VERSION "WangHu V1.0"

NS_ :

BS_:

BU_: SBCU MBCU Tester Monitor01

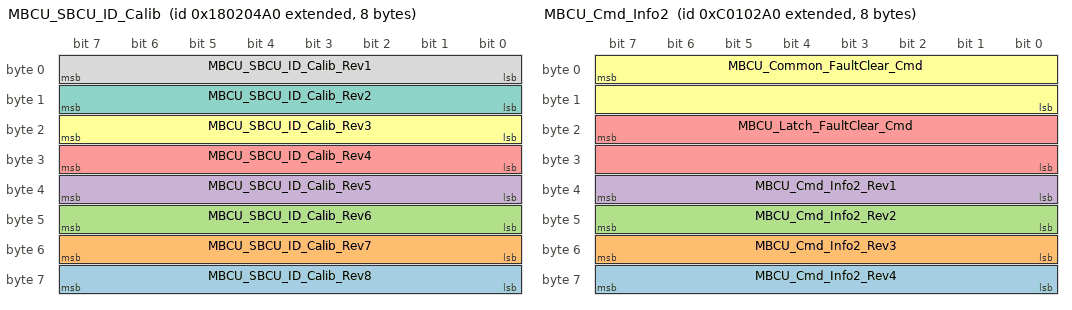
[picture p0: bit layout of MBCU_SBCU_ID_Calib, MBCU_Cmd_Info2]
BO_ 2550269088 MBCU_SBCU_ID_Calib: 8 MBCU
 SG_ MBCU_SBCU_ID_Calib_Rev8 : 63|8@0+ (1,0) [0|0] ""  SBCU
 SG_ MBCU_SBCU_ID_Calib_Rev7 : 55|8@0+ (1,0) [0|0] ""  SBCU
 SG_ MBCU_SBCU_ID_Calib_Rev6 : 47|8@0+ (1,0) [0|0] ""  SBCU
 SG_ MBCU_SBCU_ID_Calib_Rev5 : 39|8@0+ (1,0) [0|0] ""  SBCU
 SG_ MBCU_SBCU_ID_Calib_Rev4 : 31|8@0+ (1,0) [0|0] ""  SBCU
 SG_ MBCU_SBCU_ID_Calib_Rev3 : 23|8@0+ (1,0) [0|0] ""  SBCU
 SG_ MBCU_SBCU_ID_Calib_Rev2 : 15|8@0+ (1,0) [0|0] ""  SBCU
 SG_ MBCU_SBCU_ID_Calib_Rev1 : 7|8@0+ (1,0) [0|0] ""  SBCU

BO_ 2348876448 MBCU_Cmd_Info2: 8 MBCU
 SG_ MBCU_Cmd_Info2_Rev4 : 63|8@0+ (1,0) [0|255] ""  SBCU
 SG_ MBCU_Cmd_Info2_Rev3 : 55|8@0+ (1,0) [0|255] ""  SBCU
 SG_ MBCU_Cmd_Info2_Rev2 : 47|8@0+ (1,0) [0|255] ""  SBCU
 SG_ MBCU_Cmd_Info2_Rev1 : 39|8@0+ (1,0) [0|255] ""  SBCU
 SG_ MBCU_Latch_FaultClear_Cmd : 23|16@0+ (1,0) [0|65535] ""  SBCU
 SG_ MBCU_Common_FaultClear_Cmd : 7|16@0+ (1,0) [0|65535] ""  SBCU

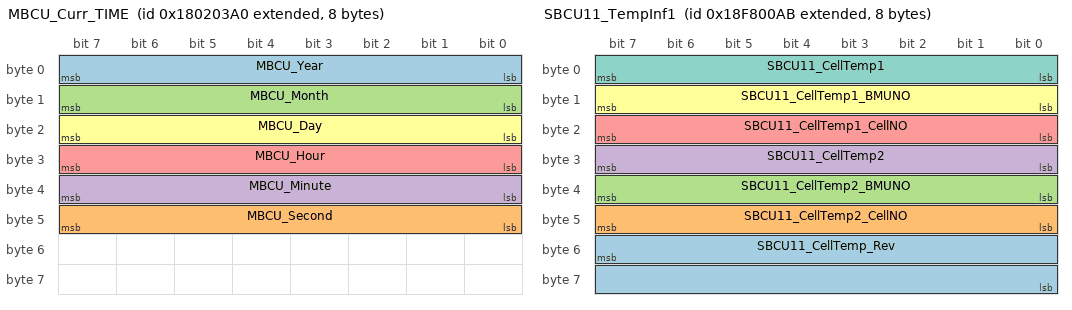
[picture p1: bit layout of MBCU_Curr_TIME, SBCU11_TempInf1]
BO_ 2550268832 MBCU_Curr_TIME: 8 MBCU
 SG_ MBCU_Year : 7|8@0+ (1,1900) [1900|2155] ""  SBCU
 SG_ MBCU_Second : 47|8@0+ (1,0) [0|59] ""  SBCU
 SG_ MBCU_Month : 15|8@0+ (1,0) [0|12] ""  SBCU
 SG_ MBCU_Minute : 39|8@0+ (1,0) [0|59] ""  SBCU
 SG_ MBCU_Hour : 31|8@0+ (1,0) [0|23] ""  SBCU
 SG_ MBCU_Day : 23|8@0+ (1,0) [0|31] ""  SBCU

BO_ 2566389931 SBCU11_TempInf1: 8 SBCU
 SG_ SBCU11_CellTemp_Rev : 55|16@0+ (1,0) [0|65535] ""  MBCU
 SG_ SBCU11_CellTemp2_CellNO : 47|8@0+ (1,0) [0|0] ""  MBCU
 SG_ SBCU11_CellTemp2_BMUNO : 39|8@0+ (1,0) [0|0] ""  MBCU
 SG_ SBCU11_CellTemp2 : 31|8@0+ (1,-40) [0|0] "��"  MBCU
 SG_ SBCU11_CellTemp1_CellNO : 23|8@0+ (1,0) [0|0] ""  MBCU
 SG_ SBCU11_CellTemp1_BMUNO : 15|8@0+ (1,0) [0|0] ""  MBCU
 SG_ SBCU11_CellTemp1 : 7|8@0+ (1,-40) [0|0] "��"  MBCU

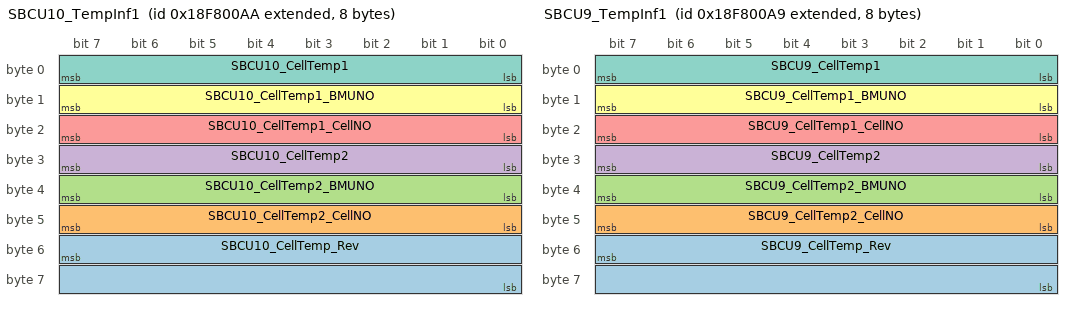
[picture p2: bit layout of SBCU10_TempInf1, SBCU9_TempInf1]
BO_ 2566389930 SBCU10_TempInf1: 8 SBCU
 SG_ SBCU10_CellTemp_Rev : 55|16@0+ (1,0) [0|65535] ""  MBCU
 SG_ SBCU10_CellTemp2_CellNO : 47|8@0+ (1,0) [0|0] ""  MBCU
 SG_ SBCU10_CellTemp2_BMUNO : 39|8@0+ (1,0) [0|0] ""  MBCU
 SG_ SBCU10_CellTemp2 : 31|8@0+ (1,-40) [0|0] "��"  MBCU
 SG_ SBCU10_CellTemp1_CellNO : 23|8@0+ (1,0) [0|0] ""  MBCU
 SG_ SBCU10_CellTemp1_BMUNO : 15|8@0+ (1,0) [0|0] ""  MBCU
 SG_ SBCU10_CellTemp1 : 7|8@0+ (1,-40) [0|0] "��"  MBCU

BO_ 2566389929 SBCU9_TempInf1: 8 SBCU
 SG_ SBCU9_CellTemp_Rev : 55|16@0+ (1,0) [0|65535] ""  MBCU
 SG_ SBCU9_CellTemp2_CellNO : 47|8@0+ (1,0) [0|0] ""  MBCU
 SG_ SBCU9_CellTemp2_BMUNO : 39|8@0+ (1,0) [0|0] ""  MBCU
 SG_ SBCU9_CellTemp2 : 31|8@0+ (1,-40) [0|0] "��"  MBCU
 SG_ SBCU9_CellTemp1_CellNO : 23|8@0+ (1,0) [0|0] ""  MBCU
 SG_ SBCU9_CellTemp1_BMUNO : 15|8@0+ (1,0) [0|0] ""  MBCU
 SG_ SBCU9_CellTemp1 : 7|8@0+ (1,-40) [0|0] "��"  MBCU

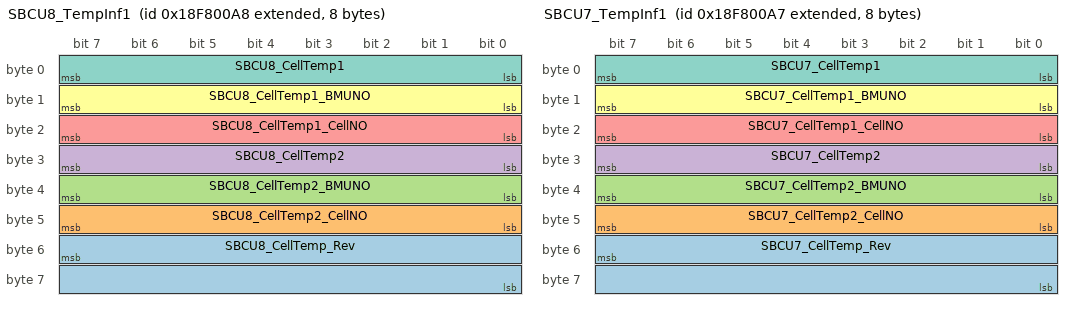
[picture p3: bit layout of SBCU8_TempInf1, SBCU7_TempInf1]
BO_ 2566389928 SBCU8_TempInf1: 8 SBCU
 SG_ SBCU8_CellTemp_Rev : 55|16@0+ (1,0) [0|65535] ""  MBCU
 SG_ SBCU8_CellTemp2_CellNO : 47|8@0+ (1,0) [0|0] ""  MBCU
 SG_ SBCU8_CellTemp2_BMUNO : 39|8@0+ (1,0) [0|0] ""  MBCU
 SG_ SBCU8_CellTemp2 : 31|8@0+ (1,-40) [0|0] "��"  MBCU
 SG_ SBCU8_CellTemp1_CellNO : 23|8@0+ (1,0) [0|0] ""  MBCU
 SG_ SBCU8_CellTemp1_BMUNO : 15|8@0+ (1,0) [0|0] ""  MBCU
 SG_ SBCU8_CellTemp1 : 7|8@0+ (1,-40) [0|0] "��"  MBCU

BO_ 2566389927 SBCU7_TempInf1: 8 SBCU
 SG_ SBCU7_CellTemp_Rev : 55|16@0+ (1,0) [0|65535] ""  MBCU
 SG_ SBCU7_CellTemp2_CellNO : 47|8@0+ (1,0) [0|0] ""  MBCU
 SG_ SBCU7_CellTemp2_BMUNO : 39|8@0+ (1,0) [0|0] ""  MBCU
 SG_ SBCU7_CellTemp2 : 31|8@0+ (1,-40) [0|0] "��"  MBCU
 SG_ SBCU7_CellTemp1_CellNO : 23|8@0+ (1,0) [0|0] ""  MBCU
 SG_ SBCU7_CellTemp1_BMUNO : 15|8@0+ (1,0) [0|0] ""  MBCU
 SG_ SBCU7_CellTemp1 : 7|8@0+ (1,-40) [0|0] "��"  MBCU

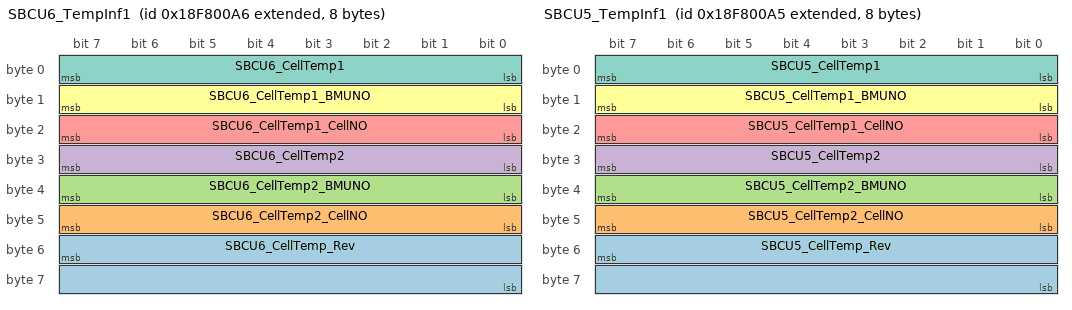
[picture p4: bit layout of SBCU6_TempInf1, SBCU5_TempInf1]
BO_ 2566389926 SBCU6_TempInf1: 8 SBCU
 SG_ SBCU6_CellTemp_Rev : 55|16@0+ (1,0) [0|65535] ""  MBCU
 SG_ SBCU6_CellTemp2_CellNO : 47|8@0+ (1,0) [0|0] ""  MBCU
 SG_ SBCU6_CellTemp2_BMUNO : 39|8@0+ (1,0) [0|0] ""  MBCU
 SG_ SBCU6_CellTemp2 : 31|8@0+ (1,-40) [0|0] "��"  MBCU
 SG_ SBCU6_CellTemp1_CellNO : 23|8@0+ (1,0) [0|0] ""  MBCU
 SG_ SBCU6_CellTemp1_BMUNO : 15|8@0+ (1,0) [0|0] ""  MBCU
 SG_ SBCU6_CellTemp1 : 7|8@0+ (1,-40) [0|0] "��"  MBCU

BO_ 2566389925 SBCU5_TempInf1: 8 SBCU
 SG_ SBCU5_CellTemp_Rev : 55|16@0+ (1,0) [0|65535] ""  MBCU
 SG_ SBCU5_CellTemp2_CellNO : 47|8@0+ (1,0) [0|0] ""  MBCU
 SG_ SBCU5_CellTemp2_BMUNO : 39|8@0+ (1,0) [0|0] ""  MBCU
 SG_ SBCU5_CellTemp2 : 31|8@0+ (1,-40) [0|0] "��"  MBCU
 SG_ SBCU5_CellTemp1_CellNO : 23|8@0+ (1,0) [0|0] ""  MBCU
 SG_ SBCU5_CellTemp1_BMUNO : 15|8@0+ (1,0) [0|0] ""  MBCU
 SG_ SBCU5_CellTemp1 : 7|8@0+ (1,-40) [0|0] "��"  MBCU

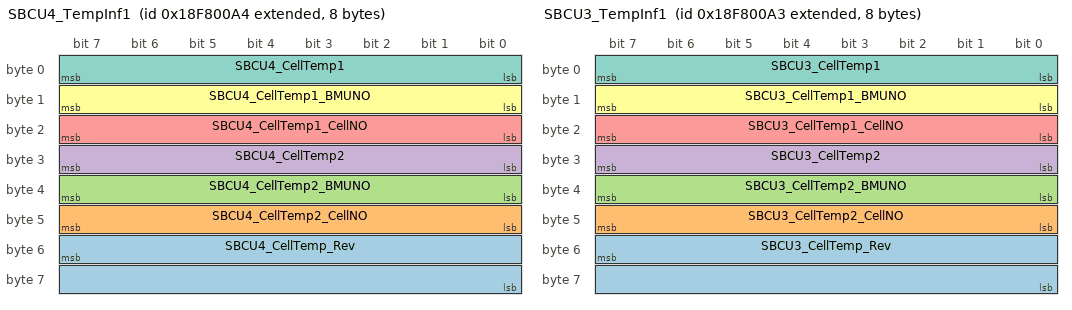
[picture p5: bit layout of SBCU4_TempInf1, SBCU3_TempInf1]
BO_ 2566389924 SBCU4_TempInf1: 8 SBCU
 SG_ SBCU4_CellTemp_Rev : 55|16@0+ (1,0) [0|65535] ""  MBCU
 SG_ SBCU4_CellTemp2_CellNO : 47|8@0+ (1,0) [0|0] ""  MBCU
 SG_ SBCU4_CellTemp2_BMUNO : 39|8@0+ (1,0) [0|0] ""  MBCU
 SG_ SBCU4_CellTemp2 : 31|8@0+ (1,-40) [0|0] "��"  MBCU
 SG_ SBCU4_CellTemp1_CellNO : 23|8@0+ (1,0) [0|0] ""  MBCU
 SG_ SBCU4_CellTemp1_BMUNO : 15|8@0+ (1,0) [0|0] ""  MBCU
 SG_ SBCU4_CellTemp1 : 7|8@0+ (1,-40) [0|0] "��"  MBCU

BO_ 2566389923 SBCU3_TempInf1: 8 SBCU
 SG_ SBCU3_CellTemp_Rev : 55|16@0+ (1,0) [0|65535] ""  MBCU
 SG_ SBCU3_CellTemp2_CellNO : 47|8@0+ (1,0) [0|0] ""  MBCU
 SG_ SBCU3_CellTemp2_BMUNO : 39|8@0+ (1,0) [0|0] ""  MBCU
 SG_ SBCU3_CellTemp2 : 31|8@0+ (1,-40) [0|0] "��"  MBCU
 SG_ SBCU3_CellTemp1_CellNO : 23|8@0+ (1,0) [0|0] ""  MBCU
 SG_ SBCU3_CellTemp1_BMUNO : 15|8@0+ (1,0) [0|0] ""  MBCU
 SG_ SBCU3_CellTemp1 : 7|8@0+ (1,-40) [0|0] "��"  MBCU

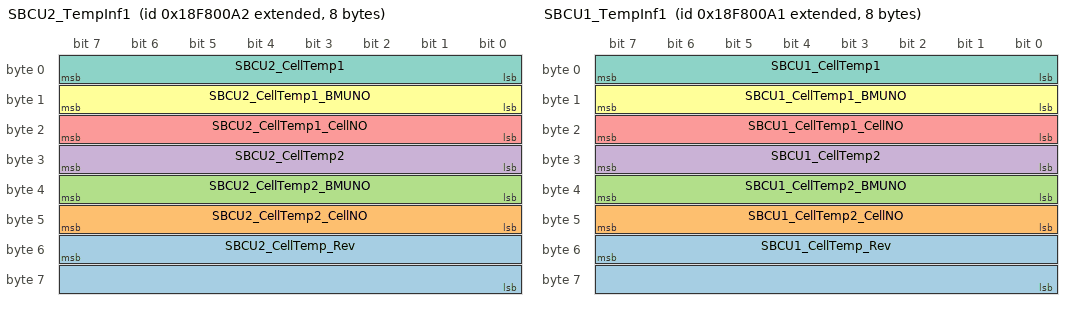
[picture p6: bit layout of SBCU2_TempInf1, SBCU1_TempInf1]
BO_ 2566389922 SBCU2_TempInf1: 8 SBCU
 SG_ SBCU2_CellTemp_Rev : 55|16@0+ (1,0) [0|65535] ""  MBCU
 SG_ SBCU2_CellTemp2_CellNO : 47|8@0+ (1,0) [0|0] ""  MBCU
 SG_ SBCU2_CellTemp2_BMUNO : 39|8@0+ (1,0) [0|0] ""  MBCU
 SG_ SBCU2_CellTemp2 : 31|8@0+ (1,-40) [0|0] "��"  MBCU
 SG_ SBCU2_CellTemp1_CellNO : 23|8@0+ (1,0) [0|0] ""  MBCU
 SG_ SBCU2_CellTemp1_BMUNO : 15|8@0+ (1,0) [0|0] ""  MBCU
 SG_ SBCU2_CellTemp1 : 7|8@0+ (1,-40) [0|0] "��"  MBCU

BO_ 2566389921 SBCU1_TempInf1: 8 SBCU
 SG_ SBCU1_CellTemp_Rev : 55|16@0+ (1,0) [0|65535] ""  MBCU
 SG_ SBCU1_CellTemp2_CellNO : 47|8@0+ (1,0) [0|0] ""  MBCU
 SG_ SBCU1_CellTemp2_BMUNO : 39|8@0+ (1,0) [0|0] ""  MBCU
 SG_ SBCU1_CellTemp2 : 31|8@0+ (1,-40) [0|0] "��"  MBCU
 SG_ SBCU1_CellTemp1_CellNO : 23|8@0+ (1,0) [0|0] ""  MBCU
 SG_ SBCU1_CellTemp1_BMUNO : 15|8@0+ (1,0) [0|0] ""  MBCU
 SG_ SBCU1_CellTemp1 : 7|8@0+ (1,-40) [0|0] "��"  MBCU

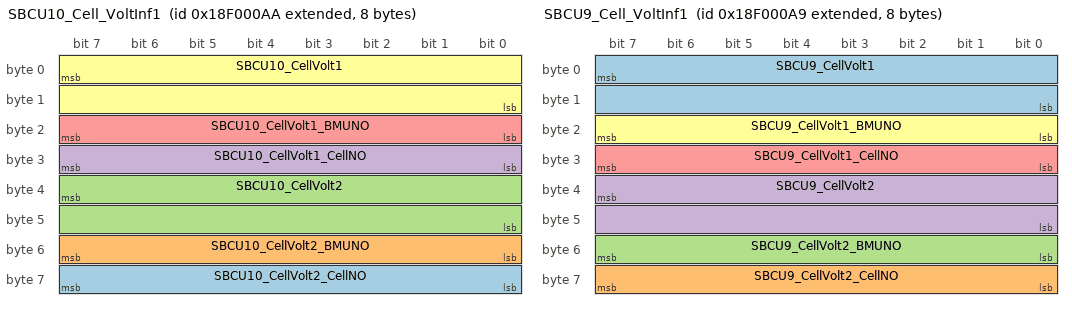
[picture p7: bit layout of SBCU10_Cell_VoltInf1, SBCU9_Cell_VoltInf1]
BO_ 2565865642 SBCU10_Cell_VoltInf1: 8 SBCU
 SG_ SBCU10_CellVolt2_CellNO : 63|8@0+ (1,0) [0|0] ""  MBCU
 SG_ SBCU10_CellVolt2_BMUNO : 55|8@0+ (1,0) [0|0] ""  MBCU
 SG_ SBCU10_CellVolt2 : 39|16@0+ (0.001,0) [0|0] "V"  MBCU
 SG_ SBCU10_CellVolt1_CellNO : 31|8@0+ (1,0) [0|0] ""  MBCU
 SG_ SBCU10_CellVolt1_BMUNO : 23|8@0+ (1,0) [0|0] ""  MBCU
 SG_ SBCU10_CellVolt1 : 7|16@0+ (0.001,0) [0|0] "V"  MBCU

BO_ 2565865641 SBCU9_Cell_VoltInf1: 8 SBCU
 SG_ SBCU9_CellVolt1 : 7|16@0+ (0.001,0) [0|0] "V"  MBCU
 SG_ SBCU9_CellVolt2_CellNO : 63|8@0+ (1,0) [0|0] ""  MBCU
 SG_ SBCU9_CellVolt2_BMUNO : 55|8@0+ (1,0) [0|0] ""  MBCU
 SG_ SBCU9_CellVolt2 : 39|16@0+ (0.001,0) [0|0] "V"  MBCU
 SG_ SBCU9_CellVolt1_CellNO : 31|8@0+ (1,0) [0|0] ""  MBCU
 SG_ SBCU9_CellVolt1_BMUNO : 23|8@0+ (1,0) [0|0] ""  MBCU

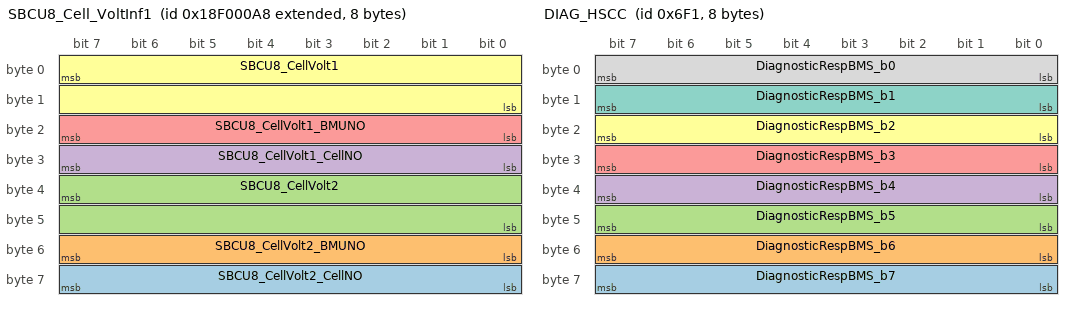
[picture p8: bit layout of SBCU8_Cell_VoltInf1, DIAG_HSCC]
BO_ 2565865640 SBCU8_Cell_VoltInf1: 8 SBCU
 SG_ SBCU8_CellVolt2_CellNO : 63|8@0+ (1,0) [0|0] ""  MBCU
 SG_ SBCU8_CellVolt2_BMUNO : 55|8@0+ (1,0) [0|0] ""  MBCU
 SG_ SBCU8_CellVolt2 : 39|16@0+ (0.001,0) [0|0] "V"  MBCU
 SG_ SBCU8_CellVolt1_CellNO : 31|8@0+ (1,0) [0|0] ""  MBCU
 SG_ SBCU8_CellVolt1_BMUNO : 23|8@0+ (1,0) [0|0] ""  MBCU
 SG_ SBCU8_CellVolt1 : 7|16@0+ (0.001,0) [0|0] "V"  MBCU

BO_ 2565865639 SBCU7_Cell_VoltInf1: 8 SBCU
 SG_ SBCU7_CellVolt2_CellNO : 63|8@0+ (1,0) [0|0] ""  MBCU
 SG_ SBCU7_CellVolt2_BMUNO : 55|8@0+ (1,0) [0|0] ""  MBCU
 SG_ SBCU7_CellVolt2 : 39|16@0+ (0.001,0) [0|0] "V"  MBCU
 SG_ SBCU7_CellVolt1_CellNO : 31|8@0+ (1,0) [0|0] ""  MBCU
 SG_ SBCU7_CellVolt1_BMUNO : 23|8@0+ (1,0) [0|0] ""  MBCU
 SG_ SBCU7_CellVolt1 : 7|16@0+ (0.001,0) [0|0] "V"  MBCU

BO_ 2565865638 SBCU6_Cell_VoltInf1: 8 SBCU
 SG_ SBCU6_CellVolt2_CellNO : 63|8@0+ (1,0) [0|0] ""  MBCU
 SG_ SBCU6_CellVolt2_BMUNO : 55|8@0+ (1,0) [0|0] ""  MBCU
 SG_ SBCU6_CellVolt2 : 39|16@0+ (0.001,0) [0|0] "V"  MBCU
 SG_ SBCU6_CellVolt1_CellNO : 31|8@0+ (1,0) [0|0] ""  MBCU
 SG_ SBCU6_CellVolt1_BMUNO : 23|8@0+ (1,0) [0|0] ""  MBCU
 SG_ SBCU6_CellVolt1 : 7|16@0+ (0.001,0) [0|0] "V"  MBCU

BO_ 2565865637 SBCU5_Cell_VoltInf1: 8 SBCU
 SG_ SBCU5_CellVolt2_CellNO : 63|8@0+ (1,0) [0|0] ""  MBCU
 SG_ SBCU5_CellVolt2_BMUNO : 55|8@0+ (1,0) [0|0] ""  MBCU
 SG_ SBCU5_CellVolt2 : 39|16@0+ (0.001,0) [0|0] "V"  MBCU
 SG_ SBCU5_CellVolt1_CellNO : 31|8@0+ (1,0) [0|0] ""  MBCU
 SG_ SBCU5_CellVolt1_BMUNO : 23|8@0+ (1,0) [0|0] ""  MBCU
 SG_ SBCU5_CellVolt1 : 7|16@0+ (0.001,0) [0|0] "V"  MBCU

BO_ 2565865636 SBCU4_Cell_VoltInf1: 8 SBCU
 SG_ SBCU4_CellVolt2_CellNO : 63|8@0+ (1,0) [0|0] ""  MBCU
 SG_ SBCU4_CellVolt2_BMUNO : 55|8@0+ (1,0) [0|0] ""  MBCU
 SG_ SBCU4_CellVolt2 : 39|16@0+ (0.001,0) [0|0] "V"  MBCU
 SG_ SBCU4_CellVolt1_CellNO : 31|8@0+ (1,0) [0|0] ""  MBCU
 SG_ SBCU4_CellVolt1_BMUNO : 23|8@0+ (1,0) [0|0] ""  MBCU
 SG_ SBCU4_CellVolt1 : 7|16@0+ (0.001,0) [0|0] "V"  MBCU

BO_ 2565865635 SBCU3_Cell_VoltInf1: 8 SBCU
 SG_ SBCU3_CellVolt2_CellNO : 63|8@0+ (1,0) [0|0] ""  MBCU
 SG_ SBCU3_CellVolt2_BMUNO : 55|8@0+ (1,0) [0|0] ""  MBCU
 SG_ SBCU3_CellVolt2 : 39|16@0+ (0.001,0) [0|0] "V"  MBCU
 SG_ SBCU3_CellVolt1_CellNO : 31|8@0+ (1,0) [0|0] ""  MBCU
 SG_ SBCU3_CellVolt1_BMUNO : 23|8@0+ (1,0) [0|0] ""  MBCU
 SG_ SBCU3_CellVolt1 : 7|16@0+ (0.001,0) [0|0] "V"  MBCU

BO_ 2565865634 SBCU2_Cell_VoltInf1: 8 SBCU
 SG_ SBCU2_CellVolt2_CellNO : 63|8@0+ (1,0) [0|0] ""  MBCU
 SG_ SBCU2_CellVolt2_BMUNO : 55|8@0+ (1,0) [0|0] ""  MBCU
 SG_ SBCU2_CellVolt2 : 39|16@0+ (0.001,0) [0|0] "V"  MBCU
 SG_ SBCU2_CellVolt1_CellNO : 31|8@0+ (1,0) [0|0] ""  MBCU
 SG_ SBCU2_CellVolt1_BMUNO : 23|8@0+ (1,0) [0|0] ""  MBCU
 SG_ SBCU2_CellVolt1 : 7|16@0+ (0.001,0) [0|0] "V"  MBCU

BO_ 2565865633 SBCU1_Cell_VoltInf1: 8 SBCU
 SG_ SBCU1_CellVolt2_CellNO : 63|8@0+ (1,0) [0|0] ""  MBCU
 SG_ SBCU1_CellVolt2_BMUNO : 55|8@0+ (1,0) [0|0] ""  MBCU
 SG_ SBCU1_CellVolt2 : 39|16@0+ (0.001,0) [0|0] "V"  MBCU
 SG_ SBCU1_CellVolt1_CellNO : 31|8@0+ (1,0) [0|0] ""  MBCU
 SG_ SBCU1_CellVolt1_BMUNO : 23|8@0+ (1,0) [0|0] ""  MBCU
 SG_ SBCU1_CellVolt1 : 7|16@0+ (0.001,0) [0|0] "V"  MBCU

BO_ 1777 DIAG_HSCC: 8 SBCU
 SG_ DiagnosticRespBMS_b7 : 63|8@0+ (1,0) [0|0] ""  Tester
 SG_ DiagnosticRespBMS_b6 : 55|8@0+ (1,0) [0|0] ""  Tester
 SG_ DiagnosticRespBMS_b5 : 47|8@0+ (1,0) [0|0] ""  Tester
 SG_ DiagnosticRespBMS_b4 : 39|8@0+ (1,0) [0|0] ""  Tester
 SG_ DiagnosticRespBMS_b3 : 31|8@0+ (1,0) [0|0] ""  Tester
 SG_ DiagnosticRespBMS_b2 : 23|8@0+ (1,0) [0|0] ""  Tester
 SG_ DiagnosticRespBMS_b1 : 15|8@0+ (1,0) [0|0] ""  Tester
 SG_ DiagnosticRespBMS_b0 : 7|8@0+ (1,0) [0|0] ""  Tester

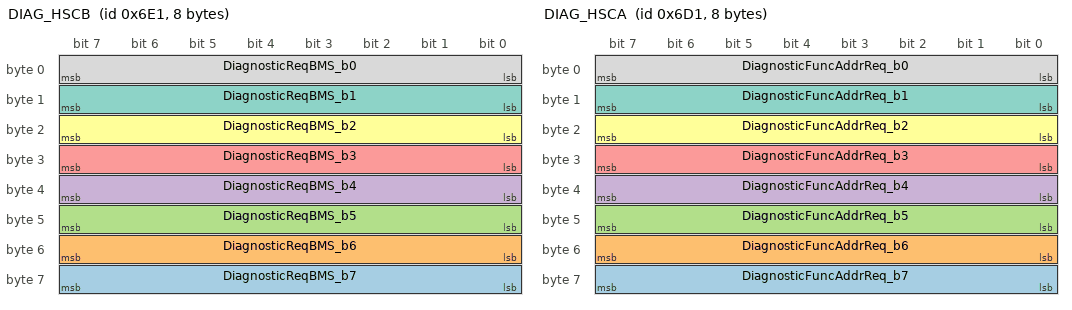
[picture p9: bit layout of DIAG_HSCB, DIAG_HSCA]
BO_ 1761 DIAG_HSCB: 8 Tester
 SG_ DiagnosticReqBMS_b7 : 63|8@0+ (1,0) [0|0] ""  SBCU
 SG_ DiagnosticReqBMS_b6 : 55|8@0+ (1,0) [0|0] ""  SBCU
 SG_ DiagnosticReqBMS_b5 : 47|8@0+ (1,0) [0|0] ""  SBCU
 SG_ DiagnosticReqBMS_b4 : 39|8@0+ (1,0) [0|0] ""  SBCU
 SG_ DiagnosticReqBMS_b3 : 31|8@0+ (1,0) [0|0] ""  SBCU
 SG_ DiagnosticReqBMS_b2 : 23|8@0+ (1,0) [0|0] ""  SBCU
 SG_ DiagnosticReqBMS_b1 : 15|8@0+ (1,0) [0|0] ""  SBCU
 SG_ DiagnosticReqBMS_b0 : 7|8@0+ (1,0) [0|0] ""  SBCU

BO_ 1745 DIAG_HSCA: 8 Tester
 SG_ DiagnosticFuncAddrReq_b7 : 63|8@0+ (1,0) [0|0] ""  SBCU
 SG_ DiagnosticFuncAddrReq_b6 : 55|8@0+ (1,0) [0|0] ""  SBCU
 SG_ DiagnosticFuncAddrReq_b5 : 47|8@0+ (1,0) [0|0] ""  SBCU
 SG_ DiagnosticFuncAddrReq_b4 : 39|8@0+ (1,0) [0|0] ""  SBCU
 SG_ DiagnosticFuncAddrReq_b3 : 31|8@0+ (1,0) [0|0] ""  SBCU
 SG_ DiagnosticFuncAddrReq_b2 : 23|8@0+ (1,0) [0|0] ""  SBCU
 SG_ DiagnosticFuncAddrReq_b1 : 15|8@0+ (1,0) [0|0] ""  SBCU
 SG_ DiagnosticFuncAddrReq_b0 : 7|8@0+ (1,0) [0|0] ""  SBCU

BO_ 2550898858 SBCU10_Statis_AccumEng: 8 SBCU
 SG_ SBCU10_Accum_DchEng : 7|32@0+ (0.1,0) [0|4000000000] "kWh"  MBCU
 SG_ SBCU10_Accum_ChgEng : 39|32@0+ (0.1,0) [0|4000000000] "kWh"  MBCU

BO_ 2550833322 SBCU10_Statis_AccumCap: 8 SBCU
 SG_ SBCU10_Accum_DchCap : 7|32@0+ (0.1,0) [0|4000000000] "Ah"  MBCU
 SG_ SBCU10_Accum_ChgCap : 39|32@0+ (0.1,0) [0|4000000000] "Ah"  MBCU

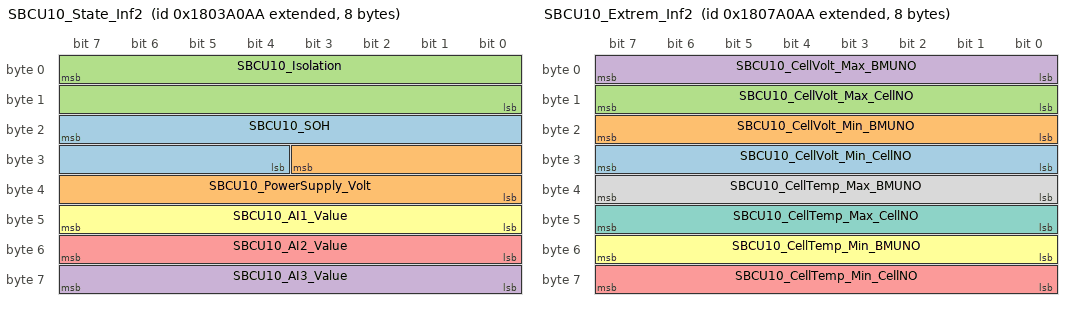
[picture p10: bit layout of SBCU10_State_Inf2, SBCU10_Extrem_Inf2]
BO_ 2550374570 SBCU10_State_Inf2: 8 SBCU
 SG_ SBCU10_SOH : 23|12@0+ (0.1,0) [0|0] "%"  MBCU
 SG_ SBCU10_PowerSupply_Volt : 27|12@0+ (0.1,0) [0|0] "V"  MBCU
 SG_ SBCU10_Isolation : 7|16@0+ (1,0) [0|65535] "kOhm"  MBCU
 SG_ SBCU10_AI3_Value : 63|8@0+ (1,0) [0|255] ""  MBCU
 SG_ SBCU10_AI2_Value : 55|8@0+ (1,0) [0|255] ""  MBCU
 SG_ SBCU10_AI1_Value : 47|8@0+ (1,0) [0|255] ""  MBCU

BO_ 2348982442 SBCU10_State_Inf1: 8 SBCU
 SG_ SBCU10_WorkMode : 11|4@0+ (1,0) [0|0] ""  MBCU
 SG_ SBCU10_Ready : 1|2@0+ (1,0) [0|0] ""  MBCU
 SG_ SBCU10_PreChgRelay_Status : 29|2@0+ (1,0) [0|0] ""  MBCU
 SG_ SBCU10_PosRelay_Status : 25|2@0+ (1,0) [0|0] ""  MBCU
 SG_ SBCU10_PosIso_Optical : 56|1@0+ (1,0) [0|0] ""  MBCU
 SG_ SBCU10_NegRelay_Status : 27|2@0+ (1,0) [0|0] ""  MBCU
 SG_ SBCU10_NegIso_Optical : 57|1@0+ (1,0) [0|0] ""  MBCU
 SG_ SBCU10_Life : 63|4@0+ (1,0) [0|0] ""  MBCU
 SG_ SBCU10_ISO_Status : 7|2@0+ (1,0) [0|3] ""  MBCU
 SG_ SBCU10_ISO_Allow : 5|2@0+ (1,0) [0|3] ""  MBCU
 SG_ SBCU10_HVOff_Req : 3|2@0+ (1,0) [0|0] ""  MBCU
 SG_ SBCU10_HV_Step : 15|4@0+ (1,0) [0|0] ""  MBCU
 SG_ SBCU10_HeatRelay_Status : 23|2@0+ (1,0) [0|0] ""  MBCU
 SG_ SBCU10_FcgRelay_Status : 31|2@0+ (1,0) [0|0] ""  MBCU
 SG_ SBCU10_FaultLevel : 59|2@0+ (1,0) [0|3] ""  MBCU
 SG_ SBCU10_FaultCode : 47|16@0+ (1,0) [0|65535] ""  MBCU
 SG_ SBCU10_FanRelay_Status : 21|2@0+ (1,0) [0|0] ""  MBCU
 SG_ SBCU10_DO3_Ctrl : 39|1@0+ (1,0) [0|0] ""  MBCU
 SG_ SBCU10_DO2_Ctrl : 38|1@0+ (1,0) [0|0] ""  MBCU
 SG_ SBCU10_DO1_Ctrl : 37|1@0+ (1,0) [0|0] ""  MBCU
 SG_ SBCU10_DI5_Status : 36|1@0+ (1,0) [0|0] ""  MBCU
 SG_ SBCU10_DI4_Status : 35|1@0+ (1,0) [0|0] ""  MBCU
 SG_ SBCU10_DI3_Status : 34|1@0+ (1,0) [0|0] ""  MBCU
 SG_ SBCU10_DI2_Status : 33|1@0+ (1,0) [0|0] ""  MBCU
 SG_ SBCU10_DI1_Status : 32|1@0+ (1,0) [0|0] ""  MBCU
 SG_ SBCU10_BMS_RunStatus : 19|4@0+ (1,0) [0|0] ""  MBCU

BO_ 2550505642 SBCU10_SOP_Inf2: 8 SBCU
 SG_ SBCU10_DchPeakPower_Limit : 7|16@0+ (0.1,0) [0|1000] "kW"  MBCU
 SG_ SBCU10_DchContinuousPower_Limit : 23|16@0+ (0.1,0) [0|1000] "kW"  MBCU
 SG_ SBCU10_ChgPeakPower_Limit : 39|16@0+ (0.1,0) [0|1000] "kW"  MBCU
 SG_ SBCU10_ChgContinuousPower_Limit : 55|16@0+ (0.1,0) [0|1000] "kW"  MBCU

BO_ 2550440106 SBCU10_SOP_Inf1: 8 SBCU
 SG_ SBCU10_DchPeakCurr_Limit : 7|16@0+ (0.1,0) [0|3200] "A"  MBCU
 SG_ SBCU10_DchContinuousCurr_Limit : 23|16@0+ (0.1,0) [0|3200] "A"  MBCU
 SG_ SBCU10_ChgPeakCurr_Limit : 39|16@0+ (0.1,0) [0|3200] "A"  MBCU
 SG_ SBCU10_ChgContinuousCurr_Limit : 55|16@0+ (0.1,0) [0|3200] "A"  MBCU

BO_ 2550636714 SBCU10_Extrem_Inf2: 8 SBCU
 SG_ SBCU10_CellVolt_Min_CellNO : 31|8@0+ (1,0) [0|255] ""  MBCU
 SG_ SBCU10_CellVolt_Min_BMUNO : 23|8@0+ (1,0) [0|16] ""  MBCU
 SG_ SBCU10_CellVolt_Max_CellNO : 15|8@0+ (1,0) [0|255] ""  MBCU
 SG_ SBCU10_CellVolt_Max_BMUNO : 7|8@0+ (1,0) [0|16] ""  MBCU
 SG_ SBCU10_CellTemp_Min_CellNO : 63|8@0+ (1,0) [0|255] ""  MBCU
 SG_ SBCU10_CellTemp_Min_BMUNO : 55|8@0+ (1,0) [0|16] ""  MBCU
 SG_ SBCU10_CellTemp_Max_CellNO : 47|8@0+ (1,0) [0|255] ""  MBCU
 SG_ SBCU10_CellTemp_Max_BMUNO : 39|8@0+ (1,0) [0|16] ""  MBCU

BO_ 2550571178 SBCU10_Extrem_Inf1: 8 SBCU
 SG_ SBCU10_CellVolt_Min : 23|16@0+ (0.001,0) [0|15] "V"  MBCU
 SG_ SBCU10_CellVolt_Mean : 39|16@0+ (0.001,0) [0|15] "V"  MBCU
 SG_ SBCU10_CellVolt_Max : 7|16@0+ (0.001,0) [0|15] "V"  MBCU
 SG_ SBCU10_CellTemp_Min : 63|8@0+ (1,-40) [0|0] "��"  MBCU
 SG_ SBCU10_CellTemp_Max : 55|8@0+ (1,-40) [0|0] "��"  MBCU

BO_ 2550702250 SBCU10_Debug_Inf: 8 SBCU
 SG_ SBCU10_NTC2 : 63|8@0+ (1,-40) [0|0] "��"  MBCU
 SG_ SBCU10_NTC1 : 55|8@0+ (1,-40) [0|0] "��"  MBCU
 SG_ SBCU10_ISO_PosVolt : 7|16@0+ (1,0) [0|65535] "mV"  MBCU
 SG_ SBCU10_ISO_NegVolt : 23|16@0+ (1,0) [0|65535] "mV"  MBCU
 SG_ SBCU10_CellVolt_Sum : 39|16@0+ (0.1,0) [0|0] "V"  MBCU

BO_ 2550898857 SBCU9_Statis_AccumEng: 8 SBCU
 SG_ SBCU9_Accum_DchEng : 7|32@0+ (0.1,0) [0|4000000000] "kWh"  MBCU
 SG_ SBCU9_Accum_ChgEng : 39|32@0+ (0.1,0) [0|4000000000] "kWh"  MBCU

BO_ 2550833321 SBCU9_Statis_AccumCap: 8 SBCU
 SG_ SBCU9_Accum_DchCap : 7|32@0+ (0.1,0) [0|4000000000] "Ah"  MBCU
 SG_ SBCU9_Accum_ChgCap : 39|32@0+ (0.1,0) [0|4000000000] "Ah"  MBCU

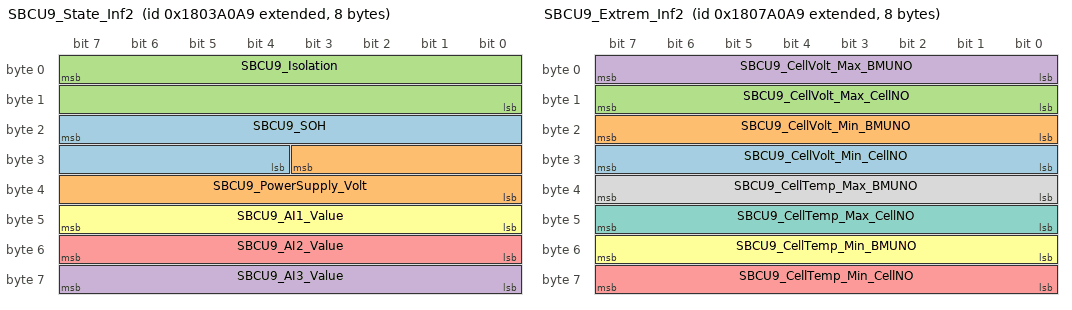
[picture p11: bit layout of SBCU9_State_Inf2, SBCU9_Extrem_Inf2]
BO_ 2550374569 SBCU9_State_Inf2: 8 SBCU
 SG_ SBCU9_SOH : 23|12@0+ (0.1,0) [0|0] "%"  MBCU
 SG_ SBCU9_PowerSupply_Volt : 27|12@0+ (0.1,0) [0|0] "V"  MBCU
 SG_ SBCU9_Isolation : 7|16@0+ (1,0) [0|65535] "kOhm"  MBCU
 SG_ SBCU9_AI3_Value : 63|8@0+ (1,0) [0|255] ""  MBCU
 SG_ SBCU9_AI2_Value : 55|8@0+ (1,0) [0|255] ""  MBCU
 SG_ SBCU9_AI1_Value : 47|8@0+ (1,0) [0|255] ""  MBCU

BO_ 2348982441 SBCU9_State_Inf1: 8 SBCU
 SG_ SBCU9_WorkMode : 11|4@0+ (1,0) [0|0] ""  MBCU
 SG_ SBCU9_Ready : 1|2@0+ (1,0) [0|0] ""  MBCU
 SG_ SBCU9_PreChgRelay_Status : 29|2@0+ (1,0) [0|0] ""  MBCU
 SG_ SBCU9_PosRelay_Status : 25|2@0+ (1,0) [0|0] ""  MBCU
 SG_ SBCU9_PosIso_Optical : 56|1@0+ (1,0) [0|0] ""  MBCU
 SG_ SBCU9_NegRelay_Status : 27|2@0+ (1,0) [0|0] ""  MBCU
 SG_ SBCU9_NegIso_Optical : 57|1@0+ (1,0) [0|0] ""  MBCU
 SG_ SBCU9_Life : 63|4@0+ (1,0) [0|0] ""  MBCU
 SG_ SBCU9_ISO_Status : 7|2@0+ (1,0) [0|3] ""  MBCU
 SG_ SBCU9_ISO_Allow : 5|2@0+ (1,0) [0|3] ""  MBCU
 SG_ SBCU9_HVOff_Req : 3|2@0+ (1,0) [0|0] ""  MBCU
 SG_ SBCU9_HV_Step : 15|4@0+ (1,0) [0|0] ""  MBCU
 SG_ SBCU9_HeatRelay_Status : 23|2@0+ (1,0) [0|0] ""  MBCU
 SG_ SBCU9_FcgRelay_Status : 31|2@0+ (1,0) [0|0] ""  MBCU
 SG_ SBCU9_FaultLevel : 59|2@0+ (1,0) [0|3] ""  MBCU
 SG_ SBCU9_FaultCode : 47|16@0+ (1,0) [0|65535] ""  MBCU
 SG_ SBCU9_FanRelay_Status : 21|2@0+ (1,0) [0|0] ""  MBCU
 SG_ SBCU9_DO3_Ctrl : 39|1@0+ (1,0) [0|0] ""  MBCU
 SG_ SBCU9_DO2_Ctrl : 38|1@0+ (1,0) [0|0] ""  MBCU
 SG_ SBCU9_DO1_Ctrl : 37|1@0+ (1,0) [0|0] ""  MBCU
 SG_ SBCU9_DI5_Status : 36|1@0+ (1,0) [0|0] ""  MBCU
 SG_ SBCU9_DI4_Status : 35|1@0+ (1,0) [0|0] ""  MBCU
 SG_ SBCU9_DI3_Status : 34|1@0+ (1,0) [0|0] ""  MBCU
 SG_ SBCU9_DI2_Status : 33|1@0+ (1,0) [0|0] ""  MBCU
 SG_ SBCU9_DI1_Status : 32|1@0+ (1,0) [0|0] ""  MBCU
 SG_ SBCU9_BMS_RunStatus : 19|4@0+ (1,0) [0|0] ""  MBCU

BO_ 2550505641 SBCU9_SOP_Inf2: 8 SBCU
 SG_ SBCU9_DchPeakPower_Limit : 7|16@0+ (0.1,0) [0|1000] "kW"  MBCU
 SG_ SBCU9_DchContinuousPower_Limit : 23|16@0+ (0.1,0) [0|1000] "kW"  MBCU
 SG_ SBCU9_ChgPeakPower_Limit : 39|16@0+ (0.1,0) [0|1000] "kW"  MBCU
 SG_ SBCU9_ChgContinuousPower_Limit : 55|16@0+ (0.1,0) [0|1000] "kW"  MBCU

BO_ 2550440105 SBCU9_SOP_Inf1: 8 SBCU
 SG_ SBCU9_DchPeakCurr_Limit : 7|16@0+ (0.1,0) [0|3200] "A"  MBCU
 SG_ SBCU9_DchContinuousCurr_Limit : 23|16@0+ (0.1,0) [0|3200] "A"  MBCU
 SG_ SBCU9_ChgPeakCurr_Limit : 39|16@0+ (0.1,0) [0|3200] "A"  MBCU
 SG_ SBCU9_ChgContinuousCurr_Limit : 55|16@0+ (0.1,0) [0|3200] "A"  MBCU

BO_ 2550636713 SBCU9_Extrem_Inf2: 8 SBCU
 SG_ SBCU9_CellVolt_Min_CellNO : 31|8@0+ (1,0) [0|255] ""  MBCU
 SG_ SBCU9_CellVolt_Min_BMUNO : 23|8@0+ (1,0) [0|16] ""  MBCU
 SG_ SBCU9_CellVolt_Max_CellNO : 15|8@0+ (1,0) [0|255] ""  MBCU
 SG_ SBCU9_CellVolt_Max_BMUNO : 7|8@0+ (1,0) [0|16] ""  MBCU
 SG_ SBCU9_CellTemp_Min_CellNO : 63|8@0+ (1,0) [0|255] ""  MBCU
 SG_ SBCU9_CellTemp_Min_BMUNO : 55|8@0+ (1,0) [0|16] ""  MBCU
 SG_ SBCU9_CellTemp_Max_CellNO : 47|8@0+ (1,0) [0|255] ""  MBCU
 SG_ SBCU9_CellTemp_Max_BMUNO : 39|8@0+ (1,0) [0|16] ""  MBCU

BO_ 2550571177 SBCU9_Extrem_Inf1: 8 SBCU
 SG_ SBCU9_CellVolt_Min : 23|16@0+ (0.001,0) [0|15] "V"  MBCU
 SG_ SBCU9_CellVolt_Mean : 39|16@0+ (0.001,0) [0|15] "V"  MBCU
 SG_ SBCU9_CellVolt_Max : 7|16@0+ (0.001,0) [0|15] "V"  MBCU
 SG_ SBCU9_CellTemp_Min : 63|8@0+ (1,-40) [0|0] "��"  MBCU
 SG_ SBCU9_CellTemp_Max : 55|8@0+ (1,-40) [0|0] "��"  MBCU

BO_ 2550702249 SBCU9_Debug_Inf: 8 SBCU
 SG_ SBCU9_NTC2 : 55|8@0+ (1,-40) [0|0] "��"  MBCU
 SG_ SBCU9_NTC1 : 63|8@0+ (1,-40) [0|0] "��"  MBCU
 SG_ SBCU9_ISO_PosVolt : 7|16@0+ (1,0) [0|65535] "mV"  MBCU
 SG_ SBCU9_ISO_NegVolt : 23|16@0+ (1,0) [0|65535] "mV"  MBCU
 SG_ SBCU9_CellVolt_Sum : 39|16@0+ (0.1,0) [0|0] "V"  MBCU

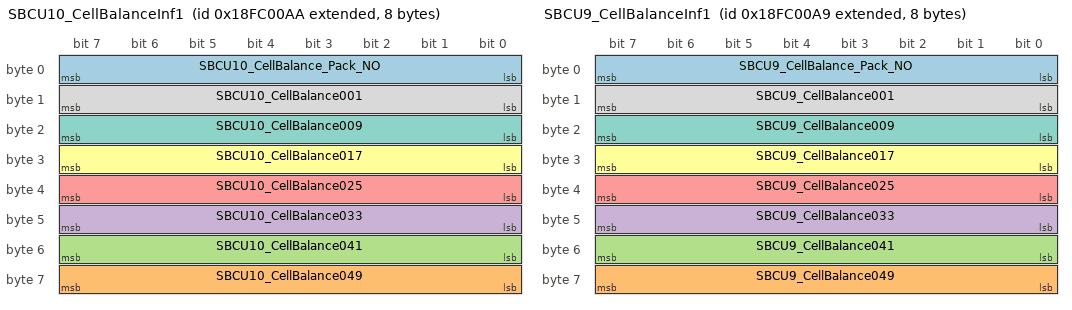
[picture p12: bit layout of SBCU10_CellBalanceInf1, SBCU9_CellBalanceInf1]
BO_ 2566652074 SBCU10_CellBalanceInf1: 8 SBCU
 SG_ SBCU10_CellBalance_Pack_NO : 7|8@0+ (1,0) [0|255] ""  MBCU
 SG_ SBCU10_CellBalance049 : 63|8@0+ (1,0) [0|255] ""  MBCU
 SG_ SBCU10_CellBalance041 : 55|8@0+ (1,0) [0|255] ""  MBCU
 SG_ SBCU10_CellBalance033 : 47|8@0+ (1,0) [0|255] ""  MBCU
 SG_ SBCU10_CellBalance025 : 39|8@0+ (1,0) [0|255] ""  MBCU
 SG_ SBCU10_CellBalance017 : 31|8@0+ (1,0) [0|255] ""  MBCU
 SG_ SBCU10_CellBalance009 : 23|8@0+ (1,0) [0|255] ""  MBCU
 SG_ SBCU10_CellBalance001 : 15|8@0+ (1,0) [0|255] ""  MBCU

BO_ 2566652073 SBCU9_CellBalanceInf1: 8 SBCU
 SG_ SBCU9_CellBalance_Pack_NO : 7|8@0+ (1,0) [0|255] ""  MBCU
 SG_ SBCU9_CellBalance049 : 63|8@0+ (1,0) [0|255] ""  MBCU
 SG_ SBCU9_CellBalance041 : 55|8@0+ (1,0) [0|255] ""  MBCU
 SG_ SBCU9_CellBalance033 : 47|8@0+ (1,0) [0|255] ""  MBCU
 SG_ SBCU9_CellBalance025 : 39|8@0+ (1,0) [0|255] ""  MBCU
 SG_ SBCU9_CellBalance017 : 31|8@0+ (1,0) [0|255] ""  MBCU
 SG_ SBCU9_CellBalance009 : 23|8@0+ (1,0) [0|255] ""  MBCU
 SG_ SBCU9_CellBalance001 : 15|8@0+ (1,0) [0|255] ""  MBCU

BO_ 2550243498 SBCU10_Basic_Inf: 8 SBCU
 SG_ SBCU10_SOC : 55|16@0+ (0.1,0) [0|100] "%"  MBCU
 SG_ SBCU10_Pack_Volt : 7|16@0+ (0.1,0) [0|2000] "V"  MBCU
 SG_ SBCU10_LinkVolt : 23|16@0+ (0.1,0) [0|2000] "V"  MBCU
 SG_ SBCU10_BusCurrent : 39|16@0+ (0.1,-3200) [0|0] "A"  MBCU

BO_ 2550243497 SBCU9_Basic_Inf: 8 SBCU
 SG_ SBCU9_SOC : 55|16@0+ (0.1,0) [0|100] "%"  MBCU
 SG_ SBCU9_Pack_Volt : 7|16@0+ (0.1,0) [0|2000] "V"  MBCU
 SG_ SBCU9_LinkVolt : 23|16@0+ (0.1,0) [0|2000] "V"  MBCU
 SG_ SBCU9_BusCurrent : 39|16@0+ (0.1,-3200) [0|0] "A"  MBCU

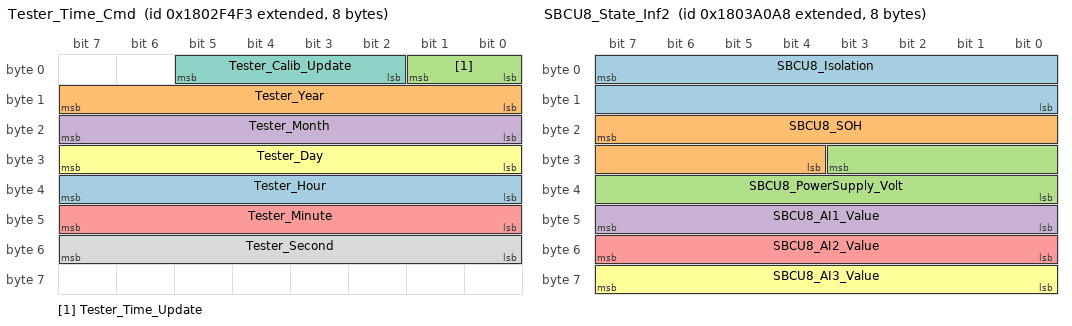
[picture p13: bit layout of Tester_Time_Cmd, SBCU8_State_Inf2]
BO_ 2550330611 Tester_Time_Cmd: 8 Tester
 SG_ Tester_Hour : 39|8@0+ (1,0) [0|1] ""  SBCU
 SG_ Tester_Year : 15|8@0+ (1,2000) [2000|2255] ""  SBCU
 SG_ Tester_Time_Update : 1|2@0+ (1,0) [0|3] ""  SBCU
 SG_ Tester_Month : 23|8@0+ (1,0) [0|1] ""  SBCU
 SG_ Tester_Minute : 47|8@0+ (1,0) [0|1] ""  SBCU
 SG_ Tester_Day : 31|8@0+ (1,0) [0|1] ""  SBCU
 SG_ Tester_Calib_Update : 5|4@0+ (1,0) [0|15] ""  SBCU
 SG_ Tester_Second : 55|8@0+ (1,0) [0|1] ""  SBCU

BO_ 2550898856 SBCU8_Statis_AccumEng: 8 SBCU
 SG_ SBCU8_Accum_DchEng : 7|32@0+ (0.1,0) [0|4000000000] "kWh"  MBCU
 SG_ SBCU8_Accum_ChgEng : 39|32@0+ (0.1,0) [0|4000000000] "kWh"  MBCU

BO_ 2550833320 SBCU8_Statis_AccumCap: 8 SBCU
 SG_ SBCU8_Accum_DchCap : 7|32@0+ (0.1,0) [0|4000000000] "Ah"  MBCU
 SG_ SBCU8_Accum_ChgCap : 39|32@0+ (0.1,0) [0|4000000000] "Ah"  MBCU

BO_ 2550374568 SBCU8_State_Inf2: 8 SBCU
 SG_ SBCU8_Isolation : 7|16@0+ (1,0) [0|65535] "kOhm"  MBCU
 SG_ SBCU8_SOH : 23|12@0+ (0.1,0) [0|0] "%"  MBCU
 SG_ SBCU8_PowerSupply_Volt : 27|12@0+ (0.1,0) [0|0] "V"  MBCU
 SG_ SBCU8_AI1_Value : 47|8@0+ (1,0) [0|255] ""  MBCU
 SG_ SBCU8_AI2_Value : 55|8@0+ (1,0) [0|255] ""  MBCU
 SG_ SBCU8_AI3_Value : 63|8@0+ (1,0) [0|255] ""  MBCU

BO_ 2348982440 SBCU8_State_Inf1: 8 SBCU
 SG_ SBCU8_ISO_Status : 7|2@0+ (1,0) [0|3] ""  MBCU
 SG_ SBCU8_DO3_Ctrl : 39|1@0+ (1,0) [0|0] ""  MBCU
 SG_ SBCU8_DI5_Status : 36|1@0+ (1,0) [0|0] ""  MBCU
 SG_ SBCU8_Ready : 1|2@0+ (1,0) [0|0] ""  MBCU
 SG_ SBCU8_HVOff_Req : 3|2@0+ (1,0) [0|0] ""  MBCU
 SG_ SBCU8_ISO_Allow : 5|2@0+ (1,0) [0|3] ""  MBCU
 SG_ SBCU8_WorkMode : 11|4@0+ (1,0) [0|0] ""  MBCU
 SG_ SBCU8_HV_Step : 15|4@0+ (1,0) [0|0] ""  MBCU
 SG_ SBCU8_BMS_RunStatus : 19|4@0+ (1,0) [0|0] ""  MBCU
 SG_ SBCU8_FanRelay_Status : 21|2@0+ (1,0) [0|0] ""  MBCU
 SG_ SBCU8_HeatRelay_Status : 23|2@0+ (1,0) [0|0] ""  MBCU
 SG_ SBCU8_PosRelay_Status : 25|2@0+ (1,0) [0|0] ""  MBCU
 SG_ SBCU8_NegRelay_Status : 27|2@0+ (1,0) [0|0] ""  MBCU
 SG_ SBCU8_PreChgRelay_Status : 29|2@0+ (1,0) [0|0] ""  MBCU
 SG_ SBCU8_FcgRelay_Status : 31|2@0+ (1,0) [0|0] ""  MBCU
 SG_ SBCU8_DI1_Status : 32|1@0+ (1,0) [0|0] ""  MBCU
 SG_ SBCU8_DI2_Status : 33|1@0+ (1,0) [0|0] ""  MBCU
 SG_ SBCU8_DI3_Status : 34|1@0+ (1,0) [0|0] ""  MBCU
 SG_ SBCU8_DI4_Status : 35|1@0+ (1,0) [0|0] ""  MBCU
 SG_ SBCU8_DO1_Ctrl : 37|1@0+ (1,0) [0|0] ""  MBCU
 SG_ SBCU8_DO2_Ctrl : 38|1@0+ (1,0) [0|0] ""  MBCU
 SG_ SBCU8_PosIso_Optical : 56|1@0+ (1,0) [0|0] ""  MBCU
 SG_ SBCU8_NegIso_Optical : 57|1@0+ (1,0) [0|0] ""  MBCU
 SG_ SBCU8_FaultCode : 47|16@0+ (1,0) [0|65535] ""  MBCU
 SG_ SBCU8_FaultLevel : 59|2@0+ (1,0) [0|3] ""  MBCU
 SG_ SBCU8_Life : 63|4@0+ (1,0) [0|0] ""  MBCU

BO_ 2550505640 SBCU8_SOP_Inf2: 8 SBCU
 SG_ SBCU8_DchPeakPower_Limit : 7|16@0+ (0.1,0) [0|1000] "kW"  MBCU
 SG_ SBCU8_DchContinuousPower_Limit : 23|16@0+ (0.1,0) [0|1000] "kW"  MBCU
 SG_ SBCU8_ChgPeakPower_Limit : 39|16@0+ (0.1,0) [0|1000] "kW"  MBCU
 SG_ SBCU8_ChgContinuousPower_Limit : 55|16@0+ (0.1,0) [0|1000] "kW"  MBCU

BO_ 2550440104 SBCU8_SOP_Inf1: 8 SBCU
 SG_ SBCU8_DchPeakCurr_Limit : 7|16@0+ (0.1,0) [0|3200] "A"  MBCU
 SG_ SBCU8_DchContinuousCurr_Limit : 23|16@0+ (0.1,0) [0|3200] "A"  MBCU
 SG_ SBCU8_ChgPeakCurr_Limit : 39|16@0+ (0.1,0) [0|3200] "A"  MBCU
 SG_ SBCU8_ChgContinuousCurr_Limit : 55|16@0+ (0.1,0) [0|3200] "A"  MBCU

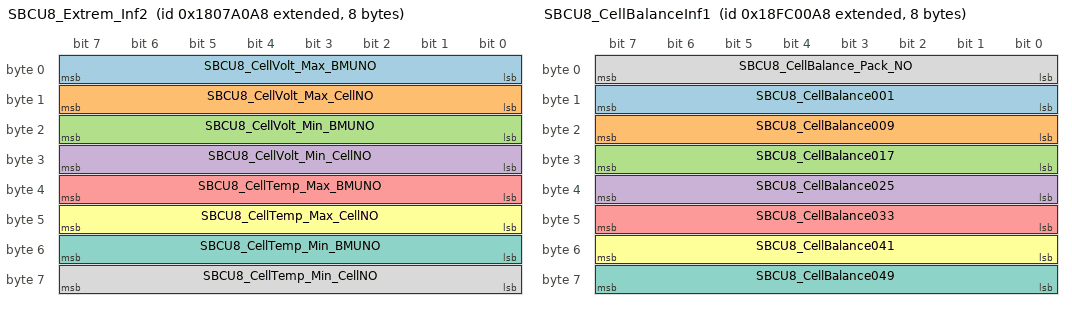
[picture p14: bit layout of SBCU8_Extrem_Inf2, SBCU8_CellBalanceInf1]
BO_ 2550636712 SBCU8_Extrem_Inf2: 8 SBCU
 SG_ SBCU8_CellVolt_Max_BMUNO : 7|8@0+ (1,0) [0|16] ""  MBCU
 SG_ SBCU8_CellVolt_Max_CellNO : 15|8@0+ (1,0) [0|255] ""  MBCU
 SG_ SBCU8_CellVolt_Min_BMUNO : 23|8@0+ (1,0) [0|16] ""  MBCU
 SG_ SBCU8_CellVolt_Min_CellNO : 31|8@0+ (1,0) [0|255] ""  MBCU
 SG_ SBCU8_CellTemp_Max_BMUNO : 39|8@0+ (1,0) [0|16] ""  MBCU
 SG_ SBCU8_CellTemp_Max_CellNO : 47|8@0+ (1,0) [0|255] ""  MBCU
 SG_ SBCU8_CellTemp_Min_BMUNO : 55|8@0+ (1,0) [0|16] ""  MBCU
 SG_ SBCU8_CellTemp_Min_CellNO : 63|8@0+ (1,0) [0|255] ""  MBCU

BO_ 2550571176 SBCU8_Extrem_Inf1: 8 SBCU
 SG_ SBCU8_CellVolt_Max : 7|16@0+ (0.001,0) [0|15] "V"  MBCU
 SG_ SBCU8_CellVolt_Min : 23|16@0+ (0.001,0) [0|15] "V"  MBCU
 SG_ SBCU8_CellVolt_Mean : 39|16@0+ (0.001,0) [0|15] "V"  MBCU
 SG_ SBCU8_CellTemp_Max : 55|8@0+ (1,-40) [0|0] "��"  MBCU
 SG_ SBCU8_CellTemp_Min : 63|8@0+ (1,-40) [0|0] "��"  MBCU

BO_ 2550702248 SBCU8_Debug_Inf: 8 SBCU
 SG_ SBCU8_NTC1 : 55|8@0+ (1,-40) [0|0] "��"  MBCU
 SG_ SBCU8_NTC2 : 63|8@0+ (1,-40) [0|0] "��"  MBCU
 SG_ SBCU8_ISO_PosVolt : 7|16@0+ (1,0) [0|65535] "mV"  MBCU
 SG_ SBCU8_ISO_NegVolt : 23|16@0+ (1,0) [0|65535] "mV"  MBCU
 SG_ SBCU8_CellVolt_Sum : 39|16@0+ (0.1,0) [0|0] "V"  MBCU

BO_ 2566652072 SBCU8_CellBalanceInf1: 8 SBCU
 SG_ SBCU8_CellBalance001 : 15|8@0+ (1,0) [0|255] ""  MBCU
 SG_ SBCU8_CellBalance009 : 23|8@0+ (1,0) [0|255] ""  MBCU
 SG_ SBCU8_CellBalance017 : 31|8@0+ (1,0) [0|255] ""  MBCU
 SG_ SBCU8_CellBalance025 : 39|8@0+ (1,0) [0|255] ""  MBCU
 SG_ SBCU8_CellBalance033 : 47|8@0+ (1,0) [0|255] ""  MBCU
 SG_ SBCU8_CellBalance041 : 55|8@0+ (1,0) [0|255] ""  MBCU
 SG_ SBCU8_CellBalance049 : 63|8@0+ (1,0) [0|255] ""  MBCU
 SG_ SBCU8_CellBalance_Pack_NO : 7|8@0+ (1,0) [0|255] ""  MBCU

BO_ 2550243496 SBCU8_Basic_Inf: 8 SBCU
 SG_ SBCU8_Pack_Volt : 7|16@0+ (0.1,0) [0|2000] "V"  MBCU
 SG_ SBCU8_LinkVolt : 23|16@0+ (0.1,0) [0|2000] "V"  MBCU
 SG_ SBCU8_BusCurrent : 39|16@0+ (0.1,-3200) [0|0] "A"  MBCU
 SG_ SBCU8_SOC : 55|16@0+ (0.1,0) [0|100] "%"  MBCU

BO_ 2550898855 SBCU7_Statis_AccumEng: 8 SBCU
 SG_ SBCU7_Accum_DchEng : 7|32@0+ (0.1,0) [0|4000000000] "kWh"  MBCU
 SG_ SBCU7_Accum_ChgEng : 39|32@0+ (0.1,0) [0|4000000000] "kWh"  MBCU

BO_ 2550833319 SBCU7_Statis_AccumCap: 8 SBCU
 SG_ SBCU7_Accum_DchCap : 7|32@0+ (0.1,0) [0|4000000000] "Ah"  MBCU
 SG_ SBCU7_Accum_ChgCap : 39|32@0+ (0.1,0) [0|4000000000] "Ah"  MBCU

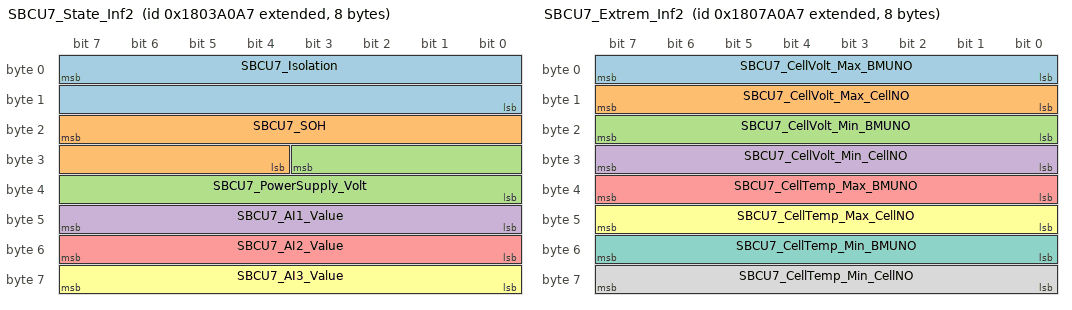
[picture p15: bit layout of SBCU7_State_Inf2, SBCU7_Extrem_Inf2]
BO_ 2550374567 SBCU7_State_Inf2: 8 SBCU
 SG_ SBCU7_Isolation : 7|16@0+ (1,0) [0|65535] "kOhm"  MBCU
 SG_ SBCU7_SOH : 23|12@0+ (0.1,0) [0|0] "%"  MBCU
 SG_ SBCU7_PowerSupply_Volt : 27|12@0+ (0.1,0) [0|0] "V"  MBCU
 SG_ SBCU7_AI1_Value : 47|8@0+ (1,0) [0|255] ""  MBCU
 SG_ SBCU7_AI2_Value : 55|8@0+ (1,0) [0|255] ""  MBCU
 SG_ SBCU7_AI3_Value : 63|8@0+ (1,0) [0|255] ""  MBCU

BO_ 2348982439 SBCU7_State_Inf1: 8 SBCU
 SG_ SBCU7_ISO_Status : 7|2@0+ (1,0) [0|3] ""  MBCU
 SG_ SBCU7_DO3_Ctrl : 39|1@0+ (1,0) [0|0] ""  MBCU
 SG_ SBCU7_DI5_Status : 36|1@0+ (1,0) [0|0] ""  MBCU
 SG_ SBCU7_Ready : 1|2@0+ (1,0) [0|0] ""  MBCU
 SG_ SBCU7_HVOff_Req : 3|2@0+ (1,0) [0|0] ""  MBCU
 SG_ SBCU7_ISO_Allow : 5|2@0+ (1,0) [0|3] ""  MBCU
 SG_ SBCU7_WorkMode : 11|4@0+ (1,0) [0|0] ""  MBCU
 SG_ SBCU7_HV_Step : 15|4@0+ (1,0) [0|0] ""  MBCU
 SG_ SBCU7_BMS_RunStatus : 19|4@0+ (1,0) [0|0] ""  MBCU
 SG_ SBCU7_FanRelay_Status : 21|2@0+ (1,0) [0|0] ""  MBCU
 SG_ SBCU7_HeatRelay_Status : 23|2@0+ (1,0) [0|0] ""  MBCU
 SG_ SBCU7_PosRelay_Status : 25|2@0+ (1,0) [0|0] ""  MBCU
 SG_ SBCU7_NegRelay_Status : 27|2@0+ (1,0) [0|0] ""  MBCU
 SG_ SBCU7_PreChgRelay_Status : 29|2@0+ (1,0) [0|0] ""  MBCU
 SG_ SBCU7_FcgRelay_Status : 31|2@0+ (1,0) [0|0] ""  MBCU
 SG_ SBCU7_DI1_Status : 32|1@0+ (1,0) [0|0] ""  MBCU
 SG_ SBCU7_DI2_Status : 33|1@0+ (1,0) [0|0] ""  MBCU
 SG_ SBCU7_DI3_Status : 34|1@0+ (1,0) [0|0] ""  MBCU
 SG_ SBCU7_DI4_Status : 35|1@0+ (1,0) [0|0] ""  MBCU
 SG_ SBCU7_DO1_Ctrl : 37|1@0+ (1,0) [0|0] ""  MBCU
 SG_ SBCU7_DO2_Ctrl : 38|1@0+ (1,0) [0|0] ""  MBCU
 SG_ SBCU7_PosIso_Optical : 56|1@0+ (1,0) [0|0] ""  MBCU
 SG_ SBCU7_NegIso_Optical : 57|1@0+ (1,0) [0|0] ""  MBCU
 SG_ SBCU7_FaultCode : 47|16@0+ (1,0) [0|65535] ""  MBCU
 SG_ SBCU7_FaultLevel : 59|2@0+ (1,0) [0|3] ""  MBCU
 SG_ SBCU7_Life : 63|4@0+ (1,0) [0|0] ""  MBCU

BO_ 2550505639 SBCU7_SOP_Inf2: 8 SBCU
 SG_ SBCU7_DchPeakPower_Limit : 7|16@0+ (0.1,0) [0|1000] "kW"  MBCU
 SG_ SBCU7_DchContinuousPower_Limit : 23|16@0+ (0.1,0) [0|1000] "kW"  MBCU
 SG_ SBCU7_ChgPeakPower_Limit : 39|16@0+ (0.1,0) [0|1000] "kW"  MBCU
 SG_ SBCU7_ChgContinuousPower_Limit : 55|16@0+ (0.1,0) [0|1000] "kW"  MBCU

BO_ 2550440103 SBCU7_SOP_Inf1: 8 SBCU
 SG_ SBCU7_DchPeakCurr_Limit : 7|16@0+ (0.1,0) [0|3200] "A"  MBCU
 SG_ SBCU7_DchContinuousCurr_Limit : 23|16@0+ (0.1,0) [0|3200] "A"  MBCU
 SG_ SBCU7_ChgPeakCurr_Limit : 39|16@0+ (0.1,0) [0|3200] "A"  MBCU
 SG_ SBCU7_ChgContinuousCurr_Limit : 55|16@0+ (0.1,0) [0|3200] "A"  MBCU

BO_ 2550636711 SBCU7_Extrem_Inf2: 8 SBCU
 SG_ SBCU7_CellVolt_Max_BMUNO : 7|8@0+ (1,0) [0|16] ""  MBCU
 SG_ SBCU7_CellVolt_Max_CellNO : 15|8@0+ (1,0) [0|255] ""  MBCU
 SG_ SBCU7_CellVolt_Min_BMUNO : 23|8@0+ (1,0) [0|16] ""  MBCU
 SG_ SBCU7_CellVolt_Min_CellNO : 31|8@0+ (1,0) [0|255] ""  MBCU
 SG_ SBCU7_CellTemp_Max_BMUNO : 39|8@0+ (1,0) [0|16] ""  MBCU
 SG_ SBCU7_CellTemp_Max_CellNO : 47|8@0+ (1,0) [0|255] ""  MBCU
 SG_ SBCU7_CellTemp_Min_BMUNO : 55|8@0+ (1,0) [0|16] ""  MBCU
 SG_ SBCU7_CellTemp_Min_CellNO : 63|8@0+ (1,0) [0|255] ""  MBCU

BO_ 2550571175 SBCU7_Extrem_Inf1: 8 SBCU
 SG_ SBCU7_CellVolt_Max : 7|16@0+ (0.001,0) [0|15] "V"  MBCU
 SG_ SBCU7_CellVolt_Min : 23|16@0+ (0.001,0) [0|15] "V"  MBCU
 SG_ SBCU7_CellVolt_Mean : 39|16@0+ (0.001,0) [0|15] "V"  MBCU
 SG_ SBCU7_CellTemp_Max : 55|8@0+ (1,-40) [0|0] "��"  MBCU
 SG_ SBCU7_CellTemp_Min : 63|8@0+ (1,-40) [0|0] "��"  MBCU

BO_ 2550702247 SBCU7_Debug_Inf: 8 SBCU
 SG_ SBCU7_NTC1 : 55|8@0+ (1,-40) [0|0] "��"  MBCU
 SG_ SBCU7_NTC2 : 63|8@0+ (1,-40) [0|0] "��"  MBCU
 SG_ SBCU7_ISO_PosVolt : 7|16@0+ (1,0) [0|65535] "mV"  MBCU
 SG_ SBCU7_ISO_NegVolt : 23|16@0+ (1,0) [0|65535] "mV"  MBCU
 SG_ SBCU7_CellVolt_Sum : 39|16@0+ (0.1,0) [0|0] "V"  MBCU

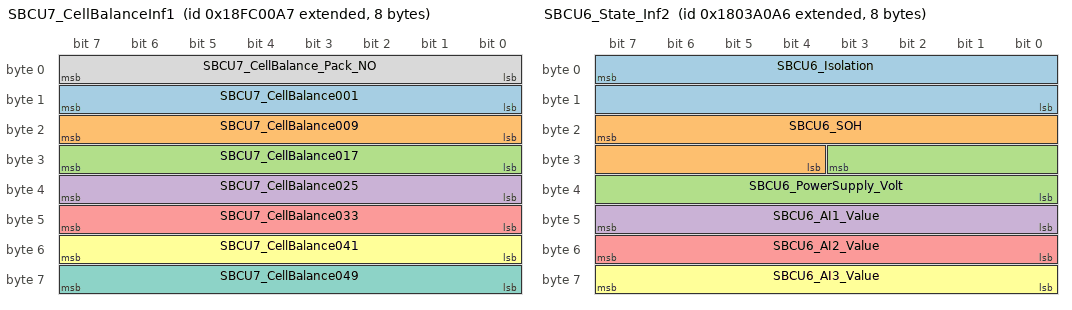
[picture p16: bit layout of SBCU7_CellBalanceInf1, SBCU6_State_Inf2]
BO_ 2566652071 SBCU7_CellBalanceInf1: 8 SBCU
 SG_ SBCU7_CellBalance001 : 15|8@0+ (1,0) [0|255] ""  MBCU
 SG_ SBCU7_CellBalance009 : 23|8@0+ (1,0) [0|255] ""  MBCU
 SG_ SBCU7_CellBalance017 : 31|8@0+ (1,0) [0|255] ""  MBCU
 SG_ SBCU7_CellBalance025 : 39|8@0+ (1,0) [0|255] ""  MBCU
 SG_ SBCU7_CellBalance033 : 47|8@0+ (1,0) [0|255] ""  MBCU
 SG_ SBCU7_CellBalance041 : 55|8@0+ (1,0) [0|255] ""  MBCU
 SG_ SBCU7_CellBalance049 : 63|8@0+ (1,0) [0|255] ""  MBCU
 SG_ SBCU7_CellBalance_Pack_NO : 7|8@0+ (1,0) [0|255] ""  MBCU

BO_ 2550243495 SBCU7_Basic_Inf: 8 SBCU
 SG_ SBCU7_Pack_Volt : 7|16@0+ (0.1,0) [0|2000] "V"  MBCU
 SG_ SBCU7_LinkVolt : 23|16@0+ (0.1,0) [0|2000] "V"  MBCU
 SG_ SBCU7_BusCurrent : 39|16@0+ (0.1,-3200) [0|0] "A"  MBCU
 SG_ SBCU7_SOC : 55|16@0+ (0.1,0) [0|100] "%"  MBCU

BO_ 2550898854 SBCU6_Statis_AccumEng: 8 SBCU
 SG_ SBCU6_Accum_DchEng : 7|32@0+ (0.1,0) [0|4000000000] "kWh"  MBCU
 SG_ SBCU6_Accum_ChgEng : 39|32@0+ (0.1,0) [0|4000000000] "kWh"  MBCU

BO_ 2550833318 SBCU6_Statis_AccumCap: 8 SBCU
 SG_ SBCU6_Accum_DchCap : 7|32@0+ (0.1,0) [0|4000000000] "Ah"  MBCU
 SG_ SBCU6_Accum_ChgCap : 39|32@0+ (0.1,0) [0|4000000000] "Ah"  MBCU

BO_ 2550374566 SBCU6_State_Inf2: 8 SBCU
 SG_ SBCU6_Isolation : 7|16@0+ (1,0) [0|65535] "kOhm"  MBCU
 SG_ SBCU6_SOH : 23|12@0+ (0.1,0) [0|0] "%"  MBCU
 SG_ SBCU6_PowerSupply_Volt : 27|12@0+ (0.1,0) [0|0] "V"  MBCU
 SG_ SBCU6_AI1_Value : 47|8@0+ (1,0) [0|255] ""  MBCU
 SG_ SBCU6_AI2_Value : 55|8@0+ (1,0) [0|255] ""  MBCU
 SG_ SBCU6_AI3_Value : 63|8@0+ (1,0) [0|255] ""  MBCU

BO_ 2348982438 SBCU6_State_Inf1: 8 SBCU
 SG_ SBCU6_ISO_Status : 7|2@0+ (1,0) [0|3] ""  MBCU
 SG_ SBCU6_DO3_Ctrl : 39|1@0+ (1,0) [0|0] ""  MBCU
 SG_ SBCU6_DI5_Status : 36|1@0+ (1,0) [0|0] ""  MBCU
 SG_ SBCU6_Ready : 1|2@0+ (1,0) [0|0] ""  MBCU
 SG_ SBCU6_HVOff_Req : 3|2@0+ (1,0) [0|0] ""  MBCU
 SG_ SBCU6_ISO_Allow : 5|2@0+ (1,0) [0|3] ""  MBCU
 SG_ SBCU6_WorkMode : 11|4@0+ (1,0) [0|0] ""  MBCU
 SG_ SBCU6_HV_Step : 15|4@0+ (1,0) [0|0] ""  MBCU
 SG_ SBCU6_BMS_RunStatus : 19|4@0+ (1,0) [0|0] ""  MBCU
 SG_ SBCU6_FanRelay_Status : 21|2@0+ (1,0) [0|0] ""  MBCU
 SG_ SBCU6_HeatRelay_Status : 23|2@0+ (1,0) [0|0] ""  MBCU
 SG_ SBCU6_PosRelay_Status : 25|2@0+ (1,0) [0|0] ""  MBCU
 SG_ SBCU6_NegRelay_Status : 27|2@0+ (1,0) [0|0] ""  MBCU
 SG_ SBCU6_PreChgRelay_Status : 29|2@0+ (1,0) [0|0] ""  MBCU
 SG_ SBCU6_FcgRelay_Status : 31|2@0+ (1,0) [0|0] ""  MBCU
 SG_ SBCU6_DI1_Status : 32|1@0+ (1,0) [0|0] ""  MBCU
 SG_ SBCU6_DI2_Status : 33|1@0+ (1,0) [0|0] ""  MBCU
 SG_ SBCU6_DI3_Status : 34|1@0+ (1,0) [0|0] ""  MBCU
 SG_ SBCU6_DI4_Status : 35|1@0+ (1,0) [0|0] ""  MBCU
 SG_ SBCU6_DO1_Ctrl : 37|1@0+ (1,0) [0|0] ""  MBCU
 SG_ SBCU6_DO2_Ctrl : 38|1@0+ (1,0) [0|0] ""  MBCU
 SG_ SBCU6_PosIso_Optical : 56|1@0+ (1,0) [0|0] ""  MBCU
 SG_ SBCU6_NegIso_Optical : 57|1@0+ (1,0) [0|0] ""  MBCU
 SG_ SBCU6_FaultCode : 47|16@0+ (1,0) [0|65535] ""  MBCU
 SG_ SBCU6_FaultLevel : 59|2@0+ (1,0) [0|3] ""  MBCU
 SG_ SBCU6_Life : 63|4@0+ (1,0) [0|0] ""  MBCU

BO_ 2550505638 SBCU6_SOP_Inf2: 8 SBCU
 SG_ SBCU6_DchPeakPower_Limit : 7|16@0+ (0.1,0) [0|1000] "kW"  MBCU
 SG_ SBCU6_DchContinuousPower_Limit : 23|16@0+ (0.1,0) [0|1000] "kW"  MBCU
 SG_ SBCU6_ChgPeakPower_Limit : 39|16@0+ (0.1,0) [0|1000] "kW"  MBCU
 SG_ SBCU6_ChgContinuousPower_Limit : 55|16@0+ (0.1,0) [0|1000] "kW"  MBCU

BO_ 2550440102 SBCU6_SOP_Inf1: 8 SBCU
 SG_ SBCU6_DchPeakCurr_Limit : 7|16@0+ (0.1,0) [0|3200] "A"  MBCU
 SG_ SBCU6_DchContinuousCurr_Limit : 23|16@0+ (0.1,0) [0|3200] "A"  MBCU
 SG_ SBCU6_ChgPeakCurr_Limit : 39|16@0+ (0.1,0) [0|3200] "A"  MBCU
 SG_ SBCU6_ChgContinuousCurr_Limit : 55|16@0+ (0.1,0) [0|3200] "A"  MBCU

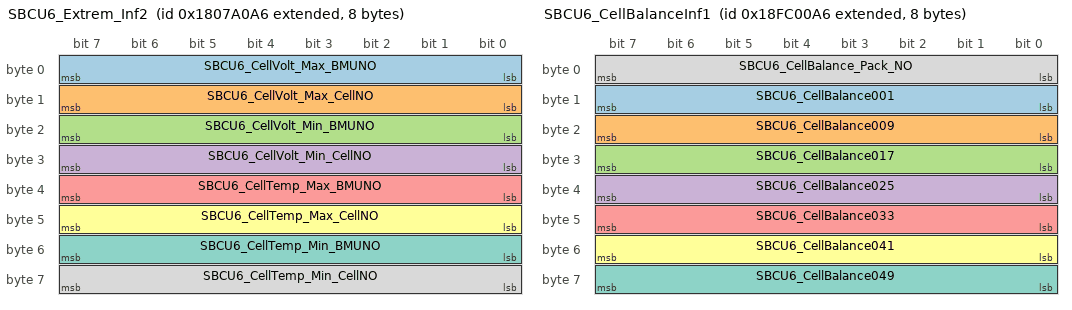
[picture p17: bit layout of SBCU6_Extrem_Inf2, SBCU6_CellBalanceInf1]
BO_ 2550636710 SBCU6_Extrem_Inf2: 8 SBCU
 SG_ SBCU6_CellVolt_Max_BMUNO : 7|8@0+ (1,0) [0|16] ""  MBCU
 SG_ SBCU6_CellVolt_Max_CellNO : 15|8@0+ (1,0) [0|255] ""  MBCU
 SG_ SBCU6_CellVolt_Min_BMUNO : 23|8@0+ (1,0) [0|16] ""  MBCU
 SG_ SBCU6_CellVolt_Min_CellNO : 31|8@0+ (1,0) [0|255] ""  MBCU
 SG_ SBCU6_CellTemp_Max_BMUNO : 39|8@0+ (1,0) [0|16] ""  MBCU
 SG_ SBCU6_CellTemp_Max_CellNO : 47|8@0+ (1,0) [0|255] ""  MBCU
 SG_ SBCU6_CellTemp_Min_BMUNO : 55|8@0+ (1,0) [0|16] ""  MBCU
 SG_ SBCU6_CellTemp_Min_CellNO : 63|8@0+ (1,0) [0|255] ""  MBCU

BO_ 2550571174 SBCU6_Extrem_Inf1: 8 SBCU
 SG_ SBCU6_CellVolt_Max : 7|16@0+ (0.001,0) [0|15] "V"  MBCU
 SG_ SBCU6_CellVolt_Min : 23|16@0+ (0.001,0) [0|15] "V"  MBCU
 SG_ SBCU6_CellVolt_Mean : 39|16@0+ (0.001,0) [0|15] "V"  MBCU
 SG_ SBCU6_CellTemp_Max : 55|8@0+ (1,-40) [0|0] "��"  MBCU
 SG_ SBCU6_CellTemp_Min : 63|8@0+ (1,-40) [0|0] "��"  MBCU

BO_ 2550702246 SBCU6_Debug_Inf: 8 SBCU
 SG_ SBCU6_NTC1 : 55|8@0+ (1,-40) [0|0] "��"  MBCU
 SG_ SBCU6_NTC2 : 63|8@0+ (1,-40) [0|0] "��"  MBCU
 SG_ SBCU6_ISO_PosVolt : 7|16@0+ (1,0) [0|65535] "mV"  MBCU
 SG_ SBCU6_ISO_NegVolt : 23|16@0+ (1,0) [0|65535] "mV"  MBCU
 SG_ SBCU6_CellVolt_Sum : 39|16@0+ (0.1,0) [0|0] "V"  MBCU

BO_ 2566652070 SBCU6_CellBalanceInf1: 8 SBCU
 SG_ SBCU6_CellBalance001 : 15|8@0+ (1,0) [0|255] ""  MBCU
 SG_ SBCU6_CellBalance009 : 23|8@0+ (1,0) [0|255] ""  MBCU
 SG_ SBCU6_CellBalance017 : 31|8@0+ (1,0) [0|255] ""  MBCU
 SG_ SBCU6_CellBalance025 : 39|8@0+ (1,0) [0|255] ""  MBCU
 SG_ SBCU6_CellBalance033 : 47|8@0+ (1,0) [0|255] ""  MBCU
 SG_ SBCU6_CellBalance041 : 55|8@0+ (1,0) [0|255] ""  MBCU
 SG_ SBCU6_CellBalance049 : 63|8@0+ (1,0) [0|255] ""  MBCU
 SG_ SBCU6_CellBalance_Pack_NO : 7|8@0+ (1,0) [0|255] ""  MBCU

BO_ 2550243494 SBCU6_Basic_Inf: 8 SBCU
 SG_ SBCU6_Pack_Volt : 7|16@0+ (0.1,0) [0|2000] "V"  MBCU
 SG_ SBCU6_LinkVolt : 23|16@0+ (0.1,0) [0|2000] "V"  MBCU
 SG_ SBCU6_BusCurrent : 39|16@0+ (0.1,-3200) [0|0] "A"  MBCU
 SG_ SBCU6_SOC : 55|16@0+ (0.1,0) [0|100] "%"  MBCU

BO_ 2550898853 SBCU5_Statis_AccumEng: 8 SBCU
 SG_ SBCU5_Accum_DchEng : 7|32@0+ (0.1,0) [0|4000000000] "kWh"  MBCU
 SG_ SBCU5_Accum_ChgEng : 39|32@0+ (0.1,0) [0|4000000000] "kWh"  MBCU

BO_ 2550833317 SBCU5_Statis_AccumCap: 8 SBCU
 SG_ SBCU5_Accum_DchCap : 7|32@0+ (0.1,0) [0|4000000000] "Ah"  MBCU
 SG_ SBCU5_Accum_ChgCap : 39|32@0+ (0.1,0) [0|4000000000] "Ah"  MBCU

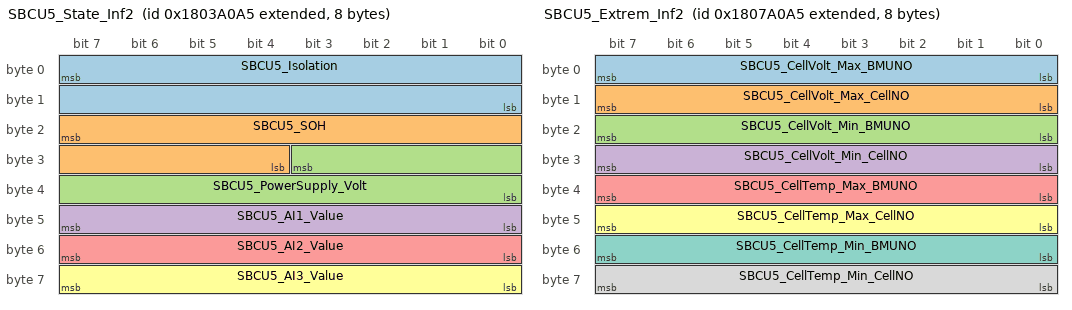
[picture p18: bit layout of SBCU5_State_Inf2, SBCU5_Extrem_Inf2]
BO_ 2550374565 SBCU5_State_Inf2: 8 SBCU
 SG_ SBCU5_Isolation : 7|16@0+ (1,0) [0|65535] "kOhm"  MBCU
 SG_ SBCU5_SOH : 23|12@0+ (0.1,0) [0|0] "%"  MBCU
 SG_ SBCU5_PowerSupply_Volt : 27|12@0+ (0.1,0) [0|0] "V"  MBCU
 SG_ SBCU5_AI1_Value : 47|8@0+ (1,0) [0|255] ""  MBCU
 SG_ SBCU5_AI2_Value : 55|8@0+ (1,0) [0|255] ""  MBCU
 SG_ SBCU5_AI3_Value : 63|8@0+ (1,0) [0|255] ""  MBCU

BO_ 2348982437 SBCU5_State_Inf1: 8 SBCU
 SG_ SBCU5_ISO_Status : 7|2@0+ (1,0) [0|3] ""  MBCU
 SG_ SBCU5_DO3_Ctrl : 39|1@0+ (1,0) [0|0] ""  MBCU
 SG_ SBCU5_DI5_Status : 36|1@0+ (1,0) [0|0] ""  MBCU
 SG_ SBCU5_Ready : 1|2@0+ (1,0) [0|0] ""  MBCU
 SG_ SBCU5_HVOff_Req : 3|2@0+ (1,0) [0|0] ""  MBCU
 SG_ SBCU5_ISO_Allow : 5|2@0+ (1,0) [0|3] ""  MBCU
 SG_ SBCU5_WorkMode : 11|4@0+ (1,0) [0|0] ""  MBCU
 SG_ SBCU5_HV_Step : 15|4@0+ (1,0) [0|0] ""  MBCU
 SG_ SBCU5_BMS_RunStatus : 19|4@0+ (1,0) [0|0] ""  MBCU
 SG_ SBCU5_FanRelay_Status : 21|2@0+ (1,0) [0|0] ""  MBCU
 SG_ SBCU5_HeatRelay_Status : 23|2@0+ (1,0) [0|0] ""  MBCU
 SG_ SBCU5_PosRelay_Status : 25|2@0+ (1,0) [0|0] ""  MBCU
 SG_ SBCU5_NegRelay_Status : 27|2@0+ (1,0) [0|0] ""  MBCU
 SG_ SBCU5_PreChgRelay_Status : 29|2@0+ (1,0) [0|0] ""  MBCU
 SG_ SBCU5_FcgRelay_Status : 31|2@0+ (1,0) [0|0] ""  MBCU
 SG_ SBCU5_DI1_Status : 32|1@0+ (1,0) [0|0] ""  MBCU
 SG_ SBCU5_DI2_Status : 33|1@0+ (1,0) [0|0] ""  MBCU
 SG_ SBCU5_DI3_Status : 34|1@0+ (1,0) [0|0] ""  MBCU
 SG_ SBCU5_DI4_Status : 35|1@0+ (1,0) [0|0] ""  MBCU
 SG_ SBCU5_DO1_Ctrl : 37|1@0+ (1,0) [0|0] ""  MBCU
 SG_ SBCU5_DO2_Ctrl : 38|1@0+ (1,0) [0|0] ""  MBCU
 SG_ SBCU5_PosIso_Optical : 56|1@0+ (1,0) [0|0] ""  MBCU
 SG_ SBCU5_NegIso_Optical : 57|1@0+ (1,0) [0|0] ""  MBCU
 SG_ SBCU5_FaultCode : 47|16@0+ (1,0) [0|65535] ""  MBCU
 SG_ SBCU5_FaultLevel : 59|2@0+ (1,0) [0|3] ""  MBCU
 SG_ SBCU5_Life : 63|4@0+ (1,0) [0|0] ""  MBCU

BO_ 2550505637 SBCU5_SOP_Inf2: 8 SBCU
 SG_ SBCU5_DchPeakPower_Limit : 7|16@0+ (0.1,0) [0|1000] "kW"  MBCU
 SG_ SBCU5_DchContinuousPower_Limit : 23|16@0+ (0.1,0) [0|1000] "kW"  MBCU
 SG_ SBCU5_ChgPeakPower_Limit : 39|16@0+ (0.1,0) [0|1000] "kW"  MBCU
 SG_ SBCU5_ChgContinuousPower_Limit : 55|16@0+ (0.1,0) [0|1000] "kW"  MBCU

BO_ 2550440101 SBCU5_SOP_Inf1: 8 SBCU
 SG_ SBCU5_DchPeakCurr_Limit : 7|16@0+ (0.1,0) [0|3200] "A"  MBCU
 SG_ SBCU5_DchContinuousCurr_Limit : 23|16@0+ (0.1,0) [0|3200] "A"  MBCU
 SG_ SBCU5_ChgPeakCurr_Limit : 39|16@0+ (0.1,0) [0|3200] "A"  MBCU
 SG_ SBCU5_ChgContinuousCurr_Limit : 55|16@0+ (0.1,0) [0|3200] "A"  MBCU

BO_ 2550636709 SBCU5_Extrem_Inf2: 8 SBCU
 SG_ SBCU5_CellVolt_Max_BMUNO : 7|8@0+ (1,0) [0|16] ""  MBCU
 SG_ SBCU5_CellVolt_Max_CellNO : 15|8@0+ (1,0) [0|255] ""  MBCU
 SG_ SBCU5_CellVolt_Min_BMUNO : 23|8@0+ (1,0) [0|16] ""  MBCU
 SG_ SBCU5_CellVolt_Min_CellNO : 31|8@0+ (1,0) [0|255] ""  MBCU
 SG_ SBCU5_CellTemp_Max_BMUNO : 39|8@0+ (1,0) [0|16] ""  MBCU
 SG_ SBCU5_CellTemp_Max_CellNO : 47|8@0+ (1,0) [0|255] ""  MBCU
 SG_ SBCU5_CellTemp_Min_BMUNO : 55|8@0+ (1,0) [0|16] ""  MBCU
 SG_ SBCU5_CellTemp_Min_CellNO : 63|8@0+ (1,0) [0|255] ""  MBCU

BO_ 2550571173 SBCU5_Extrem_Inf1: 8 SBCU
 SG_ SBCU5_CellVolt_Max : 7|16@0+ (0.001,0) [0|15] "V"  MBCU
 SG_ SBCU5_CellVolt_Min : 23|16@0+ (0.001,0) [0|15] "V"  MBCU
 SG_ SBCU5_CellVolt_Mean : 39|16@0+ (0.001,0) [0|15] "V"  MBCU
 SG_ SBCU5_CellTemp_Max : 55|8@0+ (1,-40) [0|0] "��"  MBCU
 SG_ SBCU5_CellTemp_Min : 63|8@0+ (1,-40) [0|0] "��"  MBCU

BO_ 2550702245 SBCU5_Debug_Inf: 8 SBCU
 SG_ SBCU5_NTC1 : 55|8@0+ (1,-40) [0|0] "��"  MBCU
 SG_ SBCU5_NTC2 : 63|8@0+ (1,-40) [0|0] "��"  MBCU
 SG_ SBCU5_ISO_PosVolt : 7|16@0+ (1,0) [0|65535] "mV"  MBCU
 SG_ SBCU5_ISO_NegVolt : 23|16@0+ (1,0) [0|65535] "mV"  MBCU
 SG_ SBCU5_CellVolt_Sum : 39|16@0+ (0.1,0) [0|0] "V"  MBCU

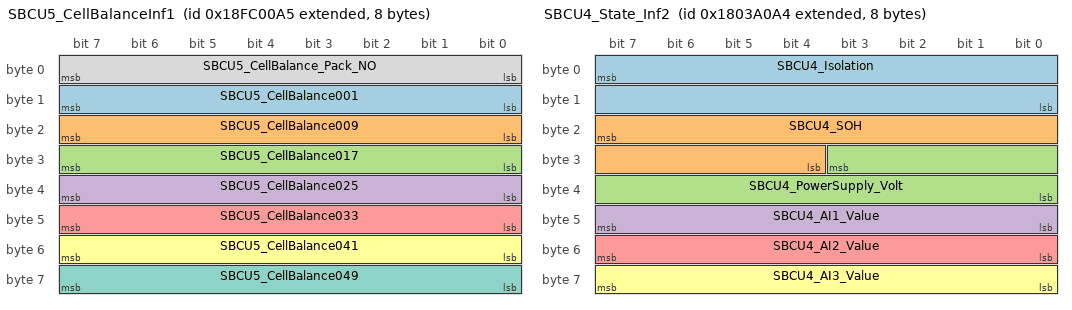
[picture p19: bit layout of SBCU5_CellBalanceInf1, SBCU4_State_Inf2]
BO_ 2566652069 SBCU5_CellBalanceInf1: 8 SBCU
 SG_ SBCU5_CellBalance001 : 15|8@0+ (1,0) [0|255] ""  MBCU
 SG_ SBCU5_CellBalance009 : 23|8@0+ (1,0) [0|255] ""  MBCU
 SG_ SBCU5_CellBalance017 : 31|8@0+ (1,0) [0|255] ""  MBCU
 SG_ SBCU5_CellBalance025 : 39|8@0+ (1,0) [0|255] ""  MBCU
 SG_ SBCU5_CellBalance033 : 47|8@0+ (1,0) [0|255] ""  MBCU
 SG_ SBCU5_CellBalance041 : 55|8@0+ (1,0) [0|255] ""  MBCU
 SG_ SBCU5_CellBalance049 : 63|8@0+ (1,0) [0|255] ""  MBCU
 SG_ SBCU5_CellBalance_Pack_NO : 7|8@0+ (1,0) [0|255] ""  MBCU

BO_ 2550243493 SBCU5_Basic_Inf: 8 SBCU
 SG_ SBCU5_Pack_Volt : 7|16@0+ (0.1,0) [0|2000] "V"  MBCU
 SG_ SBCU5_LinkVolt : 23|16@0+ (0.1,0) [0|2000] "V"  MBCU
 SG_ SBCU5_BusCurrent : 39|16@0+ (0.1,-3200) [0|0] "A"  MBCU
 SG_ SBCU5_SOC : 55|16@0+ (0.1,0) [0|100] "%"  MBCU

BO_ 2550898852 SBCU4_Statis_AccumEng: 8 SBCU
 SG_ SBCU4_Accum_DchEng : 7|32@0+ (0.1,0) [0|4000000000] "kWh"  MBCU
 SG_ SBCU4_Accum_ChgEng : 39|32@0+ (0.1,0) [0|4000000000] "kWh"  MBCU

BO_ 2550833316 SBCU4_Statis_AccumCap: 8 SBCU
 SG_ SBCU4_Accum_DchCap : 7|32@0+ (0.1,0) [0|4000000000] "Ah"  MBCU
 SG_ SBCU4_Accum_ChgCap : 39|32@0+ (0.1,0) [0|4000000000] "Ah"  MBCU

BO_ 2550374564 SBCU4_State_Inf2: 8 SBCU
 SG_ SBCU4_Isolation : 7|16@0+ (1,0) [0|65535] "kOhm"  MBCU
 SG_ SBCU4_SOH : 23|12@0+ (0.1,0) [0|0] "%"  MBCU
 SG_ SBCU4_PowerSupply_Volt : 27|12@0+ (0.1,0) [0|0] "V"  MBCU
 SG_ SBCU4_AI1_Value : 47|8@0+ (1,0) [0|255] ""  MBCU
 SG_ SBCU4_AI2_Value : 55|8@0+ (1,0) [0|255] ""  MBCU
 SG_ SBCU4_AI3_Value : 63|8@0+ (1,0) [0|255] ""  MBCU

CM_ BO_ 2550269088 "SBCU�Զ��궨ID����";
CM_ BO_ 2348876448 "MBCU������Ϣ2 ���������";
CM_ SG_ 2348876448 MBCU_Latch_FaultClear_Cmd "��������������:ÿ��λ��Ӧһ��SBCU,֧��16��SBCU ; ÿһλ����һ��SBCU�Ĺ������״̬��0���������1���������";
CM_ SG_ 2348876448 MBCU_Common_FaultClear_Cmd "һ������������:ÿ��λ��Ӧһ��SBCU,֧��16��SBCU; ÿһλ����һ��SBCU�Ĺ������״̬��0���������1���������";
BA_DEF_ SG_  "GenSigStartValue" FLOAT 0 1215752192;
BA_DEF_ SG_  "GenSigMaxValue" INT 0 2147483647;
BA_DEF_ SG_  "GenSigSendType" ENUM  "NoMsgSendType","NoSigSendType","Cyclic";
BA_DEF_ SG_  "GenSigEnvVarType" ENUM  "int","float","undef";
BA_DEF_ BO_  "GenMsgCycleTime" INT 0 65535;
BA_DEF_ BO_  "VFrameFormat" ENUM  "StandardCAN","ExtendedCAN","reserved","J1939PG","reserved","reserved","reserved","reserved","reserved","reserved","reserved","reserved","reserved","reserved","StandardCAN_FD","ExtendedCAN_FD";
BA_DEF_ BO_  "GenMsgSendType" ENUM  "NoMsgSendType","NoSigSendType","Cyclic";
BA_DEF_DEF_  "GenSigStartValue" 0;
BA_DEF_DEF_  "GenSigMaxValue" 0;
BA_DEF_DEF_  "GenSigSendType" "NoMsgSendType";
BA_DEF_DEF_  "GenSigEnvVarType" "undef";
BA_DEF_DEF_  "GenMsgCycleTime" 0;
BA_DEF_DEF_  "VFrameFormat" "StandardCAN";
BA_DEF_DEF_  "GenMsgSendType" "NoMsgSendType";
BA_ "GenMsgSendType" BO_ 2550269088 2;
BA_ "GenMsgCycleTime" BO_ 2550269088 100;
BA_ "VFrameFormat" BO_ 2550269088 1;
BA_ "GenMsgSendType" BO_ 2348876448 2;
BA_ "GenMsgCycleTime" BO_ 2348876448 500;
BA_ "VFrameFormat" BO_ 2348876448 1;
BA_ "GenMsgSendType" BO_ 2550268832 2;
BA_ "GenMsgCycleTime" BO_ 2550268832 100;
BA_ "VFrameFormat" BO_ 2550268832 1;
BA_ "GenMsgSendType" BO_ 2566389931 2;
BA_ "GenMsgCycleTime" BO_ 2566389931 50;
BA_ "VFrameFormat" BO_ 2566389931 1;
BA_ "GenMsgSendType" BO_ 2566389930 2;
BA_ "GenMsgCycleTime" BO_ 2566389930 50;
BA_ "VFrameFormat" BO_ 2566389930 1;
BA_ "GenMsgSendType" BO_ 2566389929 2;
BA_ "GenMsgCycleTime" BO_ 2566389929 50;
BA_ "VFrameFormat" BO_ 2566389929 1;
BA_ "GenMsgSendType" BO_ 2566389928 2;
BA_ "GenMsgCycleTime" BO_ 2566389928 50;
BA_ "VFrameFormat" BO_ 2566389928 1;
BA_ "GenMsgSendType" BO_ 2566389927 2;
BA_ "GenMsgCycleTime" BO_ 2566389927 50;
BA_ "VFrameFormat" BO_ 2566389927 1;
BA_ "GenMsgSendType" BO_ 2566389926 2;
BA_ "GenMsgCycleTime" BO_ 2566389926 50;
BA_ "VFrameFormat" BO_ 2566389926 1;
BA_ "GenMsgSendType" BO_ 2566389925 2;
BA_ "GenMsgCycleTime" BO_ 2566389925 50;
BA_ "VFrameFormat" BO_ 2566389925 1;
BA_ "GenMsgSendType" BO_ 2566389924 2;
BA_ "GenMsgCycleTime" BO_ 2566389924 50;
BA_ "VFrameFormat" BO_ 2566389924 1;
BA_ "GenMsgSendType" BO_ 2566389923 2;
BA_ "GenMsgCycleTime" BO_ 2566389923 50;
BA_ "VFrameFormat" BO_ 2566389923 1;
BA_ "GenMsgSendType" BO_ 2566389922 2;
BA_ "GenMsgCycleTime" BO_ 2566389922 50;
BA_ "VFrameFormat" BO_ 2566389922 1;
BA_ "GenMsgSendType" BO_ 2566389921 2;
BA_ "GenMsgCycleTime" BO_ 2566389921 50;
BA_ "VFrameFormat" BO_ 2566389921 1;
BA_ "GenMsgSendType" BO_ 2565865642 2;
BA_ "GenMsgCycleTime" BO_ 2565865642 50;
BA_ "VFrameFormat" BO_ 2565865642 1;
BA_ "GenMsgSendType" BO_ 2565865641 2;
BA_ "GenMsgCycleTime" BO_ 2565865641 50;
BA_ "VFrameFormat" BO_ 2565865641 1;
BA_ "GenMsgSendType" BO_ 2565865640 2;
BA_ "GenMsgCycleTime" BO_ 2565865640 50;
BA_ "VFrameFormat" BO_ 2565865640 1;
BA_ "GenMsgSendType" BO_ 2565865639 2;
BA_ "GenMsgCycleTime" BO_ 2565865639 50;
BA_ "VFrameFormat" BO_ 2565865639 1;
BA_ "GenMsgSendType" BO_ 2565865638 2;
BA_ "GenMsgCycleTime" BO_ 2565865638 50;
BA_ "VFrameFormat" BO_ 2565865638 1;
BA_ "GenMsgSendType" BO_ 2565865637 2;
BA_ "GenMsgCycleTime" BO_ 2565865637 50;
BA_ "VFrameFormat" BO_ 2565865637 1;
BA_ "GenMsgSendType" BO_ 2565865636 2;
BA_ "GenMsgCycleTime" BO_ 2565865636 50;
BA_ "VFrameFormat" BO_ 2565865636 1;
BA_ "GenMsgSendType" BO_ 2565865635 2;
BA_ "GenMsgCycleTime" BO_ 2565865635 50;
BA_ "VFrameFormat" BO_ 2565865635 1;
BA_ "GenMsgSendType" BO_ 2565865634 2;
BA_ "GenMsgCycleTime" BO_ 2565865634 50;
BA_ "VFrameFormat" BO_ 2565865634 1;
BA_ "GenMsgSendType" BO_ 2565865633 2;
BA_ "GenMsgCycleTime" BO_ 2565865633 50;
BA_ "VFrameFormat" BO_ 2565865633 1;
BA_ "GenMsgSendType" BO_ 2550898858 2;
BA_ "GenMsgCycleTime" BO_ 2550898858 10000;
BA_ "VFrameFormat" BO_ 2550898858 1;
BA_ "GenMsgSendType" BO_ 2550833322 2;
BA_ "GenMsgCycleTime" BO_ 2550833322 10000;
BA_ "VFrameFormat" BO_ 2550833322 1;
BA_ "GenMsgSendType" BO_ 2550374570 2;
BA_ "GenMsgCycleTime" BO_ 2550374570 200;
BA_ "VFrameFormat" BO_ 2550374570 1;
BA_ "GenMsgSendType" BO_ 2348982442 2;
BA_ "GenMsgCycleTime" BO_ 2348982442 100;
BA_ "VFrameFormat" BO_ 2348982442 1;
BA_ "GenMsgSendType" BO_ 2550505642 2;
BA_ "GenMsgCycleTime" BO_ 2550505642 100;
BA_ "VFrameFormat" BO_ 2550505642 1;
BA_ "GenMsgSendType" BO_ 2550440106 2;
BA_ "GenMsgCycleTime" BO_ 2550440106 100;
BA_ "VFrameFormat" BO_ 2550440106 1;
BA_ "GenMsgSendType" BO_ 2550636714 2;
BA_ "GenMsgCycleTime" BO_ 2550636714 200;
BA_ "VFrameFormat" BO_ 2550636714 1;
BA_ "GenMsgSendType" BO_ 2550571178 2;
BA_ "GenMsgCycleTime" BO_ 2550571178 200;
BA_ "VFrameFormat" BO_ 2550571178 1;
BA_ "GenMsgSendType" BO_ 2550702250 2;
BA_ "GenMsgCycleTime" BO_ 2550702250 1000;
BA_ "VFrameFormat" BO_ 2550702250 1;
BA_ "GenMsgSendType" BO_ 2550898857 2;
BA_ "GenMsgCycleTime" BO_ 2550898857 10000;
BA_ "VFrameFormat" BO_ 2550898857 1;
BA_ "GenMsgSendType" BO_ 2550833321 2;
BA_ "GenMsgCycleTime" BO_ 2550833321 10000;
BA_ "VFrameFormat" BO_ 2550833321 1;
BA_ "GenMsgSendType" BO_ 2550374569 2;
BA_ "GenMsgCycleTime" BO_ 2550374569 200;
BA_ "VFrameFormat" BO_ 2550374569 1;
BA_ "GenMsgSendType" BO_ 2348982441 2;
BA_ "GenMsgCycleTime" BO_ 2348982441 100;
BA_ "VFrameFormat" BO_ 2348982441 1;
BA_ "GenMsgSendType" BO_ 2550505641 2;
BA_ "GenMsgCycleTime" BO_ 2550505641 100;
BA_ "VFrameFormat" BO_ 2550505641 1;
BA_ "GenMsgSendType" BO_ 2550440105 2;
BA_ "GenMsgCycleTime" BO_ 2550440105 100;
BA_ "VFrameFormat" BO_ 2550440105 1;
BA_ "GenMsgSendType" BO_ 2550636713 2;
BA_ "GenMsgCycleTime" BO_ 2550636713 200;
BA_ "VFrameFormat" BO_ 2550636713 1;
BA_ "GenMsgSendType" BO_ 2550571177 2;
BA_ "GenMsgCycleTime" BO_ 2550571177 200;
BA_ "VFrameFormat" BO_ 2550571177 1;
BA_ "GenMsgSendType" BO_ 2550702249 2;
BA_ "GenMsgCycleTime" BO_ 2550702249 1000;
BA_ "VFrameFormat" BO_ 2550702249 1;
BA_ "GenMsgSendType" BO_ 2566652074 2;
BA_ "GenMsgCycleTime" BO_ 2566652074 1000;
BA_ "VFrameFormat" BO_ 2566652074 1;
BA_ "GenMsgSendType" BO_ 2566652073 2;
BA_ "GenMsgCycleTime" BO_ 2566652073 1000;
BA_ "VFrameFormat" BO_ 2566652073 1;
BA_ "GenMsgSendType" BO_ 2550243498 2;
BA_ "GenMsgCycleTime" BO_ 2550243498 50;
BA_ "VFrameFormat" BO_ 2550243498 1;
BA_ "GenMsgSendType" BO_ 2550243497 2;
BA_ "GenMsgCycleTime" BO_ 2550243497 50;
BA_ "VFrameFormat" BO_ 2550243497 1;
BA_ "VFrameFormat" BO_ 2550330611 1;
BA_ "GenMsgSendType" BO_ 2550898856 2;
BA_ "GenMsgCycleTime" BO_ 2550898856 10000;
BA_ "VFrameFormat" BO_ 2550898856 1;
BA_ "GenMsgSendType" BO_ 2550833320 2;
BA_ "GenMsgCycleTime" BO_ 2550833320 10000;
BA_ "VFrameFormat" BO_ 2550833320 1;
BA_ "GenMsgSendType" BO_ 2550374568 2;
BA_ "GenMsgCycleTime" BO_ 2550374568 200;
BA_ "VFrameFormat" BO_ 2550374568 1;
BA_ "GenMsgSendType" BO_ 2348982440 2;
BA_ "GenMsgCycleTime" BO_ 2348982440 100;
BA_ "VFrameFormat" BO_ 2348982440 1;
BA_ "GenMsgSendType" BO_ 2550505640 2;
BA_ "GenMsgCycleTime" BO_ 2550505640 100;
BA_ "VFrameFormat" BO_ 2550505640 1;
BA_ "GenMsgSendType" BO_ 2550440104 2;
BA_ "GenMsgCycleTime" BO_ 2550440104 100;
BA_ "VFrameFormat" BO_ 2550440104 1;
BA_ "GenMsgSendType" BO_ 2550636712 2;
BA_ "GenMsgCycleTime" BO_ 2550636712 200;
BA_ "VFrameFormat" BO_ 2550636712 1;
BA_ "GenMsgSendType" BO_ 2550571176 2;
BA_ "GenMsgCycleTime" BO_ 2550571176 200;
BA_ "VFrameFormat" BO_ 2550571176 1;
BA_ "GenMsgSendType" BO_ 2550702248 2;
BA_ "GenMsgCycleTime" BO_ 2550702248 1000;
BA_ "VFrameFormat" BO_ 2550702248 1;
BA_ "GenMsgSendType" BO_ 2566652072 2;
BA_ "GenMsgCycleTime" BO_ 2566652072 1000;
BA_ "VFrameFormat" BO_ 2566652072 1;
BA_ "GenMsgSendType" BO_ 2550243496 2;
BA_ "GenMsgCycleTime" BO_ 2550243496 50;
BA_ "VFrameFormat" BO_ 2550243496 1;
BA_ "GenMsgSendType" BO_ 2550898855 2;
BA_ "GenMsgCycleTime" BO_ 2550898855 10000;
BA_ "VFrameFormat" BO_ 2550898855 1;
BA_ "GenMsgSendType" BO_ 2550833319 2;
BA_ "GenMsgCycleTime" BO_ 2550833319 10000;
BA_ "VFrameFormat" BO_ 2550833319 1;
BA_ "GenMsgSendType" BO_ 2550374567 2;
BA_ "GenMsgCycleTime" BO_ 2550374567 200;
BA_ "VFrameFormat" BO_ 2550374567 1;
BA_ "GenMsgSendType" BO_ 2348982439 2;
BA_ "GenMsgCycleTime" BO_ 2348982439 100;
BA_ "VFrameFormat" BO_ 2348982439 1;
BA_ "GenMsgSendType" BO_ 2550505639 2;
BA_ "GenMsgCycleTime" BO_ 2550505639 100;
BA_ "VFrameFormat" BO_ 2550505639 1;
BA_ "GenMsgSendType" BO_ 2550440103 2;
BA_ "GenMsgCycleTime" BO_ 2550440103 100;
BA_ "VFrameFormat" BO_ 2550440103 1;
BA_ "GenMsgSendType" BO_ 2550636711 2;
BA_ "GenMsgCycleTime" BO_ 2550636711 200;
BA_ "VFrameFormat" BO_ 2550636711 1;
BA_ "GenMsgSendType" BO_ 2550571175 2;
BA_ "GenMsgCycleTime" BO_ 2550571175 200;
BA_ "VFrameFormat" BO_ 2550571175 1;
BA_ "GenMsgSendType" BO_ 2550702247 2;
BA_ "GenMsgCycleTime" BO_ 2550702247 1000;
BA_ "VFrameFormat" BO_ 2550702247 1;
BA_ "GenMsgSendType" BO_ 2566652071 2;
BA_ "GenMsgCycleTime" BO_ 2566652071 1000;
BA_ "VFrameFormat" BO_ 2566652071 1;
BA_ "GenMsgSendType" BO_ 2550243495 2;
BA_ "GenMsgCycleTime" BO_ 2550243495 50;
BA_ "VFrameFormat" BO_ 2550243495 1;
BA_ "GenMsgSendType" BO_ 2550898854 2;
BA_ "GenMsgCycleTime" BO_ 2550898854 10000;
BA_ "VFrameFormat" BO_ 2550898854 1;
BA_ "GenMsgSendType" BO_ 2550833318 2;
BA_ "GenMsgCycleTime" BO_ 2550833318 10000;
BA_ "VFrameFormat" BO_ 2550833318 1;
BA_ "GenMsgSendType" BO_ 2550374566 2;
BA_ "GenMsgCycleTime" BO_ 2550374566 200;
BA_ "VFrameFormat" BO_ 2550374566 1;
BA_ "GenMsgSendType" BO_ 2348982438 2;
BA_ "GenMsgCycleTime" BO_ 2348982438 100;
BA_ "VFrameFormat" BO_ 2348982438 1;
BA_ "GenMsgSendType" BO_ 2550505638 2;
BA_ "GenMsgCycleTime" BO_ 2550505638 100;
BA_ "VFrameFormat" BO_ 2550505638 1;
BA_ "GenMsgSendType" BO_ 2550440102 2;
BA_ "GenMsgCycleTime" BO_ 2550440102 100;
BA_ "VFrameFormat" BO_ 2550440102 1;
BA_ "GenMsgSendType" BO_ 2550636710 2;
BA_ "GenMsgCycleTime" BO_ 2550636710 200;
BA_ "VFrameFormat" BO_ 2550636710 1;
BA_ "GenMsgSendType" BO_ 2550571174 2;
BA_ "GenMsgCycleTime" BO_ 2550571174 200;
BA_ "VFrameFormat" BO_ 2550571174 1;
BA_ "GenMsgSendType" BO_ 2550702246 2;
BA_ "GenMsgCycleTime" BO_ 2550702246 1000;
BA_ "VFrameFormat" BO_ 2550702246 1;
BA_ "GenMsgSendType" BO_ 2566652070 2;
BA_ "GenMsgCycleTime" BO_ 2566652070 1000;
BA_ "VFrameFormat" BO_ 2566652070 1;
BA_ "GenMsgSendType" BO_ 2550243494 2;
BA_ "GenMsgCycleTime" BO_ 2550243494 50;
BA_ "VFrameFormat" BO_ 2550243494 1;
BA_ "GenMsgSendType" BO_ 2550898853 2;
BA_ "GenMsgCycleTime" BO_ 2550898853 10000;
BA_ "VFrameFormat" BO_ 2550898853 1;
BA_ "GenMsgSendType" BO_ 2550833317 2;
BA_ "GenMsgCycleTime" BO_ 2550833317 10000;
BA_ "VFrameFormat" BO_ 2550833317 1;
BA_ "GenMsgSendType" BO_ 2550374565 2;
BA_ "GenMsgCycleTime" BO_ 2550374565 200;
BA_ "VFrameFormat" BO_ 2550374565 1;
BA_ "GenMsgSendType" BO_ 2348982437 2;
BA_ "GenMsgCycleTime" BO_ 2348982437 100;
BA_ "VFrameFormat" BO_ 2348982437 1;
BA_ "GenMsgSendType" BO_ 2550505637 2;
BA_ "GenMsgCycleTime" BO_ 2550505637 100;
BA_ "VFrameFormat" BO_ 2550505637 1;
BA_ "GenMsgSendType" BO_ 2550440101 2;
BA_ "GenMsgCycleTime" BO_ 2550440101 100;
BA_ "VFrameFormat" BO_ 2550440101 1;
BA_ "GenMsgSendType" BO_ 2550636709 2;
BA_ "GenMsgCycleTime" BO_ 2550636709 200;
BA_ "VFrameFormat" BO_ 2550636709 1;
BA_ "GenMsgSendType" BO_ 2550571173 2;
BA_ "GenMsgCycleTime" BO_ 2550571173 200;
BA_ "VFrameFormat" BO_ 2550571173 1;
BA_ "GenMsgSendType" BO_ 2550702245 2;
BA_ "GenMsgCycleTime" BO_ 2550702245 1000;
BA_ "VFrameFormat" BO_ 2550702245 1;
BA_ "GenMsgSendType" BO_ 2566652069 2;
BA_ "GenMsgCycleTime" BO_ 2566652069 1000;
BA_ "VFrameFormat" BO_ 2566652069 1;
BA_ "GenMsgSendType" BO_ 2550243493 2;
BA_ "GenMsgCycleTime" BO_ 2550243493 50;
BA_ "VFrameFormat" BO_ 2550243493 1;
BA_ "GenMsgSendType" BO_ 2550898852 2;
BA_ "GenMsgCycleTime" BO_ 2550898852 10000;
BA_ "VFrameFormat" BO_ 2550898852 1;
BA_ "GenMsgSendType" BO_ 2550833316 2;
BA_ "GenMsgCycleTime" BO_ 2550833316 10000;
BA_ "VFrameFormat" BO_ 2550833316 1;
BA_ "GenMsgSendType" BO_ 2550374564 2;
BA_ "GenMsgCycleTime" BO_ 2550374564 200;
BA_ "VFrameFormat" BO_ 2550374564 1;
BA_ "GenSigSendType" SG_ 2550269088 MBCU_SBCU_ID_Calib_Rev8 1;
BA_ "GenSigMaxValue" SG_ 2550269088 MBCU_SBCU_ID_Calib_Rev8 255;
BA_ "GenSigSendType" SG_ 2550269088 MBCU_SBCU_ID_Calib_Rev7 1;
BA_ "GenSigMaxValue" SG_ 2550269088 MBCU_SBCU_ID_Calib_Rev7 255;
BA_ "GenSigSendType" SG_ 2550269088 MBCU_SBCU_ID_Calib_Rev6 1;
BA_ "GenSigMaxValue" SG_ 2550269088 MBCU_SBCU_ID_Calib_Rev6 255;
BA_ "GenSigSendType" SG_ 2550269088 MBCU_SBCU_ID_Calib_Rev5 1;
BA_ "GenSigMaxValue" SG_ 2550269088 MBCU_SBCU_ID_Calib_Rev5 255;
BA_ "GenSigSendType" SG_ 2550269088 MBCU_SBCU_ID_Calib_Rev4 1;
BA_ "GenSigMaxValue" SG_ 2550269088 MBCU_SBCU_ID_Calib_Rev4 255;
BA_ "GenSigSendType" SG_ 2550269088 MBCU_SBCU_ID_Calib_Rev3 1;
BA_ "GenSigMaxValue" SG_ 2550269088 MBCU_SBCU_ID_Calib_Rev3 255;
BA_ "GenSigSendType" SG_ 2550269088 MBCU_SBCU_ID_Calib_Rev2 1;
BA_ "GenSigMaxValue" SG_ 2550269088 MBCU_SBCU_ID_Calib_Rev2 255;
BA_ "GenSigSendType" SG_ 2550269088 MBCU_SBCU_ID_Calib_Rev1 1;
BA_ "GenSigMaxValue" SG_ 2550269088 MBCU_SBCU_ID_Calib_Rev1 255;
BA_ "GenSigSendType" SG_ 2348876448 MBCU_Cmd_Info2_Rev4 1;
BA_ "GenSigMaxValue" SG_ 2348876448 MBCU_Cmd_Info2_Rev4 255;
BA_ "GenSigSendType" SG_ 2348876448 MBCU_Cmd_Info2_Rev3 1;
BA_ "GenSigMaxValue" SG_ 2348876448 MBCU_Cmd_Info2_Rev3 255;
BA_ "GenSigSendType" SG_ 2348876448 MBCU_Cmd_Info2_Rev2 1;
BA_ "GenSigMaxValue" SG_ 2348876448 MBCU_Cmd_Info2_Rev2 255;
BA_ "GenSigSendType" SG_ 2348876448 MBCU_Cmd_Info2_Rev1 1;
BA_ "GenSigMaxValue" SG_ 2348876448 MBCU_Cmd_Info2_Rev1 255;
BA_ "GenSigSendType" SG_ 2348876448 MBCU_Latch_FaultClear_Cmd 1;
BA_ "GenSigMaxValue" SG_ 2348876448 MBCU_Latch_FaultClear_Cmd 65535;
BA_ "GenSigSendType" SG_ 2348876448 MBCU_Common_FaultClear_Cmd 1;
BA_ "GenSigMaxValue" SG_ 2348876448 MBCU_Common_FaultClear_Cmd 65535;
BA_ "GenSigSendType" SG_ 2550268832 MBCU_Year 1;
BA_ "GenSigMaxValue" SG_ 2550268832 MBCU_Year 255;
BA_ "GenSigSendType" SG_ 2550268832 MBCU_Second 1;
BA_ "GenSigMaxValue" SG_ 2550268832 MBCU_Second 255;
BA_ "GenSigSendType" SG_ 2550268832 MBCU_Month 1;
BA_ "GenSigMaxValue" SG_ 2550268832 MBCU_Month 255;
BA_ "GenSigStartValue" SG_ 2550268832 MBCU_Month 1;
BA_ "GenSigSendType" SG_ 2550268832 MBCU_Minute 1;
BA_ "GenSigMaxValue" SG_ 2550268832 MBCU_Minute 255;
BA_ "GenSigSendType" SG_ 2550268832 MBCU_Hour 1;
BA_ "GenSigMaxValue" SG_ 2550268832 MBCU_Hour 255;
BA_ "GenSigSendType" SG_ 2550268832 MBCU_Day 1;
BA_ "GenSigMaxValue" SG_ 2550268832 MBCU_Day 255;
BA_ "GenSigStartValue" SG_ 2550268832 MBCU_Day 1;
BA_ "GenSigSendType" SG_ 2566389931 SBCU11_CellTemp_Rev 1;
BA_ "GenSigMaxValue" SG_ 2566389931 SBCU11_CellTemp_Rev 65535;
BA_ "GenSigSendType" SG_ 2566389931 SBCU11_CellTemp2_CellNO 1;
BA_ "GenSigMaxValue" SG_ 2566389931 SBCU11_CellTemp2_CellNO 255;
BA_ "GenSigSendType" SG_ 2566389931 SBCU11_CellTemp2_BMUNO 1;
BA_ "GenSigMaxValue" SG_ 2566389931 SBCU11_CellTemp2_BMUNO 255;
BA_ "GenSigSendType" SG_ 2566389931 SBCU11_CellTemp2 1;
BA_ "GenSigMaxValue" SG_ 2566389931 SBCU11_CellTemp2 255;
BA_ "GenSigSendType" SG_ 2566389931 SBCU11_CellTemp1_CellNO 1;
BA_ "GenSigMaxValue" SG_ 2566389931 SBCU11_CellTemp1_CellNO 255;
BA_ "GenSigSendType" SG_ 2566389931 SBCU11_CellTemp1_BMUNO 1;
BA_ "GenSigMaxValue" SG_ 2566389931 SBCU11_CellTemp1_BMUNO 255;
BA_ "GenSigSendType" SG_ 2566389931 SBCU11_CellTemp1 1;
BA_ "GenSigMaxValue" SG_ 2566389931 SBCU11_CellTemp1 255;
BA_ "GenSigSendType" SG_ 2566389930 SBCU10_CellTemp_Rev 1;
BA_ "GenSigMaxValue" SG_ 2566389930 SBCU10_CellTemp_Rev 65535;
BA_ "GenSigSendType" SG_ 2566389930 SBCU10_CellTemp2_CellNO 1;
BA_ "GenSigMaxValue" SG_ 2566389930 SBCU10_CellTemp2_CellNO 255;
BA_ "GenSigSendType" SG_ 2566389930 SBCU10_CellTemp2_BMUNO 1;
BA_ "GenSigMaxValue" SG_ 2566389930 SBCU10_CellTemp2_BMUNO 255;
BA_ "GenSigSendType" SG_ 2566389930 SBCU10_CellTemp2 1;
BA_ "GenSigMaxValue" SG_ 2566389930 SBCU10_CellTemp2 255;
BA_ "GenSigSendType" SG_ 2566389930 SBCU10_CellTemp1_CellNO 1;
BA_ "GenSigMaxValue" SG_ 2566389930 SBCU10_CellTemp1_CellNO 255;
BA_ "GenSigSendType" SG_ 2566389930 SBCU10_CellTemp1_BMUNO 1;
BA_ "GenSigMaxValue" SG_ 2566389930 SBCU10_CellTemp1_BMUNO 255;
BA_ "GenSigSendType" SG_ 2566389930 SBCU10_CellTemp1 1;
BA_ "GenSigMaxValue" SG_ 2566389930 SBCU10_CellTemp1 255;
BA_ "GenSigSendType" SG_ 2566389929 SBCU9_CellTemp_Rev 1;
BA_ "GenSigMaxValue" SG_ 2566389929 SBCU9_CellTemp_Rev 65535;
BA_ "GenSigSendType" SG_ 2566389929 SBCU9_CellTemp2_CellNO 1;
BA_ "GenSigMaxValue" SG_ 2566389929 SBCU9_CellTemp2_CellNO 255;
BA_ "GenSigSendType" SG_ 2566389929 SBCU9_CellTemp2_BMUNO 1;
BA_ "GenSigMaxValue" SG_ 2566389929 SBCU9_CellTemp2_BMUNO 255;
BA_ "GenSigSendType" SG_ 2566389929 SBCU9_CellTemp2 1;
BA_ "GenSigMaxValue" SG_ 2566389929 SBCU9_CellTemp2 255;
BA_ "GenSigSendType" SG_ 2566389929 SBCU9_CellTemp1_CellNO 1;
BA_ "GenSigMaxValue" SG_ 2566389929 SBCU9_CellTemp1_CellNO 255;
BA_ "GenSigSendType" SG_ 2566389929 SBCU9_CellTemp1_BMUNO 1;
BA_ "GenSigMaxValue" SG_ 2566389929 SBCU9_CellTemp1_BMUNO 255;
BA_ "GenSigSendType" SG_ 2566389929 SBCU9_CellTemp1 1;
BA_ "GenSigMaxValue" SG_ 2566389929 SBCU9_CellTemp1 255;
BA_ "GenSigSendType" SG_ 2566389928 SBCU8_CellTemp_Rev 1;
BA_ "GenSigMaxValue" SG_ 2566389928 SBCU8_CellTemp_Rev 65535;
BA_ "GenSigSendType" SG_ 2566389928 SBCU8_CellTemp2_CellNO 1;
BA_ "GenSigMaxValue" SG_ 2566389928 SBCU8_CellTemp2_CellNO 255;
BA_ "GenSigSendType" SG_ 2566389928 SBCU8_CellTemp2_BMUNO 1;
BA_ "GenSigMaxValue" SG_ 2566389928 SBCU8_CellTemp2_BMUNO 255;
BA_ "GenSigSendType" SG_ 2566389928 SBCU8_CellTemp2 1;
BA_ "GenSigMaxValue" SG_ 2566389928 SBCU8_CellTemp2 255;
BA_ "GenSigSendType" SG_ 2566389928 SBCU8_CellTemp1_CellNO 1;
BA_ "GenSigMaxValue" SG_ 2566389928 SBCU8_CellTemp1_CellNO 255;
BA_ "GenSigSendType" SG_ 2566389928 SBCU8_CellTemp1_BMUNO 1;
BA_ "GenSigMaxValue" SG_ 2566389928 SBCU8_CellTemp1_BMUNO 255;
BA_ "GenSigSendType" SG_ 2566389928 SBCU8_CellTemp1 1;
BA_ "GenSigMaxValue" SG_ 2566389928 SBCU8_CellTemp1 255;
BA_ "GenSigSendType" SG_ 2566389927 SBCU7_CellTemp_Rev 1;
BA_ "GenSigMaxValue" SG_ 2566389927 SBCU7_CellTemp_Rev 65535;
BA_ "GenSigSendType" SG_ 2566389927 SBCU7_CellTemp2_CellNO 1;
BA_ "GenSigMaxValue" SG_ 2566389927 SBCU7_CellTemp2_CellNO 255;
BA_ "GenSigSendType" SG_ 2566389927 SBCU7_CellTemp2_BMUNO 1;
BA_ "GenSigMaxValue" SG_ 2566389927 SBCU7_CellTemp2_BMUNO 255;
BA_ "GenSigSendType" SG_ 2566389927 SBCU7_CellTemp2 1;
BA_ "GenSigMaxValue" SG_ 2566389927 SBCU7_CellTemp2 255;
BA_ "GenSigSendType" SG_ 2566389927 SBCU7_CellTemp1_CellNO 1;
BA_ "GenSigMaxValue" SG_ 2566389927 SBCU7_CellTemp1_CellNO 255;
BA_ "GenSigSendType" SG_ 2566389927 SBCU7_CellTemp1_BMUNO 1;
BA_ "GenSigMaxValue" SG_ 2566389927 SBCU7_CellTemp1_BMUNO 255;
BA_ "GenSigSendType" SG_ 2566389927 SBCU7_CellTemp1 1;
BA_ "GenSigMaxValue" SG_ 2566389927 SBCU7_CellTemp1 255;
BA_ "GenSigSendType" SG_ 2566389926 SBCU6_CellTemp_Rev 1;
BA_ "GenSigMaxValue" SG_ 2566389926 SBCU6_CellTemp_Rev 65535;
BA_ "GenSigSendType" SG_ 2566389926 SBCU6_CellTemp2_CellNO 1;
BA_ "GenSigMaxValue" SG_ 2566389926 SBCU6_CellTemp2_CellNO 255;
BA_ "GenSigSendType" SG_ 2566389926 SBCU6_CellTemp2_BMUNO 1;
BA_ "GenSigMaxValue" SG_ 2566389926 SBCU6_CellTemp2_BMUNO 255;
BA_ "GenSigSendType" SG_ 2566389926 SBCU6_CellTemp2 1;
BA_ "GenSigMaxValue" SG_ 2566389926 SBCU6_CellTemp2 255;
BA_ "GenSigSendType" SG_ 2566389926 SBCU6_CellTemp1_CellNO 1;
BA_ "GenSigMaxValue" SG_ 2566389926 SBCU6_CellTemp1_CellNO 255;
BA_ "GenSigSendType" SG_ 2566389926 SBCU6_CellTemp1_BMUNO 1;
BA_ "GenSigMaxValue" SG_ 2566389926 SBCU6_CellTemp1_BMUNO 255;
BA_ "GenSigSendType" SG_ 2566389926 SBCU6_CellTemp1 1;
BA_ "GenSigMaxValue" SG_ 2566389926 SBCU6_CellTemp1 255;
BA_ "GenSigSendType" SG_ 2566389925 SBCU5_CellTemp_Rev 1;
BA_ "GenSigMaxValue" SG_ 2566389925 SBCU5_CellTemp_Rev 65535;
BA_ "GenSigSendType" SG_ 2566389925 SBCU5_CellTemp2_CellNO 1;
BA_ "GenSigMaxValue" SG_ 2566389925 SBCU5_CellTemp2_CellNO 255;
BA_ "GenSigSendType" SG_ 2566389925 SBCU5_CellTemp2_BMUNO 1;
BA_ "GenSigMaxValue" SG_ 2566389925 SBCU5_CellTemp2_BMUNO 255;
BA_ "GenSigSendType" SG_ 2566389925 SBCU5_CellTemp2 1;
BA_ "GenSigMaxValue" SG_ 2566389925 SBCU5_CellTemp2 255;
BA_ "GenSigSendType" SG_ 2566389925 SBCU5_CellTemp1_CellNO 1;
BA_ "GenSigMaxValue" SG_ 2566389925 SBCU5_CellTemp1_CellNO 255;
BA_ "GenSigSendType" SG_ 2566389925 SBCU5_CellTemp1_BMUNO 1;
BA_ "GenSigMaxValue" SG_ 2566389925 SBCU5_CellTemp1_BMUNO 255;
BA_ "GenSigSendType" SG_ 2566389925 SBCU5_CellTemp1 1;
BA_ "GenSigMaxValue" SG_ 2566389925 SBCU5_CellTemp1 255;
BA_ "GenSigSendType" SG_ 2566389924 SBCU4_CellTemp_Rev 1;
BA_ "GenSigMaxValue" SG_ 2566389924 SBCU4_CellTemp_Rev 65535;
BA_ "GenSigSendType" SG_ 2566389924 SBCU4_CellTemp2_CellNO 1;
BA_ "GenSigMaxValue" SG_ 2566389924 SBCU4_CellTemp2_CellNO 255;
BA_ "GenSigSendType" SG_ 2566389924 SBCU4_CellTemp2_BMUNO 1;
BA_ "GenSigMaxValue" SG_ 2566389924 SBCU4_CellTemp2_BMUNO 255;
BA_ "GenSigSendType" SG_ 2566389924 SBCU4_CellTemp2 1;
BA_ "GenSigMaxValue" SG_ 2566389924 SBCU4_CellTemp2 255;
BA_ "GenSigSendType" SG_ 2566389924 SBCU4_CellTemp1_CellNO 1;
BA_ "GenSigMaxValue" SG_ 2566389924 SBCU4_CellTemp1_CellNO 255;
BA_ "GenSigSendType" SG_ 2566389924 SBCU4_CellTemp1_BMUNO 1;
BA_ "GenSigMaxValue" SG_ 2566389924 SBCU4_CellTemp1_BMUNO 255;
BA_ "GenSigSendType" SG_ 2566389924 SBCU4_CellTemp1 1;
BA_ "GenSigMaxValue" SG_ 2566389924 SBCU4_CellTemp1 255;
BA_ "GenSigSendType" SG_ 2566389923 SBCU3_CellTemp_Rev 1;
BA_ "GenSigMaxValue" SG_ 2566389923 SBCU3_CellTemp_Rev 65535;
BA_ "GenSigSendType" SG_ 2566389923 SBCU3_CellTemp2_CellNO 1;
BA_ "GenSigMaxValue" SG_ 2566389923 SBCU3_CellTemp2_CellNO 255;
BA_ "GenSigSendType" SG_ 2566389923 SBCU3_CellTemp2_BMUNO 1;
BA_ "GenSigMaxValue" SG_ 2566389923 SBCU3_CellTemp2_BMUNO 255;
BA_ "GenSigSendType" SG_ 2566389923 SBCU3_CellTemp2 1;
BA_ "GenSigMaxValue" SG_ 2566389923 SBCU3_CellTemp2 255;
BA_ "GenSigSendType" SG_ 2566389923 SBCU3_CellTemp1_CellNO 1;
BA_ "GenSigMaxValue" SG_ 2566389923 SBCU3_CellTemp1_CellNO 255;
BA_ "GenSigSendType" SG_ 2566389923 SBCU3_CellTemp1_BMUNO 1;
BA_ "GenSigMaxValue" SG_ 2566389923 SBCU3_CellTemp1_BMUNO 255;
BA_ "GenSigSendType" SG_ 2566389923 SBCU3_CellTemp1 1;
BA_ "GenSigMaxValue" SG_ 2566389923 SBCU3_CellTemp1 255;
BA_ "GenSigSendType" SG_ 2566389922 SBCU2_CellTemp_Rev 1;
BA_ "GenSigMaxValue" SG_ 2566389922 SBCU2_CellTemp_Rev 65535;
BA_ "GenSigSendType" SG_ 2566389922 SBCU2_CellTemp2_CellNO 1;
BA_ "GenSigMaxValue" SG_ 2566389922 SBCU2_CellTemp2_CellNO 255;
BA_ "GenSigSendType" SG_ 2566389922 SBCU2_CellTemp2_BMUNO 1;
BA_ "GenSigMaxValue" SG_ 2566389922 SBCU2_CellTemp2_BMUNO 255;
BA_ "GenSigSendType" SG_ 2566389922 SBCU2_CellTemp2 1;
BA_ "GenSigMaxValue" SG_ 2566389922 SBCU2_CellTemp2 255;
BA_ "GenSigSendType" SG_ 2566389922 SBCU2_CellTemp1_CellNO 1;
BA_ "GenSigMaxValue" SG_ 2566389922 SBCU2_CellTemp1_CellNO 255;
BA_ "GenSigSendType" SG_ 2566389922 SBCU2_CellTemp1_BMUNO 1;
BA_ "GenSigMaxValue" SG_ 2566389922 SBCU2_CellTemp1_BMUNO 255;
BA_ "GenSigSendType" SG_ 2566389922 SBCU2_CellTemp1 1;
BA_ "GenSigMaxValue" SG_ 2566389922 SBCU2_CellTemp1 255;
BA_ "GenSigSendType" SG_ 2566389921 SBCU1_CellTemp_Rev 1;
BA_ "GenSigMaxValue" SG_ 2566389921 SBCU1_CellTemp_Rev 65535;
BA_ "GenSigSendType" SG_ 2566389921 SBCU1_CellTemp2_CellNO 1;
BA_ "GenSigMaxValue" SG_ 2566389921 SBCU1_CellTemp2_CellNO 255;
BA_ "GenSigSendType" SG_ 2566389921 SBCU1_CellTemp2_BMUNO 1;
BA_ "GenSigMaxValue" SG_ 2566389921 SBCU1_CellTemp2_BMUNO 255;
BA_ "GenSigSendType" SG_ 2566389921 SBCU1_CellTemp2 1;
BA_ "GenSigMaxValue" SG_ 2566389921 SBCU1_CellTemp2 255;
BA_ "GenSigSendType" SG_ 2566389921 SBCU1_CellTemp1_CellNO 1;
BA_ "GenSigMaxValue" SG_ 2566389921 SBCU1_CellTemp1_CellNO 255;
BA_ "GenSigSendType" SG_ 2566389921 SBCU1_CellTemp1_BMUNO 1;
BA_ "GenSigMaxValue" SG_ 2566389921 SBCU1_CellTemp1_BMUNO 255;
BA_ "GenSigSendType" SG_ 2566389921 SBCU1_CellTemp1 1;
BA_ "GenSigMaxValue" SG_ 2566389921 SBCU1_CellTemp1 255;
BA_ "GenSigSendType" SG_ 2565865642 SBCU10_CellVolt2_CellNO 1;
BA_ "GenSigMaxValue" SG_ 2565865642 SBCU10_CellVolt2_CellNO 255;
BA_ "GenSigSendType" SG_ 2565865642 SBCU10_CellVolt2_BMUNO 1;
BA_ "GenSigMaxValue" SG_ 2565865642 SBCU10_CellVolt2_BMUNO 255;
BA_ "GenSigSendType" SG_ 2565865642 SBCU10_CellVolt2 1;
BA_ "GenSigMaxValue" SG_ 2565865642 SBCU10_CellVolt2 65535;
BA_ "GenSigSendType" SG_ 2565865642 SBCU10_CellVolt1_CellNO 1;
BA_ "GenSigMaxValue" SG_ 2565865642 SBCU10_CellVolt1_CellNO 255;
BA_ "GenSigSendType" SG_ 2565865642 SBCU10_CellVolt1_BMUNO 1;
BA_ "GenSigMaxValue" SG_ 2565865642 SBCU10_CellVolt1_BMUNO 255;
BA_ "GenSigSendType" SG_ 2565865642 SBCU10_CellVolt1 1;
BA_ "GenSigMaxValue" SG_ 2565865642 SBCU10_CellVolt1 65535;
BA_ "GenSigSendType" SG_ 2565865641 SBCU9_CellVolt1 1;
BA_ "GenSigMaxValue" SG_ 2565865641 SBCU9_CellVolt1 65535;
BA_ "GenSigSendType" SG_ 2565865641 SBCU9_CellVolt2_CellNO 1;
BA_ "GenSigMaxValue" SG_ 2565865641 SBCU9_CellVolt2_CellNO 255;
BA_ "GenSigSendType" SG_ 2565865641 SBCU9_CellVolt2_BMUNO 1;
BA_ "GenSigMaxValue" SG_ 2565865641 SBCU9_CellVolt2_BMUNO 255;
BA_ "GenSigSendType" SG_ 2565865641 SBCU9_CellVolt2 1;
BA_ "GenSigMaxValue" SG_ 2565865641 SBCU9_CellVolt2 65535;
BA_ "GenSigSendType" SG_ 2565865641 SBCU9_CellVolt1_CellNO 1;
BA_ "GenSigMaxValue" SG_ 2565865641 SBCU9_CellVolt1_CellNO 255;
BA_ "GenSigSendType" SG_ 2565865641 SBCU9_CellVolt1_BMUNO 1;
BA_ "GenSigMaxValue" SG_ 2565865641 SBCU9_CellVolt1_BMUNO 255;
BA_ "GenSigSendType" SG_ 2565865640 SBCU8_CellVolt2_CellNO 1;
BA_ "GenSigMaxValue" SG_ 2565865640 SBCU8_CellVolt2_CellNO 255;
BA_ "GenSigSendType" SG_ 2565865640 SBCU8_CellVolt2_BMUNO 1;
BA_ "GenSigMaxValue" SG_ 2565865640 SBCU8_CellVolt2_BMUNO 255;
BA_ "GenSigSendType" SG_ 2565865640 SBCU8_CellVolt2 1;
BA_ "GenSigMaxValue" SG_ 2565865640 SBCU8_CellVolt2 65535;
BA_ "GenSigSendType" SG_ 2565865640 SBCU8_CellVolt1_CellNO 1;
BA_ "GenSigMaxValue" SG_ 2565865640 SBCU8_CellVolt1_CellNO 255;
BA_ "GenSigSendType" SG_ 2565865640 SBCU8_CellVolt1_BMUNO 1;
BA_ "GenSigMaxValue" SG_ 2565865640 SBCU8_CellVolt1_BMUNO 255;
BA_ "GenSigSendType" SG_ 2565865640 SBCU8_CellVolt1 1;
BA_ "GenSigMaxValue" SG_ 2565865640 SBCU8_CellVolt1 65535;
BA_ "GenSigSendType" SG_ 2565865639 SBCU7_CellVolt2_CellNO 1;
BA_ "GenSigMaxValue" SG_ 2565865639 SBCU7_CellVolt2_CellNO 255;
BA_ "GenSigSendType" SG_ 2565865639 SBCU7_CellVolt2_BMUNO 1;
BA_ "GenSigMaxValue" SG_ 2565865639 SBCU7_CellVolt2_BMUNO 255;
BA_ "GenSigSendType" SG_ 2565865639 SBCU7_CellVolt2 1;
BA_ "GenSigMaxValue" SG_ 2565865639 SBCU7_CellVolt2 65535;
BA_ "GenSigSendType" SG_ 2565865639 SBCU7_CellVolt1_CellNO 1;
BA_ "GenSigMaxValue" SG_ 2565865639 SBCU7_CellVolt1_CellNO 255;
BA_ "GenSigSendType" SG_ 2565865639 SBCU7_CellVolt1_BMUNO 1;
BA_ "GenSigMaxValue" SG_ 2565865639 SBCU7_CellVolt1_BMUNO 255;
BA_ "GenSigSendType" SG_ 2565865639 SBCU7_CellVolt1 1;
BA_ "GenSigMaxValue" SG_ 2565865639 SBCU7_CellVolt1 65535;
BA_ "GenSigSendType" SG_ 2565865638 SBCU6_CellVolt2_CellNO 1;
BA_ "GenSigMaxValue" SG_ 2565865638 SBCU6_CellVolt2_CellNO 255;
BA_ "GenSigSendType" SG_ 2565865638 SBCU6_CellVolt2_BMUNO 1;
BA_ "GenSigMaxValue" SG_ 2565865638 SBCU6_CellVolt2_BMUNO 255;
BA_ "GenSigSendType" SG_ 2565865638 SBCU6_CellVolt2 1;
BA_ "GenSigMaxValue" SG_ 2565865638 SBCU6_CellVolt2 65535;
BA_ "GenSigSendType" SG_ 2565865638 SBCU6_CellVolt1_CellNO 1;
BA_ "GenSigMaxValue" SG_ 2565865638 SBCU6_CellVolt1_CellNO 255;
BA_ "GenSigSendType" SG_ 2565865638 SBCU6_CellVolt1_BMUNO 1;
BA_ "GenSigMaxValue" SG_ 2565865638 SBCU6_CellVolt1_BMUNO 255;
BA_ "GenSigSendType" SG_ 2565865638 SBCU6_CellVolt1 1;
BA_ "GenSigMaxValue" SG_ 2565865638 SBCU6_CellVolt1 65535;
BA_ "GenSigSendType" SG_ 2565865637 SBCU5_CellVolt2_CellNO 1;
BA_ "GenSigMaxValue" SG_ 2565865637 SBCU5_CellVolt2_CellNO 255;
BA_ "GenSigSendType" SG_ 2565865637 SBCU5_CellVolt2_BMUNO 1;
BA_ "GenSigMaxValue" SG_ 2565865637 SBCU5_CellVolt2_BMUNO 255;
BA_ "GenSigSendType" SG_ 2565865637 SBCU5_CellVolt2 1;
BA_ "GenSigMaxValue" SG_ 2565865637 SBCU5_CellVolt2 65535;
BA_ "GenSigSendType" SG_ 2565865637 SBCU5_CellVolt1_CellNO 1;
BA_ "GenSigMaxValue" SG_ 2565865637 SBCU5_CellVolt1_CellNO 255;
BA_ "GenSigSendType" SG_ 2565865637 SBCU5_CellVolt1_BMUNO 1;
BA_ "GenSigMaxValue" SG_ 2565865637 SBCU5_CellVolt1_BMUNO 255;
BA_ "GenSigSendType" SG_ 2565865637 SBCU5_CellVolt1 1;
BA_ "GenSigMaxValue" SG_ 2565865637 SBCU5_CellVolt1 65535;
BA_ "GenSigSendType" SG_ 2565865636 SBCU4_CellVolt2_CellNO 1;
BA_ "GenSigMaxValue" SG_ 2565865636 SBCU4_CellVolt2_CellNO 255;
BA_ "GenSigSendType" SG_ 2565865636 SBCU4_CellVolt2_BMUNO 1;
BA_ "GenSigMaxValue" SG_ 2565865636 SBCU4_CellVolt2_BMUNO 255;
BA_ "GenSigSendType" SG_ 2565865636 SBCU4_CellVolt2 1;
BA_ "GenSigMaxValue" SG_ 2565865636 SBCU4_CellVolt2 65535;
BA_ "GenSigSendType" SG_ 2565865636 SBCU4_CellVolt1_CellNO 1;
BA_ "GenSigMaxValue" SG_ 2565865636 SBCU4_CellVolt1_CellNO 255;
BA_ "GenSigSendType" SG_ 2565865636 SBCU4_CellVolt1_BMUNO 1;
BA_ "GenSigMaxValue" SG_ 2565865636 SBCU4_CellVolt1_BMUNO 255;
BA_ "GenSigSendType" SG_ 2565865636 SBCU4_CellVolt1 1;
BA_ "GenSigMaxValue" SG_ 2565865636 SBCU4_CellVolt1 65535;
BA_ "GenSigSendType" SG_ 2565865635 SBCU3_CellVolt2_CellNO 1;
BA_ "GenSigMaxValue" SG_ 2565865635 SBCU3_CellVolt2_CellNO 255;
BA_ "GenSigSendType" SG_ 2565865635 SBCU3_CellVolt2_BMUNO 1;
BA_ "GenSigMaxValue" SG_ 2565865635 SBCU3_CellVolt2_BMUNO 255;
BA_ "GenSigSendType" SG_ 2565865635 SBCU3_CellVolt2 1;
BA_ "GenSigMaxValue" SG_ 2565865635 SBCU3_CellVolt2 65535;
BA_ "GenSigSendType" SG_ 2565865635 SBCU3_CellVolt1_CellNO 1;
BA_ "GenSigMaxValue" SG_ 2565865635 SBCU3_CellVolt1_CellNO 255;
BA_ "GenSigSendType" SG_ 2565865635 SBCU3_CellVolt1_BMUNO 1;
BA_ "GenSigMaxValue" SG_ 2565865635 SBCU3_CellVolt1_BMUNO 255;
BA_ "GenSigSendType" SG_ 2565865635 SBCU3_CellVolt1 1;
BA_ "GenSigMaxValue" SG_ 2565865635 SBCU3_CellVolt1 65535;
BA_ "GenSigSendType" SG_ 2565865634 SBCU2_CellVolt2_CellNO 1;
BA_ "GenSigMaxValue" SG_ 2565865634 SBCU2_CellVolt2_CellNO 255;
BA_ "GenSigSendType" SG_ 2565865634 SBCU2_CellVolt2_BMUNO 1;
BA_ "GenSigMaxValue" SG_ 2565865634 SBCU2_CellVolt2_BMUNO 255;
BA_ "GenSigSendType" SG_ 2565865634 SBCU2_CellVolt2 1;
BA_ "GenSigMaxValue" SG_ 2565865634 SBCU2_CellVolt2 65535;
BA_ "GenSigSendType" SG_ 2565865634 SBCU2_CellVolt1_CellNO 1;
BA_ "GenSigMaxValue" SG_ 2565865634 SBCU2_CellVolt1_CellNO 255;
BA_ "GenSigSendType" SG_ 2565865634 SBCU2_CellVolt1_BMUNO 1;
BA_ "GenSigMaxValue" SG_ 2565865634 SBCU2_CellVolt1_BMUNO 255;
BA_ "GenSigSendType" SG_ 2565865634 SBCU2_CellVolt1 1;
BA_ "GenSigMaxValue" SG_ 2565865634 SBCU2_CellVolt1 65535;
BA_ "GenSigSendType" SG_ 2565865633 SBCU1_CellVolt2_CellNO 1;
BA_ "GenSigMaxValue" SG_ 2565865633 SBCU1_CellVolt2_CellNO 255;
BA_ "GenSigSendType" SG_ 2565865633 SBCU1_CellVolt2_BMUNO 1;
BA_ "GenSigMaxValue" SG_ 2565865633 SBCU1_CellVolt2_BMUNO 255;
BA_ "GenSigSendType" SG_ 2565865633 SBCU1_CellVolt2 1;
BA_ "GenSigMaxValue" SG_ 2565865633 SBCU1_CellVolt2 65535;
BA_ "GenSigSendType" SG_ 2565865633 SBCU1_CellVolt1_CellNO 1;
BA_ "GenSigMaxValue" SG_ 2565865633 SBCU1_CellVolt1_CellNO 255;
BA_ "GenSigSendType" SG_ 2565865633 SBCU1_CellVolt1_BMUNO 1;
BA_ "GenSigMaxValue" SG_ 2565865633 SBCU1_CellVolt1_BMUNO 255;
BA_ "GenSigSendType" SG_ 2565865633 SBCU1_CellVolt1 1;
BA_ "GenSigMaxValue" SG_ 2565865633 SBCU1_CellVolt1 65535;
BA_ "GenSigSendType" SG_ 1777 DiagnosticRespBMS_b7 1;
BA_ "GenSigMaxValue" SG_ 1777 DiagnosticRespBMS_b7 255;
BA_ "GenSigSendType" SG_ 1777 DiagnosticRespBMS_b6 1;
BA_ "GenSigMaxValue" SG_ 1777 DiagnosticRespBMS_b6 255;
BA_ "GenSigSendType" SG_ 1777 DiagnosticRespBMS_b5 1;
BA_ "GenSigMaxValue" SG_ 1777 DiagnosticRespBMS_b5 255;
BA_ "GenSigSendType" SG_ 1777 DiagnosticRespBMS_b4 1;
BA_ "GenSigMaxValue" SG_ 1777 DiagnosticRespBMS_b4 255;
BA_ "GenSigSendType" SG_ 1777 DiagnosticRespBMS_b3 1;
BA_ "GenSigMaxValue" SG_ 1777 DiagnosticRespBMS_b3 255;
BA_ "GenSigSendType" SG_ 1777 DiagnosticRespBMS_b2 1;
BA_ "GenSigMaxValue" SG_ 1777 DiagnosticRespBMS_b2 255;
BA_ "GenSigSendType" SG_ 1777 DiagnosticRespBMS_b1 1;
BA_ "GenSigMaxValue" SG_ 1777 DiagnosticRespBMS_b1 255;
BA_ "GenSigSendType" SG_ 1777 DiagnosticRespBMS_b0 1;
BA_ "GenSigMaxValue" SG_ 1777 DiagnosticRespBMS_b0 255;
BA_ "GenSigSendType" SG_ 1761 DiagnosticReqBMS_b7 1;
BA_ "GenSigMaxValue" SG_ 1761 DiagnosticReqBMS_b7 255;
BA_ "GenSigSendType" SG_ 1761 DiagnosticReqBMS_b6 1;
BA_ "GenSigMaxValue" SG_ 1761 DiagnosticReqBMS_b6 255;
BA_ "GenSigSendType" SG_ 1761 DiagnosticReqBMS_b5 1;
BA_ "GenSigMaxValue" SG_ 1761 DiagnosticReqBMS_b5 255;
BA_ "GenSigSendType" SG_ 1761 DiagnosticReqBMS_b4 1;
BA_ "GenSigMaxValue" SG_ 1761 DiagnosticReqBMS_b4 255;
BA_ "GenSigSendType" SG_ 1761 DiagnosticReqBMS_b3 1;
BA_ "GenSigMaxValue" SG_ 1761 DiagnosticReqBMS_b3 255;
BA_ "GenSigSendType" SG_ 1761 DiagnosticReqBMS_b2 1;
BA_ "GenSigMaxValue" SG_ 1761 DiagnosticReqBMS_b2 255;
BA_ "GenSigSendType" SG_ 1761 DiagnosticReqBMS_b1 1;
BA_ "GenSigMaxValue" SG_ 1761 DiagnosticReqBMS_b1 255;
BA_ "GenSigSendType" SG_ 1761 DiagnosticReqBMS_b0 1;
BA_ "GenSigMaxValue" SG_ 1761 DiagnosticReqBMS_b0 255;
BA_ "GenSigSendType" SG_ 1745 DiagnosticFuncAddrReq_b7 1;
BA_ "GenSigMaxValue" SG_ 1745 DiagnosticFuncAddrReq_b7 255;
BA_ "GenSigSendType" SG_ 1745 DiagnosticFuncAddrReq_b6 1;
BA_ "GenSigMaxValue" SG_ 1745 DiagnosticFuncAddrReq_b6 255;
BA_ "GenSigSendType" SG_ 1745 DiagnosticFuncAddrReq_b5 1;
BA_ "GenSigMaxValue" SG_ 1745 DiagnosticFuncAddrReq_b5 255;
BA_ "GenSigSendType" SG_ 1745 DiagnosticFuncAddrReq_b4 1;
BA_ "GenSigMaxValue" SG_ 1745 DiagnosticFuncAddrReq_b4 255;
BA_ "GenSigSendType" SG_ 1745 DiagnosticFuncAddrReq_b3 1;
BA_ "GenSigMaxValue" SG_ 1745 DiagnosticFuncAddrReq_b3 255;
BA_ "GenSigSendType" SG_ 1745 DiagnosticFuncAddrReq_b2 1;
BA_ "GenSigMaxValue" SG_ 1745 DiagnosticFuncAddrReq_b2 255;
BA_ "GenSigSendType" SG_ 1745 DiagnosticFuncAddrReq_b1 1;
BA_ "GenSigMaxValue" SG_ 1745 DiagnosticFuncAddrReq_b1 255;
BA_ "GenSigSendType" SG_ 1745 DiagnosticFuncAddrReq_b0 1;
BA_ "GenSigMaxValue" SG_ 1745 DiagnosticFuncAddrReq_b0 255;
BA_ "GenSigSendType" SG_ 2550898858 SBCU10_Accum_DchEng 1;
BA_ "GenSigMaxValue" SG_ 2550898858 SBCU10_Accum_DchEng 2147483647;
BA_ "GenSigSendType" SG_ 2550898858 SBCU10_Accum_ChgEng 1;
BA_ "GenSigMaxValue" SG_ 2550898858 SBCU10_Accum_ChgEng 2147483647;
BA_ "GenSigSendType" SG_ 2550833322 SBCU10_Accum_DchCap 1;
BA_ "GenSigMaxValue" SG_ 2550833322 SBCU10_Accum_DchCap 2147483647;
BA_ "GenSigSendType" SG_ 2550833322 SBCU10_Accum_ChgCap 1;
BA_ "GenSigMaxValue" SG_ 2550833322 SBCU10_Accum_ChgCap 2147483647;
BA_ "GenSigSendType" SG_ 2550374570 SBCU10_SOH 1;
BA_ "GenSigMaxValue" SG_ 2550374570 SBCU10_SOH 4095;
BA_ "GenSigSendType" SG_ 2550374570 SBCU10_PowerSupply_Volt 1;
BA_ "GenSigMaxValue" SG_ 2550374570 SBCU10_PowerSupply_Volt 4095;
BA_ "GenSigSendType" SG_ 2550374570 SBCU10_Isolation 1;
BA_ "GenSigMaxValue" SG_ 2550374570 SBCU10_Isolation 65535;
BA_ "GenSigSendType" SG_ 2550374570 SBCU10_AI3_Value 1;
BA_ "GenSigMaxValue" SG_ 2550374570 SBCU10_AI3_Value 255;
BA_ "GenSigSendType" SG_ 2550374570 SBCU10_AI2_Value 1;
BA_ "GenSigMaxValue" SG_ 2550374570 SBCU10_AI2_Value 255;
BA_ "GenSigSendType" SG_ 2550374570 SBCU10_AI1_Value 1;
BA_ "GenSigMaxValue" SG_ 2550374570 SBCU10_AI1_Value 255;
BA_ "GenSigSendType" SG_ 2348982442 SBCU10_WorkMode 1;
BA_ "GenSigMaxValue" SG_ 2348982442 SBCU10_WorkMode 15;
BA_ "GenSigSendType" SG_ 2348982442 SBCU10_Ready 1;
BA_ "GenSigMaxValue" SG_ 2348982442 SBCU10_Ready 3;
BA_ "GenSigSendType" SG_ 2348982442 SBCU10_PreChgRelay_Status 1;
BA_ "GenSigMaxValue" SG_ 2348982442 SBCU10_PreChgRelay_Status 3;
BA_ "GenSigSendType" SG_ 2348982442 SBCU10_PosRelay_Status 1;
BA_ "GenSigMaxValue" SG_ 2348982442 SBCU10_PosRelay_Status 3;
BA_ "GenSigSendType" SG_ 2348982442 SBCU10_PosIso_Optical 1;
BA_ "GenSigMaxValue" SG_ 2348982442 SBCU10_PosIso_Optical 1;
BA_ "GenSigSendType" SG_ 2348982442 SBCU10_NegRelay_Status 1;
BA_ "GenSigMaxValue" SG_ 2348982442 SBCU10_NegRelay_Status 3;
BA_ "GenSigSendType" SG_ 2348982442 SBCU10_NegIso_Optical 1;
BA_ "GenSigMaxValue" SG_ 2348982442 SBCU10_NegIso_Optical 1;
BA_ "GenSigSendType" SG_ 2348982442 SBCU10_Life 1;
BA_ "GenSigMaxValue" SG_ 2348982442 SBCU10_Life 15;
BA_ "GenSigSendType" SG_ 2348982442 SBCU10_ISO_Status 1;
BA_ "GenSigMaxValue" SG_ 2348982442 SBCU10_ISO_Status 3;
BA_ "GenSigSendType" SG_ 2348982442 SBCU10_ISO_Allow 1;
BA_ "GenSigMaxValue" SG_ 2348982442 SBCU10_ISO_Allow 3;
BA_ "GenSigSendType" SG_ 2348982442 SBCU10_HVOff_Req 1;
BA_ "GenSigMaxValue" SG_ 2348982442 SBCU10_HVOff_Req 3;
BA_ "GenSigSendType" SG_ 2348982442 SBCU10_HV_Step 1;
BA_ "GenSigMaxValue" SG_ 2348982442 SBCU10_HV_Step 15;
BA_ "GenSigSendType" SG_ 2348982442 SBCU10_HeatRelay_Status 1;
BA_ "GenSigMaxValue" SG_ 2348982442 SBCU10_HeatRelay_Status 3;
BA_ "GenSigSendType" SG_ 2348982442 SBCU10_FcgRelay_Status 1;
BA_ "GenSigMaxValue" SG_ 2348982442 SBCU10_FcgRelay_Status 3;
BA_ "GenSigSendType" SG_ 2348982442 SBCU10_FaultLevel 1;
BA_ "GenSigMaxValue" SG_ 2348982442 SBCU10_FaultLevel 3;
BA_ "GenSigSendType" SG_ 2348982442 SBCU10_FaultCode 1;
BA_ "GenSigMaxValue" SG_ 2348982442 SBCU10_FaultCode 65535;
BA_ "GenSigSendType" SG_ 2348982442 SBCU10_FanRelay_Status 1;
BA_ "GenSigMaxValue" SG_ 2348982442 SBCU10_FanRelay_Status 3;
BA_ "GenSigSendType" SG_ 2348982442 SBCU10_DO3_Ctrl 1;
BA_ "GenSigMaxValue" SG_ 2348982442 SBCU10_DO3_Ctrl 1;
BA_ "GenSigSendType" SG_ 2348982442 SBCU10_DO2_Ctrl 1;
BA_ "GenSigMaxValue" SG_ 2348982442 SBCU10_DO2_Ctrl 1;
BA_ "GenSigSendType" SG_ 2348982442 SBCU10_DO1_Ctrl 1;
BA_ "GenSigMaxValue" SG_ 2348982442 SBCU10_DO1_Ctrl 1;
BA_ "GenSigSendType" SG_ 2348982442 SBCU10_DI5_Status 1;
BA_ "GenSigMaxValue" SG_ 2348982442 SBCU10_DI5_Status 1;
BA_ "GenSigSendType" SG_ 2348982442 SBCU10_DI4_Status 1;
BA_ "GenSigMaxValue" SG_ 2348982442 SBCU10_DI4_Status 1;
BA_ "GenSigSendType" SG_ 2348982442 SBCU10_DI3_Status 1;
BA_ "GenSigMaxValue" SG_ 2348982442 SBCU10_DI3_Status 1;
BA_ "GenSigSendType" SG_ 2348982442 SBCU10_DI2_Status 1;
BA_ "GenSigMaxValue" SG_ 2348982442 SBCU10_DI2_Status 1;
BA_ "GenSigSendType" SG_ 2348982442 SBCU10_DI1_Status 1;
BA_ "GenSigMaxValue" SG_ 2348982442 SBCU10_DI1_Status 1;
BA_ "GenSigSendType" SG_ 2348982442 SBCU10_BMS_RunStatus 1;
BA_ "GenSigMaxValue" SG_ 2348982442 SBCU10_BMS_RunStatus 15;
BA_ "GenSigSendType" SG_ 2550505642 SBCU10_DchPeakPower_Limit 1;
BA_ "GenSigMaxValue" SG_ 2550505642 SBCU10_DchPeakPower_Limit 65535;
BA_ "GenSigSendType" SG_ 2550505642 SBCU10_DchContinuousPower_Limit 1;
BA_ "GenSigMaxValue" SG_ 2550505642 SBCU10_DchContinuousPower_Limit 65535;
BA_ "GenSigSendType" SG_ 2550505642 SBCU10_ChgPeakPower_Limit 1;
BA_ "GenSigMaxValue" SG_ 2550505642 SBCU10_ChgPeakPower_Limit 65535;
BA_ "GenSigSendType" SG_ 2550505642 SBCU10_ChgContinuousPower_Limit 1;
BA_ "GenSigMaxValue" SG_ 2550505642 SBCU10_ChgContinuousPower_Limit 65535;
BA_ "GenSigSendType" SG_ 2550440106 SBCU10_DchPeakCurr_Limit 1;
BA_ "GenSigMaxValue" SG_ 2550440106 SBCU10_DchPeakCurr_Limit 65535;
BA_ "GenSigSendType" SG_ 2550440106 SBCU10_DchContinuousCurr_Limit 1;
BA_ "GenSigMaxValue" SG_ 2550440106 SBCU10_DchContinuousCurr_Limit 65535;
BA_ "GenSigSendType" SG_ 2550440106 SBCU10_ChgPeakCurr_Limit 1;
BA_ "GenSigMaxValue" SG_ 2550440106 SBCU10_ChgPeakCurr_Limit 65535;
BA_ "GenSigSendType" SG_ 2550440106 SBCU10_ChgContinuousCurr_Limit 1;
BA_ "GenSigMaxValue" SG_ 2550440106 SBCU10_ChgContinuousCurr_Limit 65535;
BA_ "GenSigSendType" SG_ 2550636714 SBCU10_CellVolt_Min_CellNO 1;
BA_ "GenSigMaxValue" SG_ 2550636714 SBCU10_CellVolt_Min_CellNO 255;
BA_ "GenSigSendType" SG_ 2550636714 SBCU10_CellVolt_Min_BMUNO 1;
BA_ "GenSigMaxValue" SG_ 2550636714 SBCU10_CellVolt_Min_BMUNO 255;
BA_ "GenSigSendType" SG_ 2550636714 SBCU10_CellVolt_Max_CellNO 1;
BA_ "GenSigMaxValue" SG_ 2550636714 SBCU10_CellVolt_Max_CellNO 255;
BA_ "GenSigSendType" SG_ 2550636714 SBCU10_CellVolt_Max_BMUNO 1;
BA_ "GenSigMaxValue" SG_ 2550636714 SBCU10_CellVolt_Max_BMUNO 255;
BA_ "GenSigSendType" SG_ 2550636714 SBCU10_CellTemp_Min_CellNO 1;
BA_ "GenSigMaxValue" SG_ 2550636714 SBCU10_CellTemp_Min_CellNO 255;
BA_ "GenSigSendType" SG_ 2550636714 SBCU10_CellTemp_Min_BMUNO 1;
BA_ "GenSigMaxValue" SG_ 2550636714 SBCU10_CellTemp_Min_BMUNO 255;
BA_ "GenSigSendType" SG_ 2550636714 SBCU10_CellTemp_Max_CellNO 1;
BA_ "GenSigMaxValue" SG_ 2550636714 SBCU10_CellTemp_Max_CellNO 255;
BA_ "GenSigSendType" SG_ 2550636714 SBCU10_CellTemp_Max_BMUNO 1;
BA_ "GenSigMaxValue" SG_ 2550636714 SBCU10_CellTemp_Max_BMUNO 255;
BA_ "GenSigSendType" SG_ 2550571178 SBCU10_CellVolt_Min 1;
BA_ "GenSigMaxValue" SG_ 2550571178 SBCU10_CellVolt_Min 65535;
BA_ "GenSigSendType" SG_ 2550571178 SBCU10_CellVolt_Mean 1;
BA_ "GenSigMaxValue" SG_ 2550571178 SBCU10_CellVolt_Mean 65535;
BA_ "GenSigSendType" SG_ 2550571178 SBCU10_CellVolt_Max 1;
BA_ "GenSigMaxValue" SG_ 2550571178 SBCU10_CellVolt_Max 65535;
BA_ "GenSigSendType" SG_ 2550571178 SBCU10_CellTemp_Min 1;
BA_ "GenSigMaxValue" SG_ 2550571178 SBCU10_CellTemp_Min 255;
BA_ "GenSigSendType" SG_ 2550571178 SBCU10_CellTemp_Max 1;
BA_ "GenSigMaxValue" SG_ 2550571178 SBCU10_CellTemp_Max 255;
BA_ "GenSigSendType" SG_ 2550702250 SBCU10_NTC2 1;
BA_ "GenSigMaxValue" SG_ 2550702250 SBCU10_NTC2 255;
BA_ "GenSigSendType" SG_ 2550702250 SBCU10_NTC1 1;
BA_ "GenSigMaxValue" SG_ 2550702250 SBCU10_NTC1 255;
BA_ "GenSigSendType" SG_ 2550702250 SBCU10_ISO_PosVolt 1;
BA_ "GenSigMaxValue" SG_ 2550702250 SBCU10_ISO_PosVolt 65535;
BA_ "GenSigSendType" SG_ 2550702250 SBCU10_ISO_NegVolt 1;
BA_ "GenSigMaxValue" SG_ 2550702250 SBCU10_ISO_NegVolt 65535;
BA_ "GenSigSendType" SG_ 2550702250 SBCU10_CellVolt_Sum 1;
BA_ "GenSigMaxValue" SG_ 2550702250 SBCU10_CellVolt_Sum 65535;
BA_ "GenSigSendType" SG_ 2550898857 SBCU9_Accum_DchEng 1;
BA_ "GenSigMaxValue" SG_ 2550898857 SBCU9_Accum_DchEng 2147483647;
BA_ "GenSigSendType" SG_ 2550898857 SBCU9_Accum_ChgEng 1;
BA_ "GenSigMaxValue" SG_ 2550898857 SBCU9_Accum_ChgEng 2147483647;
BA_ "GenSigSendType" SG_ 2550833321 SBCU9_Accum_DchCap 1;
BA_ "GenSigMaxValue" SG_ 2550833321 SBCU9_Accum_DchCap 2147483647;
BA_ "GenSigSendType" SG_ 2550833321 SBCU9_Accum_ChgCap 1;
BA_ "GenSigMaxValue" SG_ 2550833321 SBCU9_Accum_ChgCap 2147483647;
BA_ "GenSigSendType" SG_ 2550374569 SBCU9_SOH 1;
BA_ "GenSigMaxValue" SG_ 2550374569 SBCU9_SOH 4095;
BA_ "GenSigSendType" SG_ 2550374569 SBCU9_PowerSupply_Volt 1;
BA_ "GenSigMaxValue" SG_ 2550374569 SBCU9_PowerSupply_Volt 4095;
BA_ "GenSigSendType" SG_ 2550374569 SBCU9_Isolation 1;
BA_ "GenSigMaxValue" SG_ 2550374569 SBCU9_Isolation 65535;
BA_ "GenSigSendType" SG_ 2550374569 SBCU9_AI3_Value 1;
BA_ "GenSigMaxValue" SG_ 2550374569 SBCU9_AI3_Value 255;
BA_ "GenSigSendType" SG_ 2550374569 SBCU9_AI2_Value 1;
BA_ "GenSigMaxValue" SG_ 2550374569 SBCU9_AI2_Value 255;
BA_ "GenSigSendType" SG_ 2550374569 SBCU9_AI1_Value 1;
BA_ "GenSigMaxValue" SG_ 2550374569 SBCU9_AI1_Value 255;
BA_ "GenSigSendType" SG_ 2348982441 SBCU9_WorkMode 1;
BA_ "GenSigMaxValue" SG_ 2348982441 SBCU9_WorkMode 15;
BA_ "GenSigSendType" SG_ 2348982441 SBCU9_Ready 1;
BA_ "GenSigMaxValue" SG_ 2348982441 SBCU9_Ready 3;
BA_ "GenSigSendType" SG_ 2348982441 SBCU9_PreChgRelay_Status 1;
BA_ "GenSigMaxValue" SG_ 2348982441 SBCU9_PreChgRelay_Status 3;
BA_ "GenSigSendType" SG_ 2348982441 SBCU9_PosRelay_Status 1;
BA_ "GenSigMaxValue" SG_ 2348982441 SBCU9_PosRelay_Status 3;
BA_ "GenSigSendType" SG_ 2348982441 SBCU9_PosIso_Optical 1;
BA_ "GenSigMaxValue" SG_ 2348982441 SBCU9_PosIso_Optical 1;
BA_ "GenSigSendType" SG_ 2348982441 SBCU9_NegRelay_Status 1;
BA_ "GenSigMaxValue" SG_ 2348982441 SBCU9_NegRelay_Status 3;
BA_ "GenSigSendType" SG_ 2348982441 SBCU9_NegIso_Optical 1;
BA_ "GenSigMaxValue" SG_ 2348982441 SBCU9_NegIso_Optical 1;
BA_ "GenSigSendType" SG_ 2348982441 SBCU9_Life 1;
BA_ "GenSigMaxValue" SG_ 2348982441 SBCU9_Life 15;
BA_ "GenSigSendType" SG_ 2348982441 SBCU9_ISO_Status 1;
BA_ "GenSigMaxValue" SG_ 2348982441 SBCU9_ISO_Status 3;
BA_ "GenSigSendType" SG_ 2348982441 SBCU9_ISO_Allow 1;
BA_ "GenSigMaxValue" SG_ 2348982441 SBCU9_ISO_Allow 3;
BA_ "GenSigSendType" SG_ 2348982441 SBCU9_HVOff_Req 1;
BA_ "GenSigMaxValue" SG_ 2348982441 SBCU9_HVOff_Req 3;
BA_ "GenSigSendType" SG_ 2348982441 SBCU9_HV_Step 1;
BA_ "GenSigMaxValue" SG_ 2348982441 SBCU9_HV_Step 15;
BA_ "GenSigSendType" SG_ 2348982441 SBCU9_HeatRelay_Status 1;
BA_ "GenSigMaxValue" SG_ 2348982441 SBCU9_HeatRelay_Status 3;
BA_ "GenSigSendType" SG_ 2348982441 SBCU9_FcgRelay_Status 1;
BA_ "GenSigMaxValue" SG_ 2348982441 SBCU9_FcgRelay_Status 3;
BA_ "GenSigSendType" SG_ 2348982441 SBCU9_FaultLevel 1;
BA_ "GenSigMaxValue" SG_ 2348982441 SBCU9_FaultLevel 3;
BA_ "GenSigSendType" SG_ 2348982441 SBCU9_FaultCode 1;
BA_ "GenSigMaxValue" SG_ 2348982441 SBCU9_FaultCode 65535;
BA_ "GenSigSendType" SG_ 2348982441 SBCU9_FanRelay_Status 1;
BA_ "GenSigMaxValue" SG_ 2348982441 SBCU9_FanRelay_Status 3;
BA_ "GenSigSendType" SG_ 2348982441 SBCU9_DO3_Ctrl 1;
BA_ "GenSigMaxValue" SG_ 2348982441 SBCU9_DO3_Ctrl 1;
BA_ "GenSigSendType" SG_ 2348982441 SBCU9_DO2_Ctrl 1;
BA_ "GenSigMaxValue" SG_ 2348982441 SBCU9_DO2_Ctrl 1;
BA_ "GenSigSendType" SG_ 2348982441 SBCU9_DO1_Ctrl 1;
BA_ "GenSigMaxValue" SG_ 2348982441 SBCU9_DO1_Ctrl 1;
BA_ "GenSigSendType" SG_ 2348982441 SBCU9_DI5_Status 1;
BA_ "GenSigMaxValue" SG_ 2348982441 SBCU9_DI5_Status 1;
BA_ "GenSigSendType" SG_ 2348982441 SBCU9_DI4_Status 1;
BA_ "GenSigMaxValue" SG_ 2348982441 SBCU9_DI4_Status 1;
BA_ "GenSigSendType" SG_ 2348982441 SBCU9_DI3_Status 1;
BA_ "GenSigMaxValue" SG_ 2348982441 SBCU9_DI3_Status 1;
BA_ "GenSigSendType" SG_ 2348982441 SBCU9_DI2_Status 1;
BA_ "GenSigMaxValue" SG_ 2348982441 SBCU9_DI2_Status 1;
BA_ "GenSigSendType" SG_ 2348982441 SBCU9_DI1_Status 1;
BA_ "GenSigMaxValue" SG_ 2348982441 SBCU9_DI1_Status 1;
BA_ "GenSigSendType" SG_ 2348982441 SBCU9_BMS_RunStatus 1;
BA_ "GenSigMaxValue" SG_ 2348982441 SBCU9_BMS_RunStatus 15;
BA_ "GenSigSendType" SG_ 2550505641 SBCU9_DchPeakPower_Limit 1;
BA_ "GenSigMaxValue" SG_ 2550505641 SBCU9_DchPeakPower_Limit 65535;
BA_ "GenSigSendType" SG_ 2550505641 SBCU9_DchContinuousPower_Limit 1;
BA_ "GenSigMaxValue" SG_ 2550505641 SBCU9_DchContinuousPower_Limit 65535;
BA_ "GenSigSendType" SG_ 2550505641 SBCU9_ChgPeakPower_Limit 1;
BA_ "GenSigMaxValue" SG_ 2550505641 SBCU9_ChgPeakPower_Limit 65535;
BA_ "GenSigSendType" SG_ 2550505641 SBCU9_ChgContinuousPower_Limit 1;
BA_ "GenSigMaxValue" SG_ 2550505641 SBCU9_ChgContinuousPower_Limit 65535;
BA_ "GenSigSendType" SG_ 2550440105 SBCU9_DchPeakCurr_Limit 1;
BA_ "GenSigMaxValue" SG_ 2550440105 SBCU9_DchPeakCurr_Limit 65535;
BA_ "GenSigSendType" SG_ 2550440105 SBCU9_DchContinuousCurr_Limit 1;
BA_ "GenSigMaxValue" SG_ 2550440105 SBCU9_DchContinuousCurr_Limit 65535;
BA_ "GenSigSendType" SG_ 2550440105 SBCU9_ChgPeakCurr_Limit 1;
BA_ "GenSigMaxValue" SG_ 2550440105 SBCU9_ChgPeakCurr_Limit 65535;
BA_ "GenSigSendType" SG_ 2550440105 SBCU9_ChgContinuousCurr_Limit 1;
BA_ "GenSigMaxValue" SG_ 2550440105 SBCU9_ChgContinuousCurr_Limit 65535;
BA_ "GenSigSendType" SG_ 2550636713 SBCU9_CellVolt_Min_CellNO 1;
BA_ "GenSigMaxValue" SG_ 2550636713 SBCU9_CellVolt_Min_CellNO 255;
BA_ "GenSigSendType" SG_ 2550636713 SBCU9_CellVolt_Min_BMUNO 1;
BA_ "GenSigMaxValue" SG_ 2550636713 SBCU9_CellVolt_Min_BMUNO 255;
BA_ "GenSigSendType" SG_ 2550636713 SBCU9_CellVolt_Max_CellNO 1;
BA_ "GenSigMaxValue" SG_ 2550636713 SBCU9_CellVolt_Max_CellNO 255;
BA_ "GenSigSendType" SG_ 2550636713 SBCU9_CellVolt_Max_BMUNO 1;
BA_ "GenSigMaxValue" SG_ 2550636713 SBCU9_CellVolt_Max_BMUNO 255;
BA_ "GenSigSendType" SG_ 2550636713 SBCU9_CellTemp_Min_CellNO 1;
BA_ "GenSigMaxValue" SG_ 2550636713 SBCU9_CellTemp_Min_CellNO 255;
BA_ "GenSigSendType" SG_ 2550636713 SBCU9_CellTemp_Min_BMUNO 1;
BA_ "GenSigMaxValue" SG_ 2550636713 SBCU9_CellTemp_Min_BMUNO 255;
BA_ "GenSigSendType" SG_ 2550636713 SBCU9_CellTemp_Max_CellNO 1;
BA_ "GenSigMaxValue" SG_ 2550636713 SBCU9_CellTemp_Max_CellNO 255;
BA_ "GenSigSendType" SG_ 2550636713 SBCU9_CellTemp_Max_BMUNO 1;
BA_ "GenSigMaxValue" SG_ 2550636713 SBCU9_CellTemp_Max_BMUNO 255;
BA_ "GenSigSendType" SG_ 2550571177 SBCU9_CellVolt_Min 1;
BA_ "GenSigMaxValue" SG_ 2550571177 SBCU9_CellVolt_Min 65535;
BA_ "GenSigSendType" SG_ 2550571177 SBCU9_CellVolt_Mean 1;
BA_ "GenSigMaxValue" SG_ 2550571177 SBCU9_CellVolt_Mean 65535;
BA_ "GenSigSendType" SG_ 2550571177 SBCU9_CellVolt_Max 1;
BA_ "GenSigMaxValue" SG_ 2550571177 SBCU9_CellVolt_Max 65535;
BA_ "GenSigSendType" SG_ 2550571177 SBCU9_CellTemp_Min 1;
BA_ "GenSigMaxValue" SG_ 2550571177 SBCU9_CellTemp_Min 255;
BA_ "GenSigSendType" SG_ 2550571177 SBCU9_CellTemp_Max 1;
BA_ "GenSigMaxValue" SG_ 2550571177 SBCU9_CellTemp_Max 255;
BA_ "GenSigSendType" SG_ 2550702249 SBCU9_NTC2 1;
BA_ "GenSigMaxValue" SG_ 2550702249 SBCU9_NTC2 255;
BA_ "GenSigSendType" SG_ 2550702249 SBCU9_NTC1 1;
BA_ "GenSigMaxValue" SG_ 2550702249 SBCU9_NTC1 255;
BA_ "GenSigSendType" SG_ 2550702249 SBCU9_ISO_PosVolt 1;
BA_ "GenSigMaxValue" SG_ 2550702249 SBCU9_ISO_PosVolt 65535;
BA_ "GenSigSendType" SG_ 2550702249 SBCU9_ISO_NegVolt 1;
BA_ "GenSigMaxValue" SG_ 2550702249 SBCU9_ISO_NegVolt 65535;
BA_ "GenSigSendType" SG_ 2550702249 SBCU9_CellVolt_Sum 1;
BA_ "GenSigMaxValue" SG_ 2550702249 SBCU9_CellVolt_Sum 65535;
BA_ "GenSigSendType" SG_ 2566652074 SBCU10_CellBalance_Pack_NO 1;
BA_ "GenSigMaxValue" SG_ 2566652074 SBCU10_CellBalance_Pack_NO 255;
BA_ "GenSigSendType" SG_ 2566652074 SBCU10_CellBalance049 1;
BA_ "GenSigMaxValue" SG_ 2566652074 SBCU10_CellBalance049 255;
BA_ "GenSigSendType" SG_ 2566652074 SBCU10_CellBalance041 1;
BA_ "GenSigMaxValue" SG_ 2566652074 SBCU10_CellBalance041 255;
BA_ "GenSigSendType" SG_ 2566652074 SBCU10_CellBalance033 1;
BA_ "GenSigMaxValue" SG_ 2566652074 SBCU10_CellBalance033 255;
BA_ "GenSigSendType" SG_ 2566652074 SBCU10_CellBalance025 1;
BA_ "GenSigMaxValue" SG_ 2566652074 SBCU10_CellBalance025 255;
BA_ "GenSigSendType" SG_ 2566652074 SBCU10_CellBalance017 1;
BA_ "GenSigMaxValue" SG_ 2566652074 SBCU10_CellBalance017 255;
BA_ "GenSigSendType" SG_ 2566652074 SBCU10_CellBalance009 1;
BA_ "GenSigMaxValue" SG_ 2566652074 SBCU10_CellBalance009 255;
BA_ "GenSigSendType" SG_ 2566652074 SBCU10_CellBalance001 1;
BA_ "GenSigMaxValue" SG_ 2566652074 SBCU10_CellBalance001 255;
BA_ "GenSigSendType" SG_ 2566652073 SBCU9_CellBalance_Pack_NO 1;
BA_ "GenSigMaxValue" SG_ 2566652073 SBCU9_CellBalance_Pack_NO 255;
BA_ "GenSigSendType" SG_ 2566652073 SBCU9_CellBalance049 1;
BA_ "GenSigMaxValue" SG_ 2566652073 SBCU9_CellBalance049 255;
BA_ "GenSigSendType" SG_ 2566652073 SBCU9_CellBalance041 1;
BA_ "GenSigMaxValue" SG_ 2566652073 SBCU9_CellBalance041 255;
BA_ "GenSigSendType" SG_ 2566652073 SBCU9_CellBalance033 1;
BA_ "GenSigMaxValue" SG_ 2566652073 SBCU9_CellBalance033 255;
BA_ "GenSigSendType" SG_ 2566652073 SBCU9_CellBalance025 1;
BA_ "GenSigMaxValue" SG_ 2566652073 SBCU9_CellBalance025 255;
BA_ "GenSigSendType" SG_ 2566652073 SBCU9_CellBalance017 1;
BA_ "GenSigMaxValue" SG_ 2566652073 SBCU9_CellBalance017 255;
BA_ "GenSigSendType" SG_ 2566652073 SBCU9_CellBalance009 1;
BA_ "GenSigMaxValue" SG_ 2566652073 SBCU9_CellBalance009 255;
BA_ "GenSigSendType" SG_ 2566652073 SBCU9_CellBalance001 1;
BA_ "GenSigMaxValue" SG_ 2566652073 SBCU9_CellBalance001 255;
BA_ "GenSigSendType" SG_ 2550243498 SBCU10_SOC 1;
BA_ "GenSigMaxValue" SG_ 2550243498 SBCU10_SOC 65535;
BA_ "GenSigSendType" SG_ 2550243498 SBCU10_Pack_Volt 1;
BA_ "GenSigMaxValue" SG_ 2550243498 SBCU10_Pack_Volt 65535;
BA_ "GenSigSendType" SG_ 2550243498 SBCU10_LinkVolt 1;
BA_ "GenSigMaxValue" SG_ 2550243498 SBCU10_LinkVolt 65535;
BA_ "GenSigSendType" SG_ 2550243498 SBCU10_BusCurrent 1;
BA_ "GenSigMaxValue" SG_ 2550243498 SBCU10_BusCurrent 65535;
BA_ "GenSigStartValue" SG_ 2550243498 SBCU10_BusCurrent 32000;
BA_ "GenSigSendType" SG_ 2550243497 SBCU9_SOC 1;
BA_ "GenSigMaxValue" SG_ 2550243497 SBCU9_SOC 65535;
BA_ "GenSigSendType" SG_ 2550243497 SBCU9_Pack_Volt 1;
BA_ "GenSigMaxValue" SG_ 2550243497 SBCU9_Pack_Volt 65535;
BA_ "GenSigSendType" SG_ 2550243497 SBCU9_LinkVolt 1;
BA_ "GenSigMaxValue" SG_ 2550243497 SBCU9_LinkVolt 65535;
BA_ "GenSigSendType" SG_ 2550243497 SBCU9_BusCurrent 1;
BA_ "GenSigMaxValue" SG_ 2550243497 SBCU9_BusCurrent 65535;
BA_ "GenSigStartValue" SG_ 2550243497 SBCU9_BusCurrent 32000;
BA_ "GenSigSendType" SG_ 2550330611 Tester_Hour 1;
BA_ "GenSigMaxValue" SG_ 2550330611 Tester_Hour 255;
BA_ "GenSigSendType" SG_ 2550330611 Tester_Year 1;
BA_ "GenSigMaxValue" SG_ 2550330611 Tester_Year 255;
BA_ "GenSigSendType" SG_ 2550330611 Tester_Time_Update 1;
BA_ "GenSigMaxValue" SG_ 2550330611 Tester_Time_Update 3;
BA_ "GenSigSendType" SG_ 2550330611 Tester_Month 1;
BA_ "GenSigMaxValue" SG_ 2550330611 Tester_Month 255;
BA_ "GenSigSendType" SG_ 2550330611 Tester_Minute 1;
BA_ "GenSigMaxValue" SG_ 2550330611 Tester_Minute 255;
BA_ "GenSigSendType" SG_ 2550330611 Tester_Day 1;
BA_ "GenSigMaxValue" SG_ 2550330611 Tester_Day 255;
BA_ "GenSigSendType" SG_ 2550330611 Tester_Calib_Update 1;
BA_ "GenSigMaxValue" SG_ 2550330611 Tester_Calib_Update 15;
BA_ "GenSigSendType" SG_ 2550330611 Tester_Second 1;
BA_ "GenSigMaxValue" SG_ 2550330611 Tester_Second 255;
BA_ "GenSigSendType" SG_ 2550898856 SBCU8_Accum_DchEng 1;
BA_ "GenSigMaxValue" SG_ 2550898856 SBCU8_Accum_DchEng 2147483647;
BA_ "GenSigSendType" SG_ 2550898856 SBCU8_Accum_ChgEng 1;
BA_ "GenSigMaxValue" SG_ 2550898856 SBCU8_Accum_ChgEng 2147483647;
BA_ "GenSigSendType" SG_ 2550833320 SBCU8_Accum_DchCap 1;
BA_ "GenSigMaxValue" SG_ 2550833320 SBCU8_Accum_DchCap 2147483647;
BA_ "GenSigSendType" SG_ 2550833320 SBCU8_Accum_ChgCap 1;
BA_ "GenSigMaxValue" SG_ 2550833320 SBCU8_Accum_ChgCap 2147483647;
BA_ "GenSigSendType" SG_ 2550374568 SBCU8_Isolation 1;
BA_ "GenSigMaxValue" SG_ 2550374568 SBCU8_Isolation 65535;
BA_ "GenSigSendType" SG_ 2550374568 SBCU8_SOH 1;
BA_ "GenSigMaxValue" SG_ 2550374568 SBCU8_SOH 4095;
BA_ "GenSigSendType" SG_ 2550374568 SBCU8_PowerSupply_Volt 1;
BA_ "GenSigMaxValue" SG_ 2550374568 SBCU8_PowerSupply_Volt 4095;
BA_ "GenSigSendType" SG_ 2550374568 SBCU8_AI1_Value 1;
BA_ "GenSigMaxValue" SG_ 2550374568 SBCU8_AI1_Value 255;
BA_ "GenSigSendType" SG_ 2550374568 SBCU8_AI2_Value 1;
BA_ "GenSigMaxValue" SG_ 2550374568 SBCU8_AI2_Value 255;
BA_ "GenSigSendType" SG_ 2550374568 SBCU8_AI3_Value 1;
BA_ "GenSigMaxValue" SG_ 2550374568 SBCU8_AI3_Value 255;
BA_ "GenSigSendType" SG_ 2348982440 SBCU8_ISO_Status 1;
BA_ "GenSigMaxValue" SG_ 2348982440 SBCU8_ISO_Status 3;
BA_ "GenSigSendType" SG_ 2348982440 SBCU8_DO3_Ctrl 1;
BA_ "GenSigMaxValue" SG_ 2348982440 SBCU8_DO3_Ctrl 1;
BA_ "GenSigSendType" SG_ 2348982440 SBCU8_DI5_Status 1;
BA_ "GenSigMaxValue" SG_ 2348982440 SBCU8_DI5_Status 1;
BA_ "GenSigSendType" SG_ 2348982440 SBCU8_Ready 1;
BA_ "GenSigMaxValue" SG_ 2348982440 SBCU8_Ready 3;
BA_ "GenSigSendType" SG_ 2348982440 SBCU8_HVOff_Req 1;
BA_ "GenSigMaxValue" SG_ 2348982440 SBCU8_HVOff_Req 3;
BA_ "GenSigSendType" SG_ 2348982440 SBCU8_ISO_Allow 1;
BA_ "GenSigMaxValue" SG_ 2348982440 SBCU8_ISO_Allow 3;
BA_ "GenSigSendType" SG_ 2348982440 SBCU8_WorkMode 1;
BA_ "GenSigMaxValue" SG_ 2348982440 SBCU8_WorkMode 15;
BA_ "GenSigSendType" SG_ 2348982440 SBCU8_HV_Step 1;
BA_ "GenSigMaxValue" SG_ 2348982440 SBCU8_HV_Step 15;
BA_ "GenSigSendType" SG_ 2348982440 SBCU8_BMS_RunStatus 1;
BA_ "GenSigMaxValue" SG_ 2348982440 SBCU8_BMS_RunStatus 15;
BA_ "GenSigSendType" SG_ 2348982440 SBCU8_FanRelay_Status 1;
BA_ "GenSigMaxValue" SG_ 2348982440 SBCU8_FanRelay_Status 3;
BA_ "GenSigSendType" SG_ 2348982440 SBCU8_HeatRelay_Status 1;
BA_ "GenSigMaxValue" SG_ 2348982440 SBCU8_HeatRelay_Status 3;
BA_ "GenSigSendType" SG_ 2348982440 SBCU8_PosRelay_Status 1;
BA_ "GenSigMaxValue" SG_ 2348982440 SBCU8_PosRelay_Status 3;
BA_ "GenSigSendType" SG_ 2348982440 SBCU8_NegRelay_Status 1;
BA_ "GenSigMaxValue" SG_ 2348982440 SBCU8_NegRelay_Status 3;
BA_ "GenSigSendType" SG_ 2348982440 SBCU8_PreChgRelay_Status 1;
BA_ "GenSigMaxValue" SG_ 2348982440 SBCU8_PreChgRelay_Status 3;
BA_ "GenSigSendType" SG_ 2348982440 SBCU8_FcgRelay_Status 1;
BA_ "GenSigMaxValue" SG_ 2348982440 SBCU8_FcgRelay_Status 3;
BA_ "GenSigSendType" SG_ 2348982440 SBCU8_DI1_Status 1;
BA_ "GenSigMaxValue" SG_ 2348982440 SBCU8_DI1_Status 1;
BA_ "GenSigSendType" SG_ 2348982440 SBCU8_DI2_Status 1;
BA_ "GenSigMaxValue" SG_ 2348982440 SBCU8_DI2_Status 1;
BA_ "GenSigSendType" SG_ 2348982440 SBCU8_DI3_Status 1;
BA_ "GenSigMaxValue" SG_ 2348982440 SBCU8_DI3_Status 1;
BA_ "GenSigSendType" SG_ 2348982440 SBCU8_DI4_Status 1;
BA_ "GenSigMaxValue" SG_ 2348982440 SBCU8_DI4_Status 1;
BA_ "GenSigSendType" SG_ 2348982440 SBCU8_DO1_Ctrl 1;
BA_ "GenSigMaxValue" SG_ 2348982440 SBCU8_DO1_Ctrl 1;
BA_ "GenSigSendType" SG_ 2348982440 SBCU8_DO2_Ctrl 1;
BA_ "GenSigMaxValue" SG_ 2348982440 SBCU8_DO2_Ctrl 1;
BA_ "GenSigSendType" SG_ 2348982440 SBCU8_PosIso_Optical 1;
BA_ "GenSigMaxValue" SG_ 2348982440 SBCU8_PosIso_Optical 1;
BA_ "GenSigSendType" SG_ 2348982440 SBCU8_NegIso_Optical 1;
BA_ "GenSigMaxValue" SG_ 2348982440 SBCU8_NegIso_Optical 1;
BA_ "GenSigSendType" SG_ 2348982440 SBCU8_FaultCode 1;
BA_ "GenSigMaxValue" SG_ 2348982440 SBCU8_FaultCode 65535;
BA_ "GenSigSendType" SG_ 2348982440 SBCU8_FaultLevel 1;
BA_ "GenSigMaxValue" SG_ 2348982440 SBCU8_FaultLevel 3;
BA_ "GenSigSendType" SG_ 2348982440 SBCU8_Life 1;
BA_ "GenSigMaxValue" SG_ 2348982440 SBCU8_Life 15;
BA_ "GenSigSendType" SG_ 2550505640 SBCU8_DchPeakPower_Limit 1;
BA_ "GenSigMaxValue" SG_ 2550505640 SBCU8_DchPeakPower_Limit 65535;
BA_ "GenSigSendType" SG_ 2550505640 SBCU8_DchContinuousPower_Limit 1;
BA_ "GenSigMaxValue" SG_ 2550505640 SBCU8_DchContinuousPower_Limit 65535;
BA_ "GenSigSendType" SG_ 2550505640 SBCU8_ChgPeakPower_Limit 1;
BA_ "GenSigMaxValue" SG_ 2550505640 SBCU8_ChgPeakPower_Limit 65535;
BA_ "GenSigSendType" SG_ 2550505640 SBCU8_ChgContinuousPower_Limit 1;
BA_ "GenSigMaxValue" SG_ 2550505640 SBCU8_ChgContinuousPower_Limit 65535;
BA_ "GenSigSendType" SG_ 2550440104 SBCU8_DchPeakCurr_Limit 1;
BA_ "GenSigMaxValue" SG_ 2550440104 SBCU8_DchPeakCurr_Limit 65535;
BA_ "GenSigSendType" SG_ 2550440104 SBCU8_DchContinuousCurr_Limit 1;
BA_ "GenSigMaxValue" SG_ 2550440104 SBCU8_DchContinuousCurr_Limit 65535;
BA_ "GenSigSendType" SG_ 2550440104 SBCU8_ChgPeakCurr_Limit 1;
BA_ "GenSigMaxValue" SG_ 2550440104 SBCU8_ChgPeakCurr_Limit 65535;
BA_ "GenSigSendType" SG_ 2550440104 SBCU8_ChgContinuousCurr_Limit 1;
BA_ "GenSigMaxValue" SG_ 2550440104 SBCU8_ChgContinuousCurr_Limit 65535;
BA_ "GenSigSendType" SG_ 2550636712 SBCU8_CellVolt_Max_BMUNO 1;
BA_ "GenSigMaxValue" SG_ 2550636712 SBCU8_CellVolt_Max_BMUNO 255;
BA_ "GenSigSendType" SG_ 2550636712 SBCU8_CellVolt_Max_CellNO 1;
BA_ "GenSigMaxValue" SG_ 2550636712 SBCU8_CellVolt_Max_CellNO 255;
BA_ "GenSigSendType" SG_ 2550636712 SBCU8_CellVolt_Min_BMUNO 1;
BA_ "GenSigMaxValue" SG_ 2550636712 SBCU8_CellVolt_Min_BMUNO 255;
BA_ "GenSigSendType" SG_ 2550636712 SBCU8_CellVolt_Min_CellNO 1;
BA_ "GenSigMaxValue" SG_ 2550636712 SBCU8_CellVolt_Min_CellNO 255;
BA_ "GenSigSendType" SG_ 2550636712 SBCU8_CellTemp_Max_BMUNO 1;
BA_ "GenSigMaxValue" SG_ 2550636712 SBCU8_CellTemp_Max_BMUNO 255;
BA_ "GenSigSendType" SG_ 2550636712 SBCU8_CellTemp_Max_CellNO 1;
BA_ "GenSigMaxValue" SG_ 2550636712 SBCU8_CellTemp_Max_CellNO 255;
BA_ "GenSigSendType" SG_ 2550636712 SBCU8_CellTemp_Min_BMUNO 1;
BA_ "GenSigMaxValue" SG_ 2550636712 SBCU8_CellTemp_Min_BMUNO 255;
BA_ "GenSigSendType" SG_ 2550636712 SBCU8_CellTemp_Min_CellNO 1;
BA_ "GenSigMaxValue" SG_ 2550636712 SBCU8_CellTemp_Min_CellNO 255;
BA_ "GenSigSendType" SG_ 2550571176 SBCU8_CellVolt_Max 1;
BA_ "GenSigMaxValue" SG_ 2550571176 SBCU8_CellVolt_Max 65535;
BA_ "GenSigSendType" SG_ 2550571176 SBCU8_CellVolt_Min 1;
BA_ "GenSigMaxValue" SG_ 2550571176 SBCU8_CellVolt_Min 65535;
BA_ "GenSigSendType" SG_ 2550571176 SBCU8_CellVolt_Mean 1;
BA_ "GenSigMaxValue" SG_ 2550571176 SBCU8_CellVolt_Mean 65535;
BA_ "GenSigSendType" SG_ 2550571176 SBCU8_CellTemp_Max 1;
BA_ "GenSigMaxValue" SG_ 2550571176 SBCU8_CellTemp_Max 255;
BA_ "GenSigSendType" SG_ 2550571176 SBCU8_CellTemp_Min 1;
BA_ "GenSigMaxValue" SG_ 2550571176 SBCU8_CellTemp_Min 255;
BA_ "GenSigSendType" SG_ 2550702248 SBCU8_NTC1 1;
BA_ "GenSigMaxValue" SG_ 2550702248 SBCU8_NTC1 255;
BA_ "GenSigSendType" SG_ 2550702248 SBCU8_NTC2 1;
BA_ "GenSigMaxValue" SG_ 2550702248 SBCU8_NTC2 255;
BA_ "GenSigSendType" SG_ 2550702248 SBCU8_ISO_PosVolt 1;
BA_ "GenSigMaxValue" SG_ 2550702248 SBCU8_ISO_PosVolt 65535;
BA_ "GenSigSendType" SG_ 2550702248 SBCU8_ISO_NegVolt 1;
BA_ "GenSigMaxValue" SG_ 2550702248 SBCU8_ISO_NegVolt 65535;
BA_ "GenSigSendType" SG_ 2550702248 SBCU8_CellVolt_Sum 1;
BA_ "GenSigMaxValue" SG_ 2550702248 SBCU8_CellVolt_Sum 65535;
BA_ "GenSigSendType" SG_ 2566652072 SBCU8_CellBalance001 1;
BA_ "GenSigMaxValue" SG_ 2566652072 SBCU8_CellBalance001 255;
BA_ "GenSigSendType" SG_ 2566652072 SBCU8_CellBalance009 1;
BA_ "GenSigMaxValue" SG_ 2566652072 SBCU8_CellBalance009 255;
BA_ "GenSigSendType" SG_ 2566652072 SBCU8_CellBalance017 1;
BA_ "GenSigMaxValue" SG_ 2566652072 SBCU8_CellBalance017 255;
BA_ "GenSigSendType" SG_ 2566652072 SBCU8_CellBalance025 1;
BA_ "GenSigMaxValue" SG_ 2566652072 SBCU8_CellBalance025 255;
BA_ "GenSigSendType" SG_ 2566652072 SBCU8_CellBalance033 1;
BA_ "GenSigMaxValue" SG_ 2566652072 SBCU8_CellBalance033 255;
BA_ "GenSigSendType" SG_ 2566652072 SBCU8_CellBalance041 1;
BA_ "GenSigMaxValue" SG_ 2566652072 SBCU8_CellBalance041 255;
BA_ "GenSigSendType" SG_ 2566652072 SBCU8_CellBalance049 1;
BA_ "GenSigMaxValue" SG_ 2566652072 SBCU8_CellBalance049 255;
BA_ "GenSigSendType" SG_ 2566652072 SBCU8_CellBalance_Pack_NO 1;
BA_ "GenSigMaxValue" SG_ 2566652072 SBCU8_CellBalance_Pack_NO 255;
BA_ "GenSigSendType" SG_ 2550243496 SBCU8_Pack_Volt 1;
BA_ "GenSigMaxValue" SG_ 2550243496 SBCU8_Pack_Volt 65535;
BA_ "GenSigSendType" SG_ 2550243496 SBCU8_LinkVolt 1;
BA_ "GenSigMaxValue" SG_ 2550243496 SBCU8_LinkVolt 65535;
BA_ "GenSigSendType" SG_ 2550243496 SBCU8_BusCurrent 1;
BA_ "GenSigMaxValue" SG_ 2550243496 SBCU8_BusCurrent 65535;
BA_ "GenSigStartValue" SG_ 2550243496 SBCU8_BusCurrent 32000;
BA_ "GenSigSendType" SG_ 2550243496 SBCU8_SOC 1;
BA_ "GenSigMaxValue" SG_ 2550243496 SBCU8_SOC 65535;
BA_ "GenSigSendType" SG_ 2550898855 SBCU7_Accum_DchEng 1;
BA_ "GenSigMaxValue" SG_ 2550898855 SBCU7_Accum_DchEng 2147483647;
BA_ "GenSigSendType" SG_ 2550898855 SBCU7_Accum_ChgEng 1;
BA_ "GenSigMaxValue" SG_ 2550898855 SBCU7_Accum_ChgEng 2147483647;
BA_ "GenSigSendType" SG_ 2550833319 SBCU7_Accum_DchCap 1;
BA_ "GenSigMaxValue" SG_ 2550833319 SBCU7_Accum_DchCap 2147483647;
BA_ "GenSigSendType" SG_ 2550833319 SBCU7_Accum_ChgCap 1;
BA_ "GenSigMaxValue" SG_ 2550833319 SBCU7_Accum_ChgCap 2147483647;
BA_ "GenSigSendType" SG_ 2550374567 SBCU7_Isolation 1;
BA_ "GenSigMaxValue" SG_ 2550374567 SBCU7_Isolation 65535;
BA_ "GenSigSendType" SG_ 2550374567 SBCU7_SOH 1;
BA_ "GenSigMaxValue" SG_ 2550374567 SBCU7_SOH 4095;
BA_ "GenSigSendType" SG_ 2550374567 SBCU7_PowerSupply_Volt 1;
BA_ "GenSigMaxValue" SG_ 2550374567 SBCU7_PowerSupply_Volt 4095;
BA_ "GenSigSendType" SG_ 2550374567 SBCU7_AI1_Value 1;
BA_ "GenSigMaxValue" SG_ 2550374567 SBCU7_AI1_Value 255;
BA_ "GenSigSendType" SG_ 2550374567 SBCU7_AI2_Value 1;
BA_ "GenSigMaxValue" SG_ 2550374567 SBCU7_AI2_Value 255;
BA_ "GenSigSendType" SG_ 2550374567 SBCU7_AI3_Value 1;
BA_ "GenSigMaxValue" SG_ 2550374567 SBCU7_AI3_Value 255;
BA_ "GenSigSendType" SG_ 2348982439 SBCU7_ISO_Status 1;
BA_ "GenSigMaxValue" SG_ 2348982439 SBCU7_ISO_Status 3;
BA_ "GenSigSendType" SG_ 2348982439 SBCU7_DO3_Ctrl 1;
BA_ "GenSigMaxValue" SG_ 2348982439 SBCU7_DO3_Ctrl 1;
BA_ "GenSigSendType" SG_ 2348982439 SBCU7_DI5_Status 1;
BA_ "GenSigMaxValue" SG_ 2348982439 SBCU7_DI5_Status 1;
BA_ "GenSigSendType" SG_ 2348982439 SBCU7_Ready 1;
BA_ "GenSigMaxValue" SG_ 2348982439 SBCU7_Ready 3;
BA_ "GenSigSendType" SG_ 2348982439 SBCU7_HVOff_Req 1;
BA_ "GenSigMaxValue" SG_ 2348982439 SBCU7_HVOff_Req 3;
BA_ "GenSigSendType" SG_ 2348982439 SBCU7_ISO_Allow 1;
BA_ "GenSigMaxValue" SG_ 2348982439 SBCU7_ISO_Allow 3;
BA_ "GenSigSendType" SG_ 2348982439 SBCU7_WorkMode 1;
BA_ "GenSigMaxValue" SG_ 2348982439 SBCU7_WorkMode 15;
BA_ "GenSigSendType" SG_ 2348982439 SBCU7_HV_Step 1;
BA_ "GenSigMaxValue" SG_ 2348982439 SBCU7_HV_Step 15;
BA_ "GenSigSendType" SG_ 2348982439 SBCU7_BMS_RunStatus 1;
BA_ "GenSigMaxValue" SG_ 2348982439 SBCU7_BMS_RunStatus 15;
BA_ "GenSigSendType" SG_ 2348982439 SBCU7_FanRelay_Status 1;
BA_ "GenSigMaxValue" SG_ 2348982439 SBCU7_FanRelay_Status 3;
BA_ "GenSigSendType" SG_ 2348982439 SBCU7_HeatRelay_Status 1;
BA_ "GenSigMaxValue" SG_ 2348982439 SBCU7_HeatRelay_Status 3;
BA_ "GenSigSendType" SG_ 2348982439 SBCU7_PosRelay_Status 1;
BA_ "GenSigMaxValue" SG_ 2348982439 SBCU7_PosRelay_Status 3;
BA_ "GenSigSendType" SG_ 2348982439 SBCU7_NegRelay_Status 1;
BA_ "GenSigMaxValue" SG_ 2348982439 SBCU7_NegRelay_Status 3;
BA_ "GenSigSendType" SG_ 2348982439 SBCU7_PreChgRelay_Status 1;
BA_ "GenSigMaxValue" SG_ 2348982439 SBCU7_PreChgRelay_Status 3;
BA_ "GenSigSendType" SG_ 2348982439 SBCU7_FcgRelay_Status 1;
BA_ "GenSigMaxValue" SG_ 2348982439 SBCU7_FcgRelay_Status 3;
BA_ "GenSigSendType" SG_ 2348982439 SBCU7_DI1_Status 1;
BA_ "GenSigMaxValue" SG_ 2348982439 SBCU7_DI1_Status 1;
BA_ "GenSigSendType" SG_ 2348982439 SBCU7_DI2_Status 1;
BA_ "GenSigMaxValue" SG_ 2348982439 SBCU7_DI2_Status 1;
BA_ "GenSigSendType" SG_ 2348982439 SBCU7_DI3_Status 1;
BA_ "GenSigMaxValue" SG_ 2348982439 SBCU7_DI3_Status 1;
BA_ "GenSigSendType" SG_ 2348982439 SBCU7_DI4_Status 1;
BA_ "GenSigMaxValue" SG_ 2348982439 SBCU7_DI4_Status 1;
BA_ "GenSigSendType" SG_ 2348982439 SBCU7_DO1_Ctrl 1;
BA_ "GenSigMaxValue" SG_ 2348982439 SBCU7_DO1_Ctrl 1;
BA_ "GenSigSendType" SG_ 2348982439 SBCU7_DO2_Ctrl 1;
BA_ "GenSigMaxValue" SG_ 2348982439 SBCU7_DO2_Ctrl 1;
BA_ "GenSigSendType" SG_ 2348982439 SBCU7_PosIso_Optical 1;
BA_ "GenSigMaxValue" SG_ 2348982439 SBCU7_PosIso_Optical 1;
BA_ "GenSigSendType" SG_ 2348982439 SBCU7_NegIso_Optical 1;
BA_ "GenSigMaxValue" SG_ 2348982439 SBCU7_NegIso_Optical 1;
BA_ "GenSigSendType" SG_ 2348982439 SBCU7_FaultCode 1;
BA_ "GenSigMaxValue" SG_ 2348982439 SBCU7_FaultCode 65535;
BA_ "GenSigSendType" SG_ 2348982439 SBCU7_FaultLevel 1;
BA_ "GenSigMaxValue" SG_ 2348982439 SBCU7_FaultLevel 3;
BA_ "GenSigSendType" SG_ 2348982439 SBCU7_Life 1;
BA_ "GenSigMaxValue" SG_ 2348982439 SBCU7_Life 15;
BA_ "GenSigSendType" SG_ 2550505639 SBCU7_DchPeakPower_Limit 1;
BA_ "GenSigMaxValue" SG_ 2550505639 SBCU7_DchPeakPower_Limit 65535;
BA_ "GenSigSendType" SG_ 2550505639 SBCU7_DchContinuousPower_Limit 1;
BA_ "GenSigMaxValue" SG_ 2550505639 SBCU7_DchContinuousPower_Limit 65535;
BA_ "GenSigSendType" SG_ 2550505639 SBCU7_ChgPeakPower_Limit 1;
BA_ "GenSigMaxValue" SG_ 2550505639 SBCU7_ChgPeakPower_Limit 65535;
BA_ "GenSigSendType" SG_ 2550505639 SBCU7_ChgContinuousPower_Limit 1;
BA_ "GenSigMaxValue" SG_ 2550505639 SBCU7_ChgContinuousPower_Limit 65535;
BA_ "GenSigSendType" SG_ 2550440103 SBCU7_DchPeakCurr_Limit 1;
BA_ "GenSigMaxValue" SG_ 2550440103 SBCU7_DchPeakCurr_Limit 65535;
BA_ "GenSigSendType" SG_ 2550440103 SBCU7_DchContinuousCurr_Limit 1;
BA_ "GenSigMaxValue" SG_ 2550440103 SBCU7_DchContinuousCurr_Limit 65535;
BA_ "GenSigSendType" SG_ 2550440103 SBCU7_ChgPeakCurr_Limit 1;
BA_ "GenSigMaxValue" SG_ 2550440103 SBCU7_ChgPeakCurr_Limit 65535;
BA_ "GenSigSendType" SG_ 2550440103 SBCU7_ChgContinuousCurr_Limit 1;
BA_ "GenSigMaxValue" SG_ 2550440103 SBCU7_ChgContinuousCurr_Limit 65535;
BA_ "GenSigSendType" SG_ 2550636711 SBCU7_CellVolt_Max_BMUNO 1;
BA_ "GenSigMaxValue" SG_ 2550636711 SBCU7_CellVolt_Max_BMUNO 255;
BA_ "GenSigSendType" SG_ 2550636711 SBCU7_CellVolt_Max_CellNO 1;
BA_ "GenSigMaxValue" SG_ 2550636711 SBCU7_CellVolt_Max_CellNO 255;
BA_ "GenSigSendType" SG_ 2550636711 SBCU7_CellVolt_Min_BMUNO 1;
BA_ "GenSigMaxValue" SG_ 2550636711 SBCU7_CellVolt_Min_BMUNO 255;
BA_ "GenSigSendType" SG_ 2550636711 SBCU7_CellVolt_Min_CellNO 1;
BA_ "GenSigMaxValue" SG_ 2550636711 SBCU7_CellVolt_Min_CellNO 255;
BA_ "GenSigSendType" SG_ 2550636711 SBCU7_CellTemp_Max_BMUNO 1;
BA_ "GenSigMaxValue" SG_ 2550636711 SBCU7_CellTemp_Max_BMUNO 255;
BA_ "GenSigSendType" SG_ 2550636711 SBCU7_CellTemp_Max_CellNO 1;
BA_ "GenSigMaxValue" SG_ 2550636711 SBCU7_CellTemp_Max_CellNO 255;
BA_ "GenSigSendType" SG_ 2550636711 SBCU7_CellTemp_Min_BMUNO 1;
BA_ "GenSigMaxValue" SG_ 2550636711 SBCU7_CellTemp_Min_BMUNO 255;
BA_ "GenSigSendType" SG_ 2550636711 SBCU7_CellTemp_Min_CellNO 1;
BA_ "GenSigMaxValue" SG_ 2550636711 SBCU7_CellTemp_Min_CellNO 255;
BA_ "GenSigSendType" SG_ 2550571175 SBCU7_CellVolt_Max 1;
BA_ "GenSigMaxValue" SG_ 2550571175 SBCU7_CellVolt_Max 65535;
BA_ "GenSigSendType" SG_ 2550571175 SBCU7_CellVolt_Min 1;
BA_ "GenSigMaxValue" SG_ 2550571175 SBCU7_CellVolt_Min 65535;
BA_ "GenSigSendType" SG_ 2550571175 SBCU7_CellVolt_Mean 1;
BA_ "GenSigMaxValue" SG_ 2550571175 SBCU7_CellVolt_Mean 65535;
BA_ "GenSigSendType" SG_ 2550571175 SBCU7_CellTemp_Max 1;
BA_ "GenSigMaxValue" SG_ 2550571175 SBCU7_CellTemp_Max 255;
BA_ "GenSigSendType" SG_ 2550571175 SBCU7_CellTemp_Min 1;
BA_ "GenSigMaxValue" SG_ 2550571175 SBCU7_CellTemp_Min 255;
BA_ "GenSigSendType" SG_ 2550702247 SBCU7_NTC1 1;
BA_ "GenSigMaxValue" SG_ 2550702247 SBCU7_NTC1 255;
BA_ "GenSigSendType" SG_ 2550702247 SBCU7_NTC2 1;
BA_ "GenSigMaxValue" SG_ 2550702247 SBCU7_NTC2 255;
BA_ "GenSigSendType" SG_ 2550702247 SBCU7_ISO_PosVolt 1;
BA_ "GenSigMaxValue" SG_ 2550702247 SBCU7_ISO_PosVolt 65535;
BA_ "GenSigSendType" SG_ 2550702247 SBCU7_ISO_NegVolt 1;
BA_ "GenSigMaxValue" SG_ 2550702247 SBCU7_ISO_NegVolt 65535;
BA_ "GenSigSendType" SG_ 2550702247 SBCU7_CellVolt_Sum 1;
BA_ "GenSigMaxValue" SG_ 2550702247 SBCU7_CellVolt_Sum 65535;
BA_ "GenSigSendType" SG_ 2566652071 SBCU7_CellBalance001 1;
BA_ "GenSigMaxValue" SG_ 2566652071 SBCU7_CellBalance001 255;
BA_ "GenSigSendType" SG_ 2566652071 SBCU7_CellBalance009 1;
BA_ "GenSigMaxValue" SG_ 2566652071 SBCU7_CellBalance009 255;
BA_ "GenSigSendType" SG_ 2566652071 SBCU7_CellBalance017 1;
BA_ "GenSigMaxValue" SG_ 2566652071 SBCU7_CellBalance017 255;
BA_ "GenSigSendType" SG_ 2566652071 SBCU7_CellBalance025 1;
BA_ "GenSigMaxValue" SG_ 2566652071 SBCU7_CellBalance025 255;
BA_ "GenSigSendType" SG_ 2566652071 SBCU7_CellBalance033 1;
BA_ "GenSigMaxValue" SG_ 2566652071 SBCU7_CellBalance033 255;
BA_ "GenSigSendType" SG_ 2566652071 SBCU7_CellBalance041 1;
BA_ "GenSigMaxValue" SG_ 2566652071 SBCU7_CellBalance041 255;
BA_ "GenSigSendType" SG_ 2566652071 SBCU7_CellBalance049 1;
BA_ "GenSigMaxValue" SG_ 2566652071 SBCU7_CellBalance049 255;
BA_ "GenSigSendType" SG_ 2566652071 SBCU7_CellBalance_Pack_NO 1;
BA_ "GenSigMaxValue" SG_ 2566652071 SBCU7_CellBalance_Pack_NO 255;
BA_ "GenSigSendType" SG_ 2550243495 SBCU7_Pack_Volt 1;
BA_ "GenSigMaxValue" SG_ 2550243495 SBCU7_Pack_Volt 65535;
BA_ "GenSigSendType" SG_ 2550243495 SBCU7_LinkVolt 1;
BA_ "GenSigMaxValue" SG_ 2550243495 SBCU7_LinkVolt 65535;
BA_ "GenSigSendType" SG_ 2550243495 SBCU7_BusCurrent 1;
BA_ "GenSigMaxValue" SG_ 2550243495 SBCU7_BusCurrent 65535;
BA_ "GenSigStartValue" SG_ 2550243495 SBCU7_BusCurrent 32000;
BA_ "GenSigSendType" SG_ 2550243495 SBCU7_SOC 1;
BA_ "GenSigMaxValue" SG_ 2550243495 SBCU7_SOC 65535;
BA_ "GenSigSendType" SG_ 2550898854 SBCU6_Accum_DchEng 1;
BA_ "GenSigMaxValue" SG_ 2550898854 SBCU6_Accum_DchEng 2147483647;
BA_ "GenSigSendType" SG_ 2550898854 SBCU6_Accum_ChgEng 1;
BA_ "GenSigMaxValue" SG_ 2550898854 SBCU6_Accum_ChgEng 2147483647;
BA_ "GenSigSendType" SG_ 2550833318 SBCU6_Accum_DchCap 1;
BA_ "GenSigMaxValue" SG_ 2550833318 SBCU6_Accum_DchCap 2147483647;
BA_ "GenSigSendType" SG_ 2550833318 SBCU6_Accum_ChgCap 1;
BA_ "GenSigMaxValue" SG_ 2550833318 SBCU6_Accum_ChgCap 2147483647;
BA_ "GenSigSendType" SG_ 2550374566 SBCU6_Isolation 1;
BA_ "GenSigMaxValue" SG_ 2550374566 SBCU6_Isolation 65535;
BA_ "GenSigSendType" SG_ 2550374566 SBCU6_SOH 1;
BA_ "GenSigMaxValue" SG_ 2550374566 SBCU6_SOH 4095;
BA_ "GenSigSendType" SG_ 2550374566 SBCU6_PowerSupply_Volt 1;
BA_ "GenSigMaxValue" SG_ 2550374566 SBCU6_PowerSupply_Volt 4095;
BA_ "GenSigSendType" SG_ 2550374566 SBCU6_AI1_Value 1;
BA_ "GenSigMaxValue" SG_ 2550374566 SBCU6_AI1_Value 255;
BA_ "GenSigSendType" SG_ 2550374566 SBCU6_AI2_Value 1;
BA_ "GenSigMaxValue" SG_ 2550374566 SBCU6_AI2_Value 255;
BA_ "GenSigSendType" SG_ 2550374566 SBCU6_AI3_Value 1;
BA_ "GenSigMaxValue" SG_ 2550374566 SBCU6_AI3_Value 255;
BA_ "GenSigSendType" SG_ 2348982438 SBCU6_ISO_Status 1;
BA_ "GenSigMaxValue" SG_ 2348982438 SBCU6_ISO_Status 3;
BA_ "GenSigSendType" SG_ 2348982438 SBCU6_DO3_Ctrl 1;
BA_ "GenSigMaxValue" SG_ 2348982438 SBCU6_DO3_Ctrl 1;
BA_ "GenSigSendType" SG_ 2348982438 SBCU6_DI5_Status 1;
BA_ "GenSigMaxValue" SG_ 2348982438 SBCU6_DI5_Status 1;
BA_ "GenSigSendType" SG_ 2348982438 SBCU6_Ready 1;
BA_ "GenSigMaxValue" SG_ 2348982438 SBCU6_Ready 3;
BA_ "GenSigSendType" SG_ 2348982438 SBCU6_HVOff_Req 1;
BA_ "GenSigMaxValue" SG_ 2348982438 SBCU6_HVOff_Req 3;
BA_ "GenSigSendType" SG_ 2348982438 SBCU6_ISO_Allow 1;
BA_ "GenSigMaxValue" SG_ 2348982438 SBCU6_ISO_Allow 3;
BA_ "GenSigSendType" SG_ 2348982438 SBCU6_WorkMode 1;
BA_ "GenSigMaxValue" SG_ 2348982438 SBCU6_WorkMode 15;
BA_ "GenSigSendType" SG_ 2348982438 SBCU6_HV_Step 1;
BA_ "GenSigMaxValue" SG_ 2348982438 SBCU6_HV_Step 15;
BA_ "GenSigSendType" SG_ 2348982438 SBCU6_BMS_RunStatus 1;
BA_ "GenSigMaxValue" SG_ 2348982438 SBCU6_BMS_RunStatus 15;
BA_ "GenSigSendType" SG_ 2348982438 SBCU6_FanRelay_Status 1;
BA_ "GenSigMaxValue" SG_ 2348982438 SBCU6_FanRelay_Status 3;
BA_ "GenSigSendType" SG_ 2348982438 SBCU6_HeatRelay_Status 1;
BA_ "GenSigMaxValue" SG_ 2348982438 SBCU6_HeatRelay_Status 3;
BA_ "GenSigSendType" SG_ 2348982438 SBCU6_PosRelay_Status 1;
BA_ "GenSigMaxValue" SG_ 2348982438 SBCU6_PosRelay_Status 3;
BA_ "GenSigSendType" SG_ 2348982438 SBCU6_NegRelay_Status 1;
BA_ "GenSigMaxValue" SG_ 2348982438 SBCU6_NegRelay_Status 3;
BA_ "GenSigSendType" SG_ 2348982438 SBCU6_PreChgRelay_Status 1;
BA_ "GenSigMaxValue" SG_ 2348982438 SBCU6_PreChgRelay_Status 3;
BA_ "GenSigSendType" SG_ 2348982438 SBCU6_FcgRelay_Status 1;
BA_ "GenSigMaxValue" SG_ 2348982438 SBCU6_FcgRelay_Status 3;
BA_ "GenSigSendType" SG_ 2348982438 SBCU6_DI1_Status 1;
BA_ "GenSigMaxValue" SG_ 2348982438 SBCU6_DI1_Status 1;
BA_ "GenSigSendType" SG_ 2348982438 SBCU6_DI2_Status 1;
BA_ "GenSigMaxValue" SG_ 2348982438 SBCU6_DI2_Status 1;
BA_ "GenSigSendType" SG_ 2348982438 SBCU6_DI3_Status 1;
BA_ "GenSigMaxValue" SG_ 2348982438 SBCU6_DI3_Status 1;
BA_ "GenSigSendType" SG_ 2348982438 SBCU6_DI4_Status 1;
BA_ "GenSigMaxValue" SG_ 2348982438 SBCU6_DI4_Status 1;
BA_ "GenSigSendType" SG_ 2348982438 SBCU6_DO1_Ctrl 1;
BA_ "GenSigMaxValue" SG_ 2348982438 SBCU6_DO1_Ctrl 1;
BA_ "GenSigSendType" SG_ 2348982438 SBCU6_DO2_Ctrl 1;
BA_ "GenSigMaxValue" SG_ 2348982438 SBCU6_DO2_Ctrl 1;
BA_ "GenSigSendType" SG_ 2348982438 SBCU6_PosIso_Optical 1;
BA_ "GenSigMaxValue" SG_ 2348982438 SBCU6_PosIso_Optical 1;
BA_ "GenSigSendType" SG_ 2348982438 SBCU6_NegIso_Optical 1;
BA_ "GenSigMaxValue" SG_ 2348982438 SBCU6_NegIso_Optical 1;
BA_ "GenSigSendType" SG_ 2348982438 SBCU6_FaultCode 1;
BA_ "GenSigMaxValue" SG_ 2348982438 SBCU6_FaultCode 65535;
BA_ "GenSigSendType" SG_ 2348982438 SBCU6_FaultLevel 1;
BA_ "GenSigMaxValue" SG_ 2348982438 SBCU6_FaultLevel 3;
BA_ "GenSigSendType" SG_ 2348982438 SBCU6_Life 1;
BA_ "GenSigMaxValue" SG_ 2348982438 SBCU6_Life 15;
BA_ "GenSigSendType" SG_ 2550505638 SBCU6_DchPeakPower_Limit 1;
BA_ "GenSigMaxValue" SG_ 2550505638 SBCU6_DchPeakPower_Limit 65535;
BA_ "GenSigSendType" SG_ 2550505638 SBCU6_DchContinuousPower_Limit 1;
BA_ "GenSigMaxValue" SG_ 2550505638 SBCU6_DchContinuousPower_Limit 65535;
BA_ "GenSigSendType" SG_ 2550505638 SBCU6_ChgPeakPower_Limit 1;
BA_ "GenSigMaxValue" SG_ 2550505638 SBCU6_ChgPeakPower_Limit 65535;
BA_ "GenSigSendType" SG_ 2550505638 SBCU6_ChgContinuousPower_Limit 1;
BA_ "GenSigMaxValue" SG_ 2550505638 SBCU6_ChgContinuousPower_Limit 65535;
BA_ "GenSigSendType" SG_ 2550440102 SBCU6_DchPeakCurr_Limit 1;
BA_ "GenSigMaxValue" SG_ 2550440102 SBCU6_DchPeakCurr_Limit 65535;
BA_ "GenSigSendType" SG_ 2550440102 SBCU6_DchContinuousCurr_Limit 1;
BA_ "GenSigMaxValue" SG_ 2550440102 SBCU6_DchContinuousCurr_Limit 65535;
BA_ "GenSigSendType" SG_ 2550440102 SBCU6_ChgPeakCurr_Limit 1;
BA_ "GenSigMaxValue" SG_ 2550440102 SBCU6_ChgPeakCurr_Limit 65535;
BA_ "GenSigSendType" SG_ 2550440102 SBCU6_ChgContinuousCurr_Limit 1;
BA_ "GenSigMaxValue" SG_ 2550440102 SBCU6_ChgContinuousCurr_Limit 65535;
BA_ "GenSigSendType" SG_ 2550636710 SBCU6_CellVolt_Max_BMUNO 1;
BA_ "GenSigMaxValue" SG_ 2550636710 SBCU6_CellVolt_Max_BMUNO 255;
BA_ "GenSigSendType" SG_ 2550636710 SBCU6_CellVolt_Max_CellNO 1;
BA_ "GenSigMaxValue" SG_ 2550636710 SBCU6_CellVolt_Max_CellNO 255;
BA_ "GenSigSendType" SG_ 2550636710 SBCU6_CellVolt_Min_BMUNO 1;
BA_ "GenSigMaxValue" SG_ 2550636710 SBCU6_CellVolt_Min_BMUNO 255;
BA_ "GenSigSendType" SG_ 2550636710 SBCU6_CellVolt_Min_CellNO 1;
BA_ "GenSigMaxValue" SG_ 2550636710 SBCU6_CellVolt_Min_CellNO 255;
BA_ "GenSigSendType" SG_ 2550636710 SBCU6_CellTemp_Max_BMUNO 1;
BA_ "GenSigMaxValue" SG_ 2550636710 SBCU6_CellTemp_Max_BMUNO 255;
BA_ "GenSigSendType" SG_ 2550636710 SBCU6_CellTemp_Max_CellNO 1;
BA_ "GenSigMaxValue" SG_ 2550636710 SBCU6_CellTemp_Max_CellNO 255;
BA_ "GenSigSendType" SG_ 2550636710 SBCU6_CellTemp_Min_BMUNO 1;
BA_ "GenSigMaxValue" SG_ 2550636710 SBCU6_CellTemp_Min_BMUNO 255;
BA_ "GenSigSendType" SG_ 2550636710 SBCU6_CellTemp_Min_CellNO 1;
BA_ "GenSigMaxValue" SG_ 2550636710 SBCU6_CellTemp_Min_CellNO 255;
BA_ "GenSigSendType" SG_ 2550571174 SBCU6_CellVolt_Max 1;
BA_ "GenSigMaxValue" SG_ 2550571174 SBCU6_CellVolt_Max 65535;
BA_ "GenSigSendType" SG_ 2550571174 SBCU6_CellVolt_Min 1;
BA_ "GenSigMaxValue" SG_ 2550571174 SBCU6_CellVolt_Min 65535;
BA_ "GenSigSendType" SG_ 2550571174 SBCU6_CellVolt_Mean 1;
BA_ "GenSigMaxValue" SG_ 2550571174 SBCU6_CellVolt_Mean 65535;
BA_ "GenSigSendType" SG_ 2550571174 SBCU6_CellTemp_Max 1;
BA_ "GenSigMaxValue" SG_ 2550571174 SBCU6_CellTemp_Max 255;
BA_ "GenSigSendType" SG_ 2550571174 SBCU6_CellTemp_Min 1;
BA_ "GenSigMaxValue" SG_ 2550571174 SBCU6_CellTemp_Min 255;
BA_ "GenSigSendType" SG_ 2550702246 SBCU6_NTC1 1;
BA_ "GenSigMaxValue" SG_ 2550702246 SBCU6_NTC1 255;
BA_ "GenSigSendType" SG_ 2550702246 SBCU6_NTC2 1;
BA_ "GenSigMaxValue" SG_ 2550702246 SBCU6_NTC2 255;
BA_ "GenSigSendType" SG_ 2550702246 SBCU6_ISO_PosVolt 1;
BA_ "GenSigMaxValue" SG_ 2550702246 SBCU6_ISO_PosVolt 65535;
BA_ "GenSigSendType" SG_ 2550702246 SBCU6_ISO_NegVolt 1;
BA_ "GenSigMaxValue" SG_ 2550702246 SBCU6_ISO_NegVolt 65535;
BA_ "GenSigSendType" SG_ 2550702246 SBCU6_CellVolt_Sum 1;
BA_ "GenSigMaxValue" SG_ 2550702246 SBCU6_CellVolt_Sum 65535;
BA_ "GenSigSendType" SG_ 2566652070 SBCU6_CellBalance001 1;
BA_ "GenSigMaxValue" SG_ 2566652070 SBCU6_CellBalance001 255;
BA_ "GenSigSendType" SG_ 2566652070 SBCU6_CellBalance009 1;
BA_ "GenSigMaxValue" SG_ 2566652070 SBCU6_CellBalance009 255;
BA_ "GenSigSendType" SG_ 2566652070 SBCU6_CellBalance017 1;
BA_ "GenSigMaxValue" SG_ 2566652070 SBCU6_CellBalance017 255;
BA_ "GenSigSendType" SG_ 2566652070 SBCU6_CellBalance025 1;
BA_ "GenSigMaxValue" SG_ 2566652070 SBCU6_CellBalance025 255;
BA_ "GenSigSendType" SG_ 2566652070 SBCU6_CellBalance033 1;
BA_ "GenSigMaxValue" SG_ 2566652070 SBCU6_CellBalance033 255;
BA_ "GenSigSendType" SG_ 2566652070 SBCU6_CellBalance041 1;
BA_ "GenSigMaxValue" SG_ 2566652070 SBCU6_CellBalance041 255;
BA_ "GenSigSendType" SG_ 2566652070 SBCU6_CellBalance049 1;
BA_ "GenSigMaxValue" SG_ 2566652070 SBCU6_CellBalance049 255;
BA_ "GenSigSendType" SG_ 2566652070 SBCU6_CellBalance_Pack_NO 1;
BA_ "GenSigMaxValue" SG_ 2566652070 SBCU6_CellBalance_Pack_NO 255;
BA_ "GenSigSendType" SG_ 2550243494 SBCU6_Pack_Volt 1;
BA_ "GenSigMaxValue" SG_ 2550243494 SBCU6_Pack_Volt 65535;
BA_ "GenSigSendType" SG_ 2550243494 SBCU6_LinkVolt 1;
BA_ "GenSigMaxValue" SG_ 2550243494 SBCU6_LinkVolt 65535;
BA_ "GenSigSendType" SG_ 2550243494 SBCU6_BusCurrent 1;
BA_ "GenSigMaxValue" SG_ 2550243494 SBCU6_BusCurrent 65535;
BA_ "GenSigStartValue" SG_ 2550243494 SBCU6_BusCurrent 32000;
BA_ "GenSigSendType" SG_ 2550243494 SBCU6_SOC 1;
BA_ "GenSigMaxValue" SG_ 2550243494 SBCU6_SOC 65535;
BA_ "GenSigSendType" SG_ 2550898853 SBCU5_Accum_DchEng 1;
BA_ "GenSigMaxValue" SG_ 2550898853 SBCU5_Accum_DchEng 2147483647;
BA_ "GenSigSendType" SG_ 2550898853 SBCU5_Accum_ChgEng 1;
BA_ "GenSigMaxValue" SG_ 2550898853 SBCU5_Accum_ChgEng 2147483647;
BA_ "GenSigSendType" SG_ 2550833317 SBCU5_Accum_DchCap 1;
BA_ "GenSigMaxValue" SG_ 2550833317 SBCU5_Accum_DchCap 2147483647;
BA_ "GenSigSendType" SG_ 2550833317 SBCU5_Accum_ChgCap 1;
BA_ "GenSigMaxValue" SG_ 2550833317 SBCU5_Accum_ChgCap 2147483647;
BA_ "GenSigSendType" SG_ 2550374565 SBCU5_Isolation 1;
BA_ "GenSigMaxValue" SG_ 2550374565 SBCU5_Isolation 65535;
BA_ "GenSigSendType" SG_ 2550374565 SBCU5_SOH 1;
BA_ "GenSigMaxValue" SG_ 2550374565 SBCU5_SOH 4095;
BA_ "GenSigSendType" SG_ 2550374565 SBCU5_PowerSupply_Volt 1;
BA_ "GenSigMaxValue" SG_ 2550374565 SBCU5_PowerSupply_Volt 4095;
BA_ "GenSigSendType" SG_ 2550374565 SBCU5_AI1_Value 1;
BA_ "GenSigMaxValue" SG_ 2550374565 SBCU5_AI1_Value 255;
BA_ "GenSigSendType" SG_ 2550374565 SBCU5_AI2_Value 1;
BA_ "GenSigMaxValue" SG_ 2550374565 SBCU5_AI2_Value 255;
BA_ "GenSigSendType" SG_ 2550374565 SBCU5_AI3_Value 1;
BA_ "GenSigMaxValue" SG_ 2550374565 SBCU5_AI3_Value 255;
BA_ "GenSigSendType" SG_ 2348982437 SBCU5_ISO_Status 1;
BA_ "GenSigMaxValue" SG_ 2348982437 SBCU5_ISO_Status 3;
BA_ "GenSigSendType" SG_ 2348982437 SBCU5_DO3_Ctrl 1;
BA_ "GenSigMaxValue" SG_ 2348982437 SBCU5_DO3_Ctrl 1;
BA_ "GenSigSendType" SG_ 2348982437 SBCU5_DI5_Status 1;
BA_ "GenSigMaxValue" SG_ 2348982437 SBCU5_DI5_Status 1;
BA_ "GenSigSendType" SG_ 2348982437 SBCU5_Ready 1;
BA_ "GenSigMaxValue" SG_ 2348982437 SBCU5_Ready 3;
BA_ "GenSigSendType" SG_ 2348982437 SBCU5_HVOff_Req 1;
BA_ "GenSigMaxValue" SG_ 2348982437 SBCU5_HVOff_Req 3;
BA_ "GenSigSendType" SG_ 2348982437 SBCU5_ISO_Allow 1;
BA_ "GenSigMaxValue" SG_ 2348982437 SBCU5_ISO_Allow 3;
BA_ "GenSigSendType" SG_ 2348982437 SBCU5_WorkMode 1;
BA_ "GenSigMaxValue" SG_ 2348982437 SBCU5_WorkMode 15;
BA_ "GenSigSendType" SG_ 2348982437 SBCU5_HV_Step 1;
BA_ "GenSigMaxValue" SG_ 2348982437 SBCU5_HV_Step 15;
BA_ "GenSigSendType" SG_ 2348982437 SBCU5_BMS_RunStatus 1;
BA_ "GenSigMaxValue" SG_ 2348982437 SBCU5_BMS_RunStatus 15;
BA_ "GenSigSendType" SG_ 2348982437 SBCU5_FanRelay_Status 1;
BA_ "GenSigMaxValue" SG_ 2348982437 SBCU5_FanRelay_Status 3;
BA_ "GenSigSendType" SG_ 2348982437 SBCU5_HeatRelay_Status 1;
BA_ "GenSigMaxValue" SG_ 2348982437 SBCU5_HeatRelay_Status 3;
BA_ "GenSigSendType" SG_ 2348982437 SBCU5_PosRelay_Status 1;
BA_ "GenSigMaxValue" SG_ 2348982437 SBCU5_PosRelay_Status 3;
BA_ "GenSigSendType" SG_ 2348982437 SBCU5_NegRelay_Status 1;
BA_ "GenSigMaxValue" SG_ 2348982437 SBCU5_NegRelay_Status 3;
BA_ "GenSigSendType" SG_ 2348982437 SBCU5_PreChgRelay_Status 1;
BA_ "GenSigMaxValue" SG_ 2348982437 SBCU5_PreChgRelay_Status 3;
BA_ "GenSigSendType" SG_ 2348982437 SBCU5_FcgRelay_Status 1;
BA_ "GenSigMaxValue" SG_ 2348982437 SBCU5_FcgRelay_Status 3;
BA_ "GenSigSendType" SG_ 2348982437 SBCU5_DI1_Status 1;
BA_ "GenSigMaxValue" SG_ 2348982437 SBCU5_DI1_Status 1;
BA_ "GenSigSendType" SG_ 2348982437 SBCU5_DI2_Status 1;
BA_ "GenSigMaxValue" SG_ 2348982437 SBCU5_DI2_Status 1;
BA_ "GenSigSendType" SG_ 2348982437 SBCU5_DI3_Status 1;
BA_ "GenSigMaxValue" SG_ 2348982437 SBCU5_DI3_Status 1;
BA_ "GenSigSendType" SG_ 2348982437 SBCU5_DI4_Status 1;
BA_ "GenSigMaxValue" SG_ 2348982437 SBCU5_DI4_Status 1;
BA_ "GenSigSendType" SG_ 2348982437 SBCU5_DO1_Ctrl 1;
BA_ "GenSigMaxValue" SG_ 2348982437 SBCU5_DO1_Ctrl 1;
BA_ "GenSigSendType" SG_ 2348982437 SBCU5_DO2_Ctrl 1;
BA_ "GenSigMaxValue" SG_ 2348982437 SBCU5_DO2_Ctrl 1;
BA_ "GenSigSendType" SG_ 2348982437 SBCU5_PosIso_Optical 1;
BA_ "GenSigMaxValue" SG_ 2348982437 SBCU5_PosIso_Optical 1;
BA_ "GenSigSendType" SG_ 2348982437 SBCU5_NegIso_Optical 1;
BA_ "GenSigMaxValue" SG_ 2348982437 SBCU5_NegIso_Optical 1;
BA_ "GenSigSendType" SG_ 2348982437 SBCU5_FaultCode 1;
BA_ "GenSigMaxValue" SG_ 2348982437 SBCU5_FaultCode 65535;
BA_ "GenSigSendType" SG_ 2348982437 SBCU5_FaultLevel 1;
BA_ "GenSigMaxValue" SG_ 2348982437 SBCU5_FaultLevel 3;
BA_ "GenSigSendType" SG_ 2348982437 SBCU5_Life 1;
BA_ "GenSigMaxValue" SG_ 2348982437 SBCU5_Life 15;
BA_ "GenSigSendType" SG_ 2550505637 SBCU5_DchPeakPower_Limit 1;
BA_ "GenSigMaxValue" SG_ 2550505637 SBCU5_DchPeakPower_Limit 65535;
BA_ "GenSigSendType" SG_ 2550505637 SBCU5_DchContinuousPower_Limit 1;
BA_ "GenSigMaxValue" SG_ 2550505637 SBCU5_DchContinuousPower_Limit 65535;
BA_ "GenSigSendType" SG_ 2550505637 SBCU5_ChgPeakPower_Limit 1;
BA_ "GenSigMaxValue" SG_ 2550505637 SBCU5_ChgPeakPower_Limit 65535;
BA_ "GenSigSendType" SG_ 2550505637 SBCU5_ChgContinuousPower_Limit 1;
BA_ "GenSigMaxValue" SG_ 2550505637 SBCU5_ChgContinuousPower_Limit 65535;
BA_ "GenSigSendType" SG_ 2550440101 SBCU5_DchPeakCurr_Limit 1;
BA_ "GenSigMaxValue" SG_ 2550440101 SBCU5_DchPeakCurr_Limit 65535;
BA_ "GenSigSendType" SG_ 2550440101 SBCU5_DchContinuousCurr_Limit 1;
BA_ "GenSigMaxValue" SG_ 2550440101 SBCU5_DchContinuousCurr_Limit 65535;
BA_ "GenSigSendType" SG_ 2550440101 SBCU5_ChgPeakCurr_Limit 1;
BA_ "GenSigMaxValue" SG_ 2550440101 SBCU5_ChgPeakCurr_Limit 65535;
BA_ "GenSigSendType" SG_ 2550440101 SBCU5_ChgContinuousCurr_Limit 1;
BA_ "GenSigMaxValue" SG_ 2550440101 SBCU5_ChgContinuousCurr_Limit 65535;
BA_ "GenSigSendType" SG_ 2550636709 SBCU5_CellVolt_Max_BMUNO 1;
BA_ "GenSigMaxValue" SG_ 2550636709 SBCU5_CellVolt_Max_BMUNO 255;
BA_ "GenSigSendType" SG_ 2550636709 SBCU5_CellVolt_Max_CellNO 1;
BA_ "GenSigMaxValue" SG_ 2550636709 SBCU5_CellVolt_Max_CellNO 255;
BA_ "GenSigSendType" SG_ 2550636709 SBCU5_CellVolt_Min_BMUNO 1;
BA_ "GenSigMaxValue" SG_ 2550636709 SBCU5_CellVolt_Min_BMUNO 255;
BA_ "GenSigSendType" SG_ 2550636709 SBCU5_CellVolt_Min_CellNO 1;
BA_ "GenSigMaxValue" SG_ 2550636709 SBCU5_CellVolt_Min_CellNO 255;
BA_ "GenSigSendType" SG_ 2550636709 SBCU5_CellTemp_Max_BMUNO 1;
BA_ "GenSigMaxValue" SG_ 2550636709 SBCU5_CellTemp_Max_BMUNO 255;
BA_ "GenSigSendType" SG_ 2550636709 SBCU5_CellTemp_Max_CellNO 1;
BA_ "GenSigMaxValue" SG_ 2550636709 SBCU5_CellTemp_Max_CellNO 255;
BA_ "GenSigSendType" SG_ 2550636709 SBCU5_CellTemp_Min_BMUNO 1;
BA_ "GenSigMaxValue" SG_ 2550636709 SBCU5_CellTemp_Min_BMUNO 255;
BA_ "GenSigSendType" SG_ 2550636709 SBCU5_CellTemp_Min_CellNO 1;
BA_ "GenSigMaxValue" SG_ 2550636709 SBCU5_CellTemp_Min_CellNO 255;
BA_ "GenSigSendType" SG_ 2550571173 SBCU5_CellVolt_Max 1;
BA_ "GenSigMaxValue" SG_ 2550571173 SBCU5_CellVolt_Max 65535;
BA_ "GenSigSendType" SG_ 2550571173 SBCU5_CellVolt_Min 1;
BA_ "GenSigMaxValue" SG_ 2550571173 SBCU5_CellVolt_Min 65535;
BA_ "GenSigSendType" SG_ 2550571173 SBCU5_CellVolt_Mean 1;
BA_ "GenSigMaxValue" SG_ 2550571173 SBCU5_CellVolt_Mean 65535;
BA_ "GenSigSendType" SG_ 2550571173 SBCU5_CellTemp_Max 1;
BA_ "GenSigMaxValue" SG_ 2550571173 SBCU5_CellTemp_Max 255;
BA_ "GenSigSendType" SG_ 2550571173 SBCU5_CellTemp_Min 1;
BA_ "GenSigMaxValue" SG_ 2550571173 SBCU5_CellTemp_Min 255;
BA_ "GenSigSendType" SG_ 2550702245 SBCU5_NTC1 1;
BA_ "GenSigMaxValue" SG_ 2550702245 SBCU5_NTC1 255;
BA_ "GenSigSendType" SG_ 2550702245 SBCU5_NTC2 1;
BA_ "GenSigMaxValue" SG_ 2550702245 SBCU5_NTC2 255;
BA_ "GenSigSendType" SG_ 2550702245 SBCU5_ISO_PosVolt 1;
BA_ "GenSigMaxValue" SG_ 2550702245 SBCU5_ISO_PosVolt 65535;
BA_ "GenSigSendType" SG_ 2550702245 SBCU5_ISO_NegVolt 1;
BA_ "GenSigMaxValue" SG_ 2550702245 SBCU5_ISO_NegVolt 65535;
BA_ "GenSigSendType" SG_ 2550702245 SBCU5_CellVolt_Sum 1;
BA_ "GenSigMaxValue" SG_ 2550702245 SBCU5_CellVolt_Sum 65535;
BA_ "GenSigSendType" SG_ 2566652069 SBCU5_CellBalance001 1;
BA_ "GenSigMaxValue" SG_ 2566652069 SBCU5_CellBalance001 255;
BA_ "GenSigSendType" SG_ 2566652069 SBCU5_CellBalance009 1;
BA_ "GenSigMaxValue" SG_ 2566652069 SBCU5_CellBalance009 255;
BA_ "GenSigSendType" SG_ 2566652069 SBCU5_CellBalance017 1;
BA_ "GenSigMaxValue" SG_ 2566652069 SBCU5_CellBalance017 255;
BA_ "GenSigSendType" SG_ 2566652069 SBCU5_CellBalance025 1;
BA_ "GenSigMaxValue" SG_ 2566652069 SBCU5_CellBalance025 255;
BA_ "GenSigSendType" SG_ 2566652069 SBCU5_CellBalance033 1;
BA_ "GenSigMaxValue" SG_ 2566652069 SBCU5_CellBalance033 255;
BA_ "GenSigSendType" SG_ 2566652069 SBCU5_CellBalance041 1;
BA_ "GenSigMaxValue" SG_ 2566652069 SBCU5_CellBalance041 255;
BA_ "GenSigSendType" SG_ 2566652069 SBCU5_CellBalance049 1;
BA_ "GenSigMaxValue" SG_ 2566652069 SBCU5_CellBalance049 255;
BA_ "GenSigSendType" SG_ 2566652069 SBCU5_CellBalance_Pack_NO 1;
BA_ "GenSigMaxValue" SG_ 2566652069 SBCU5_CellBalance_Pack_NO 255;
BA_ "GenSigSendType" SG_ 2550243493 SBCU5_Pack_Volt 1;
BA_ "GenSigMaxValue" SG_ 2550243493 SBCU5_Pack_Volt 65535;
BA_ "GenSigSendType" SG_ 2550243493 SBCU5_LinkVolt 1;
BA_ "GenSigMaxValue" SG_ 2550243493 SBCU5_LinkVolt 65535;
BA_ "GenSigSendType" SG_ 2550243493 SBCU5_BusCurrent 1;
BA_ "GenSigMaxValue" SG_ 2550243493 SBCU5_BusCurrent 65535;
BA_ "GenSigStartValue" SG_ 2550243493 SBCU5_BusCurrent 32000;
BA_ "GenSigSendType" SG_ 2550243493 SBCU5_SOC 1;
BA_ "GenSigMaxValue" SG_ 2550243493 SBCU5_SOC 65535;
BA_ "GenSigSendType" SG_ 2550898852 SBCU4_Accum_DchEng 1;
BA_ "GenSigMaxValue" SG_ 2550898852 SBCU4_Accum_DchEng 2147483647;
BA_ "GenSigSendType" SG_ 2550898852 SBCU4_Accum_ChgEng 1;
BA_ "GenSigMaxValue" SG_ 2550898852 SBCU4_Accum_ChgEng 2147483647;
BA_ "GenSigSendType" SG_ 2550833316 SBCU4_Accum_DchCap 1;
BA_ "GenSigMaxValue" SG_ 2550833316 SBCU4_Accum_DchCap 2147483647;
BA_ "GenSigSendType" SG_ 2550833316 SBCU4_Accum_ChgCap 1;
BA_ "GenSigMaxValue" SG_ 2550833316 SBCU4_Accum_ChgCap 2147483647;
BA_ "GenSigSendType" SG_ 2550374564 SBCU4_Isolation 1;
BA_ "GenSigMaxValue" SG_ 2550374564 SBCU4_Isolation 65535;
BA_ "GenSigSendType" SG_ 2550374564 SBCU4_SOH 1;
BA_ "GenSigMaxValue" SG_ 2550374564 SBCU4_SOH 4095;
BA_ "GenSigSendType" SG_ 2550374564 SBCU4_PowerSupply_Volt 1;
BA_ "GenSigMaxValue" SG_ 2550374564 SBCU4_PowerSupply_Volt 4095;
BA_ "GenSigSendType" SG_ 2550374564 SBCU4_AI1_Value 1;
BA_ "GenSigMaxValue" SG_ 2550374564 SBCU4_AI1_Value 255;
BA_ "GenSigSendType" SG_ 2550374564 SBCU4_AI2_Value 1;
BA_ "GenSigMaxValue" SG_ 2550374564 SBCU4_AI2_Value 255;
BA_ "GenSigSendType" SG_ 2550374564 SBCU4_AI3_Value 1;
BA_ "GenSigMaxValue" SG_ 2550374564 SBCU4_AI3_Value 255;
